CM_ "AUTOGENERATED FILE, DO NOT EDIT";

CM_ "Imported file _vw_meb_common.dbc starts here";
VERSION ""

NS_ :

BS_:

BU_: BAP_Tester BedienDisp_vo BedienSG_hi CGS DDA Gateway Gateway_PAG GurtMikrofon OTA_FC ZR_High ZR_LIMU ZR_MIB_TOP_ab_Gen3 ZR_Standard

BO_ 64 Airbag_01: 8 Gateway
 SG_ Airbag_01_CRC : 0|8@1+ (1,0) [0|255] "" AWC,BMC_MLBevo,BMS_NV,DCDC_800V_PAG,DCDC_HV,DCDC_HV_02,DCDC_IHEV,FCU_MLBevo_FCEV,Ladegeraet_2,Ladegeraet_Konzern,Sub_Gateway
 SG_ Airbag_01_BZ : 8|4@1+ (1,0) [0|15] "" AWC,BMC_MLBevo,BMS_NV,DCDC_800V_PAG,DCDC_HV,DCDC_HV_02,DCDC_IHEV,FCU_MLBevo_FCEV,Ladegeraet_2,Ladegeraet_Konzern,Sub_Gateway
 SG_ FROM_RGS_Anst : 12|4@1+ (1,0) [0|15] "" FCU_MLBevo_FCEV,Sub_Gateway
 SG_ FROM_Front_Crash : 16|1@1+ (1,0) [0|1] "" FCU_MLBevo_FCEV,Sub_Gateway
 SG_ FROM_Rear_Crash : 17|1@1+ (1,0) [0|1] "" FCU_MLBevo_FCEV,Sub_Gateway
 SG_ FROM_SF_Crash : 18|1@1+ (1,0) [0|1] "" FCU_MLBevo_FCEV,Sub_Gateway
 SG_ FROM_SB_Crash : 19|1@1+ (1,0) [0|1] "" FCU_MLBevo_FCEV,Sub_Gateway
 SG_ FROM_Rollover_Crash : 20|1@1+ (1,0) [0|1] "" FCU_MLBevo_FCEV,Sub_Gateway
 SG_ FROM_Crash_Int : 21|3@1+ (1,0) [0|7] "" FCU_MLBevo_FCEV,Sub_Gateway,TME
 SG_ FROM_Lamp : 24|1@1+ (1,0) [0|1] "" FCU_MLBevo_FCEV,Sub_Gateway
 SG_ FROM_Deactivated : 25|1@1+ (1,0) [0|1] "" FCU_MLBevo_FCEV,Sub_Gateway
 SG_ FROM_VB_Deactivated : 26|1@1+ (1,0) [0|1] "" FCU_MLBevo_FCEV,Sub_Gateway
 SG_ FROM_SystemError : 27|1@1+ (1,0) [0|1] "" FCU_MLBevo_FCEV,Sub_Gateway
 SG_ FROM_Diagnostics : 28|1@1+ (1,0) [0|1] "" FCU_MLBevo_FCEV,Sub_Gateway
 SG_ FROM_ActuatorTest : 29|1@1+ (1,0) [0|1] "" FCU_MLBevo_FCEV,Sub_Gateway,TME
 SG_ FROM_Erh_Open_VB : 30|2@1+ (1,0) [0|3] "" FCU_MLBevo_FCEV,Sub_Gateway
 SG_ FROM_BeltWarn_VF : 32|1@1+ (1,0) [0|1] "" FCU_MLBevo_FCEV,Sub_Gateway
 SG_ FROM_BeltWarn_VB : 33|1@1+ (1,0) [0|1] "" FCU_MLBevo_FCEV,Sub_Gateway
 SG_ FROM_Display_Pedestrian : 34|2@1+ (1,0) [0|3] "" FCU_MLBevo_FCEV,Sub_Gateway
 SG_ FROM_Texte_AKS : 36|2@1+ (1,0) [0|3] "" FCU_MLBevo_FCEV,Sub_Gateway
 SG_ FROM_MKB_Valid : 39|1@1+ (1,0) [0|1] "" FCU_MLBevo_FCEV,Sub_Gateway
 SG_ FROM_MKB_Request : 40|1@1+ (1,0) [0|1] "" FCU_MLBevo_FCEV,Sub_Gateway
 SG_ FROM_SupplyVoltage : 41|1@1+ (1,0) [0|1] "" FCU_MLBevo_FCEV,Sub_Gateway
 SG_ FROM_Deactivation_HV : 42|3@1+ (1,0) [0|7] "" AWC,BMC_MLBevo,BMS_NV,DCDC_800V_PAG,DCDC_HV,DCDC_HV_02,DCDC_IHEV,FCU_MLBevo_FCEV,Ladegeraet_2,Ladegeraet_Konzern,Sub_Gateway,TME
 SG_ FROM_EDR_Trigger : 45|2@1+ (1,0) [0|3] "" FCU_MLBevo_FCEV,Sub_Gateway
 SG_ FROM_Occupancy_VF : 47|2@1+ (1,0) [0|3] "" FCU_MLBevo_FCEV,Sub_Gateway
 SG_ SC_MasterTime_Offset : 53|2@1+ (5.08,0) [0|15.24] "Unit_Secon" FCU_MLBevo_FCEV,Sub_Gateway
 SG_ SC_LowSpeedCrashDetected : 55|2@1+ (1,0) [0|3] "" FCU_MLBevo_FCEV,Sub_Gateway
 SG_ SC_MasterTime : 57|7@1+ (0.04,0) [0|5.04] "Unit_Secon" FCU_MLBevo_FCEV,Sub_Gateway

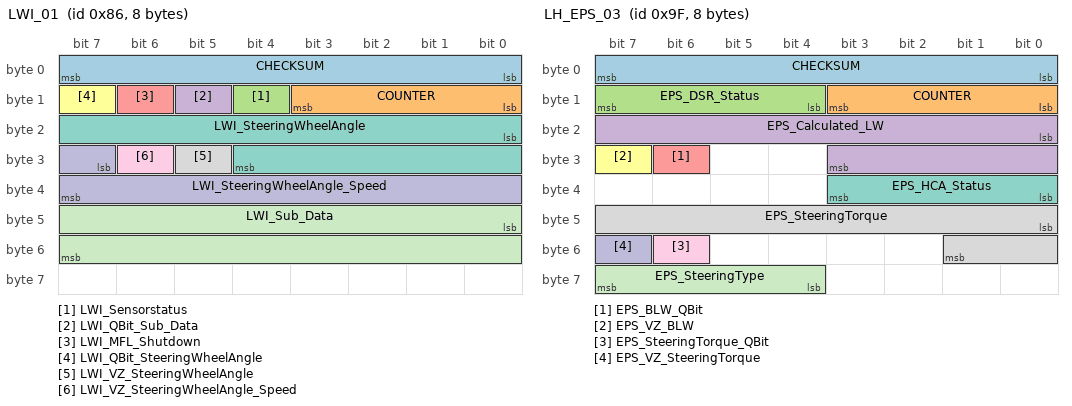
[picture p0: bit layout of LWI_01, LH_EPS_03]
BO_ 134 LWI_01: 8 Gateway
 SG_ CHECKSUM : 0|8@1+ (1,0) [0|255] "" Vector__XXX
 SG_ COUNTER : 8|4@1+ (1,0) [0|15] "" Vector__XXX
 SG_ LWI_Sensorstatus : 12|1@1+ (1,0) [0|1] "" ZR_High,ZR_LIMU,ZR_MIB_TOP_ab_Gen3,ZR_Standard
 SG_ LWI_QBit_Sub_Data : 13|1@1+ (1,0) [0|1] "" ZR_High
 SG_ LWI_MFL_Shutdown : 14|1@1+ (1,0) [0|1] "" ZR_High
 SG_ LWI_QBit_SteeringWheelAngle : 15|1@1+ (1,0) [0|1] "" ZR_High,ZR_LIMU,ZR_MIB_TOP_ab_Gen3,ZR_Standard
 SG_ LWI_SteeringWheelAngle : 16|13@1+ (0.0843,0) [0|800] "Unit_DegreOfArc" OTA_FC,ZR_High,ZR_LIMU,ZR_MIB_TOP_ab_Gen3,ZR_Standard
 SG_ LWI_VZ_SteeringWheelAngle : 29|1@1+ (1,0) [0|1] "" OTA_FC,ZR_High,ZR_LIMU,ZR_MIB_TOP_ab_Gen3,ZR_Standard
 SG_ LWI_VZ_SteeringWheelAngle_Speed : 30|1@1+ (1,0) [0|1] "" ZR_High
 SG_ LWI_SteeringWheelAngle_Speed : 31|9@1+ (5,0) [0|2500] "Unit_DegreOfArcPerSecon" OTA_FC,ZR_High
 SG_ LWI_Sub_Data : 40|16@1+ (1,0) [0|65535] "" Vector__XXX

BO_ 159 LH_EPS_03: 8 XXX
 SG_ CHECKSUM : 0|8@1+ (1,0) [0|255] "" XXX
 SG_ COUNTER : 8|4@1+ (1,0) [0|15] "" XXX
 SG_ EPS_DSR_Status : 12|4@1+ (1,0) [0|15] "" XXX
 SG_ EPS_Calculated_LW : 16|12@1+ (0.15,0) [0|613.95] "Unit_DegreOfArc" XXX
 SG_ EPS_BLW_QBit : 30|1@1+ (1,0) [0|1] "" XXX
 SG_ EPS_VZ_BLW : 31|1@1+ (1,0) [0|1] "" XXX
 SG_ EPS_HCA_Status : 32|4@1+ (1,0) [0|15] "" XXX
 SG_ EPS_SteeringTorque : 40|10@1+ (1,0) [0|8] "Unit_centiNewtoMeter" XXX
 SG_ EPS_SteeringTorque_QBit : 54|1@1+ (1,0) [0|1] "" XXX
 SG_ EPS_VZ_SteeringTorque : 55|1@1+ (1,0) [0|1] "" XXX
 SG_ EPS_SteeringType : 60|4@1+ (1,0) [0|15] "" XXX

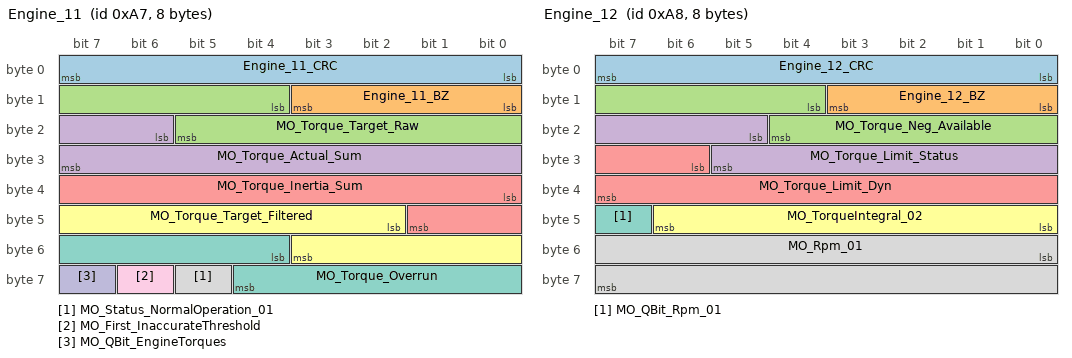
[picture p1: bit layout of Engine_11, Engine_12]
BO_ 167 Engine_11: 8 Motor_Diesel_MQB
 SG_ Engine_11_CRC : 0|8@1+ (1,0) [0|255] "" Gateway_MQB,Getriebe_DQ_Hybrid_MQB,Getriebe_DQ_MQB
 SG_ Engine_11_BZ : 8|4@1+ (1,0) [0|15] "" Gateway_MQB,Getriebe_DQ_Hybrid_MQB,Getriebe_DQ_MQB
 SG_ MO_Torque_Target_Raw : 12|10@1+ (1,-509) [-509|509] "Unit_NewtoMeter" Gateway_MQB,Getriebe_DQ_Hybrid_MQB,Getriebe_DQ_MQB
 SG_ MO_Torque_Actual_Sum : 22|10@1+ (1,-509) [-509|509] "Unit_NewtoMeter" Gateway_MQB,Getriebe_DQ_Hybrid_MQB,Getriebe_DQ_MQB,SAK_MQB
 SG_ MO_Torque_Inertia_Sum : 32|10@1+ (1,-509) [-509|509] "Unit_NewtoMeter" Gateway_MQB,Getriebe_DQ_Hybrid_MQB,Getriebe_DQ_MQB
 SG_ MO_Torque_Target_Filtered : 42|10@1+ (1,-509) [-509|509] "Unit_NewtoMeter" Gateway_MQB,Getriebe_DQ_Hybrid_MQB,Getriebe_DQ_MQB
 SG_ MO_Torque_Overrun : 52|9@1+ (1,-509) [-509|0] "Unit_NewtoMeter" Gateway_MQB,Getriebe_DQ_Hybrid_MQB,Getriebe_DQ_MQB
 SG_ MO_Status_NormalOperation_01 : 61|1@1+ (1,0) [0|1] "" Gateway_MQB,Getriebe_DQ_Hybrid_MQB,Getriebe_DQ_MQB
 SG_ MO_First_InaccurateThreshold : 62|1@1+ (1,0) [0|1] "" Gateway_MQB
 SG_ MO_QBit_EngineTorques : 63|1@1+ (1,0) [0|1] "" Gateway_MQB,Getriebe_DQ_Hybrid_MQB,Getriebe_DQ_MQB

BO_ 168 Engine_12: 8 Motor_Diesel_MQB
 SG_ Engine_12_CRC : 0|8@1+ (1,0) [0|255] "" Gateway_MQB,Getriebe_DQ_Hybrid_MQB,Getriebe_DQ_MQB,LEH_MQB
 SG_ Engine_12_BZ : 8|4@1+ (1,0) [0|15] "" BMS_MQB,Gateway_MQB,Getriebe_DQ_Hybrid_MQB,Getriebe_DQ_MQB,LEH_MQB
 SG_ MO_Torque_Neg_Available : 12|9@1+ (1,-509) [-509|0] "Unit_NewtoMeter" Gateway_MQB
 SG_ MO_Torque_Limit_Status : 21|9@1+ (1,0) [0|509] "Unit_NewtoMeter" Gateway_MQB,Getriebe_DQ_Hybrid_MQB,Getriebe_DQ_MQB
 SG_ MO_Torque_Limit_Dyn : 30|10@1+ (1,-509) [-509|509] "Unit_NewtoMeter" Gateway_MQB
 SG_ MO_TorqueIntegral_02 : 40|7@1+ (1,0) [0|100] "Unit_PerCent" Gateway_MQB,Getriebe_DQ_Hybrid_MQB,Getriebe_DQ_MQB
 SG_ MO_QBit_Rpm_01 : 47|1@1+ (1,0) [0|1] "" BMS_MQB,Gateway_MQB,Getriebe_DQ_Hybrid_MQB,Getriebe_DQ_MQB,LEH_MQB
 SG_ MO_Rpm_01 : 48|16@1+ (0.25,0) [0|16383] "Unit_MinutInver" BMS_MQB,Gateway_MQB,Getriebe_DQ_Hybrid_MQB,Getriebe_DQ_MQB,LEH_MQB,SAK_MQB

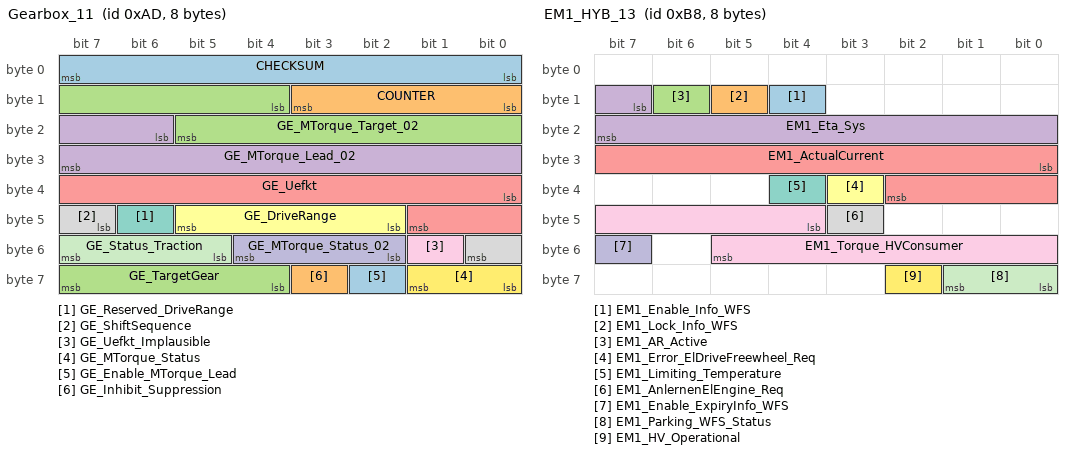
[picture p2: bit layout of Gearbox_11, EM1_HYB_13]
BO_ 173 Gearbox_11: 8 Gateway
 SG_ CHECKSUM : 0|8@1+ (1,0) [0|255] "" Vector__XXX
 SG_ COUNTER : 8|4@1+ (1,0) [0|15] "" Vector__XXX
 SG_ GE_MTorque_Target_02 : 12|10@1+ (1,-509) [-509|509] "" Vector__XXX
 SG_ GE_MTorque_Lead_02 : 22|10@1+ (1,-509) [-509|509] "" Vector__XXX
 SG_ GE_Uefkt : 32|10@1+ (0.1,0) [0|102.2] "" Vector__XXX
 SG_ GE_DriveRange : 42|4@1+ (1,0) [0|15] "" DDA,OTA_FC,ZR_High,ZR_LIMU,ZR_MIB_TOP_ab_Gen3
 SG_ GE_Reserved_DriveRange : 46|1@1+ (1,0) [0|1] "" Vector__XXX
 SG_ GE_ShiftSequence : 47|2@1+ (1,0) [0|3] "" Vector__XXX
 SG_ GE_Uefkt_Implausible : 49|1@1+ (1,0) [0|1] "" Vector__XXX
 SG_ GE_MTorque_Status_02 : 50|3@1+ (1,0) [0|7] "" Vector__XXX
 SG_ GE_Status_Traction : 53|3@1+ (1,0) [0|7] "" Vector__XXX
 SG_ GE_MTorque_Status : 56|2@1+ (1,0) [0|3] "" Vector__XXX
 SG_ GE_Enable_MTorque_Lead : 58|1@1+ (1,0) [0|1] "" Vector__XXX
 SG_ GE_Inhibit_Suppression : 59|1@1+ (1,0) [0|1] "" Vector__XXX
 SG_ GE_TargetGear : 60|4@1+ (1,0) [0|15] "" OTA_FC,ZR_High

BO_ 184 EM1_HYB_13: 8 Gateway
 SG_ EM1_Enable_Info_WFS : 12|1@1+ (1,0) [0|1] "" Sub_Gateway
 SG_ EM1_Lock_Info_WFS : 13|1@1+ (1,0) [0|1] "" Sub_Gateway
 SG_ EM1_AR_Active : 14|1@1+ (1,0) [0|1] "" Sub_Gateway
 SG_ EM1_Eta_Sys : 15|9@1+ (0.2,0) [0|101.8] "Unit_PerCent" Sub_Gateway
 SG_ EM1_ActualCurrent : 24|11@1+ (1,-1023) [-1023|1022] "Unit_Amper" Sub_Gateway
 SG_ EM1_Error_ElDriveFreewheel_Req : 35|1@1+ (1,0) [0|1] "" Sub_Gateway
 SG_ EM1_Limiting_Temperature : 36|1@1+ (1,0) [0|1] "" Sub_Gateway
 SG_ EM1_AnlernenElEngine_Req : 43|1@1+ (1,0) [0|1] "" Sub_Gateway
 SG_ EM1_Torque_HVConsumer : 44|10@1+ (1,-511) [-511|511] "Unit_NewtoMeter" Sub_Gateway
 SG_ EM1_Enable_ExpiryInfo_WFS : 55|1@1+ (1,0) [0|1] "" Sub_Gateway
 SG_ EM1_Parking_WFS_Status : 56|2@1+ (1,0) [0|3] "" Sub_Gateway
 SG_ EM1_HV_Operational : 58|1@1+ (1,0) [0|1] "" Sub_Gateway

BO_ 192 EM1_01: 32 XXX
 SG_ OverrunOperation : 79|1@0+ (1,0) [0|1] "" XXX

BO_ 219 AWV_03: 48 XXX
 SG_ CHECKSUM : 0|8@1+ (1,0) [0|255] "" XXX
 SG_ COUNTER : 8|4@1+ (1,0) [0|15] "" XXX
 SG_ AEB_Object_Status : 12|3@1+ (1,0) [0|7] "" XXX
 SG_ VRU_Detected : 15|1@1+ (1,0) [0|1] "" XXX
 SG_ AWV_Unavailable : 17|1@1+ (1,0) [0|1] "" XXX
 SG_ Unknown_18 : 18|6@1+ (1,0) [0|63] "" XXX
 SG_ AEB_Object_Status_B : 24|3@1+ (1,0) [0|7] "" XXX
 SG_ Unknown_27 : 27|5@1+ (1,0) [0|31] "" XXX
 SG_ SET_ME_254 : 32|8@1+ (1,0) [0|255] "" XXX
 SG_ AEB_TTC_Countdown : 40|8@1+ (1,0) [0|255] "" XXX
 SG_ Active : 64|1@1+ (1,0) [0|1] "" XXX
 SG_ AEB_Active : 65|1@1+ (1,0) [0|1] "" XXX
 SG_ AEB_Target_Decel : 66|10@1+ (0.01,-10.23) [-10.23|0] "Unit_MeterPerSeconSquar" XXX
 SG_ FCW_Active : 76|1@1+ (1,0) [0|1] "" XXX
 SG_ Unknown_80 : 80|8@1+ (1,0) [0|255] "" XXX
 SG_ AEB_Active_2 : 91|1@1+ (1,0) [0|1] "" XXX
 SG_ Unknown_93 : 93|7@1+ (1,0) [0|127] "" XXX
 SG_ Unknown_100 : 100|4@1+ (1,0) [0|15] "" XXX
 SG_ AWV_Init_Status : 128|2@1+ (1,0) [0|3] "" XXX
 SG_ Unknown_192 : 192|1@1+ (1,0) [0|1] "" XXX

BO_ 247 MEB_HVEM_02: 8 XXX
 SG_ CRC : 0|8@1+ (1,0) [0|255] "" XXX
 SG_ CNT : 8|4@1+ (1,0) [0|15] "" XXX

BO_ 253 ESP_21: 8 Gateway
 SG_ CHECKSUM : 0|8@1+ (1,0) [0|255] "" Vector__XXX
 SG_ COUNTER : 8|4@1+ (1,0) [0|15] "" Vector__XXX
 SG_ BR_InterventionTorque : 12|10@1+ (1,-509) [-509|509] "" Vector__XXX
 SG_ ESP_Diagnostics : 23|1@1+ (1,0) [0|1] "" ZR_High
 SG_ ESC_v_Signal_Qualifier_High_Low : 24|3@1+ (1,0) [0|7] "" Vector__XXX
 SG_ ESP_BeforeControl : 28|1@1+ (1,0) [0|1] "" Vector__XXX
 SG_ OBD_RoughRoad : 30|1@1+ (1,0) [0|1] "" ZR_High
 SG_ OBD_QBit_RoughRoad : 31|1@1+ (1,0) [0|1] "" ZR_High
 SG_ ESP_v_Signal : 32|16@1+ (0.01,0) [0|655.32] "Unit_KiloMeterPerHour" BedienSG_hi,DDA,OTA_FC,ZR_High,ZR_LIMU,ZR_MIB_TOP_ab_Gen3,ZR_Standard
 SG_ ASR_Keying_Passive : 48|1@1+ (1,0) [0|1] "" OTA_FC
 SG_ ESP_Keying_Passive : 49|1@1+ (1,0) [0|1] "" OTA_FC,ZR_High,ZR_LIMU,ZR_MIB_TOP_ab_Gen3
 SG_ ESP_SystemStatus : 50|1@1+ (1,0) [0|1] "" OTA_FC
 SG_ ASR_ShiftIntervention : 51|2@1+ (1,0) [0|3] "" Vector__XXX
 SG_ ESP_QBit_v_Signal : 55|1@1+ (1,0) [0|1] "" ZR_High,ZR_LIMU,ZR_MIB_TOP_ab_Gen3,ZR_Standard
 SG_ ABS_Braking : 56|1@1+ (1,0) [0|1] "" OTA_FC,ZR_High,ZR_LIMU,ZR_MIB_TOP_ab_Gen3
 SG_ ASR_Req : 57|1@1+ (1,0) [0|1] "" ZR_High
 SG_ MSR_Req : 58|1@1+ (1,0) [0|1] "" OTA_FC,ZR_High
 SG_ EBV_Intervention : 59|1@1+ (1,0) [0|1] "" Vector__XXX
 SG_ EDS_Intervention : 60|1@1+ (1,0) [0|1] "" Vector__XXX
 SG_ ESP_Intervention : 61|1@1+ (1,0) [0|1] "" OTA_FC,ZR_High
 SG_ ESP_ASP : 62|1@1+ (1,0) [0|1] "" ZR_High
 SG_ ESC_NeutralShift : 63|1@1+ (1,0) [0|1] "" Vector__XXX

BO_ 258 ESC_50: 48 XXX
 SG_ CHECKSUM : 0|8@1+ (1,0) [0|255] "" XXX
 SG_ COUNTER : 8|4@1+ (1,0) [0|15] "" XXX
 SG_ Lateral_Accel : 16|8@1+ (0.15,-18.9) [0|255] "Unit_MeterPerSquareSecond" XXX
 SG_ Longitudinal_Accel : 24|10@1+ (0.03125,-16) [0|255] "Unit_MeterPerSquareSecond" XXX
 SG_ Yaw_Rate : 40|14@1+ (0.01,0) [0|16383] "Unit_DegreePerSecond" XXX
 SG_ Yaw_Rate_Sign : 54|1@0+ (1,0) [0|1] "" XXX
 SG_ Brake_Power : 80|8@1+ (1,-100) [0|255] "" XXX
 SG_ Brake_01 : 90|1@0+ (1,0) [0|1] "" XXX
 SG_ Rain_Braking : 123|1@1+ (1,0) [0|7] "" XXX
 SG_ Brake_02 : 125|1@0+ (1,0) [0|1] "" XXX
 SG_ Standstill : 171|1@0+ (1,0) [0|1] "" XXX
 SG_ Motion_State : 171|2@0+ (1,0) [0|1] "" XXX
 SG_ Longitudinal_Speed : 181|10@1+ (0.25,0) [0|255] "Unit_KilometerPerHour" XXX
 SG_ Brake_Power_02 : 226|8@1+ (1,-100) [0|63] "" XXX
 SG_ EPB_Status : 317|3@1+ (1,0) [0|7] "" XXX

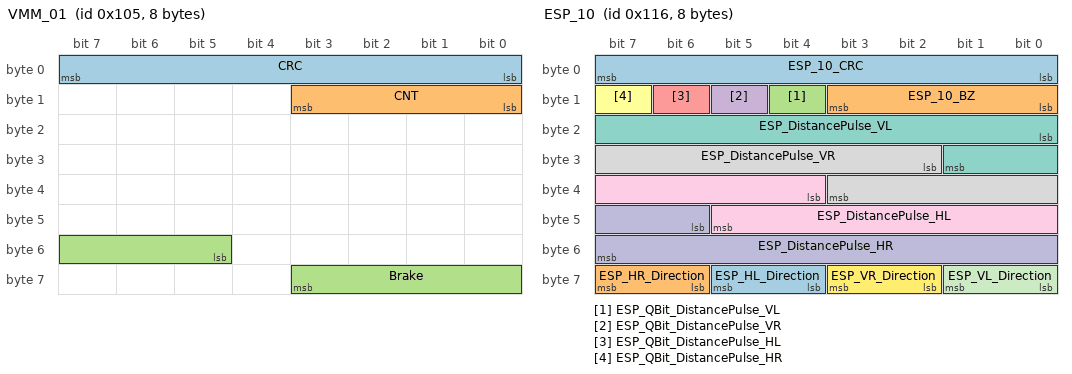
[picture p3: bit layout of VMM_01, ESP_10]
BO_ 261 VMM_01: 8 XXX
 SG_ CRC : 0|8@1+ (1,0) [0|255] "" XXX
 SG_ CNT : 8|4@1+ (1,0) [0|15] "" XXX
 SG_ Brake : 53|7@1+ (1,0) [0|3] "" XXX

BO_ 278 ESP_10: 8 Gateway_MQB
 SG_ ESP_10_CRC : 0|8@1+ (1,0) [0|255] "" Airbag_MQB,Motor_Diesel_MQB,Motor_Hybrid_MQB,Motor_Otto_MQB
 SG_ ESP_10_BZ : 8|4@1+ (1,0) [0|15] "" Airbag_MQB,Motor_Diesel_MQB,Motor_Hybrid_MQB,Motor_Otto_MQB
 SG_ ESP_QBit_DistancePulse_VL : 12|1@1+ (1,0) [0|1] "" Getriebe_DQ_Hybrid_MQB,Getriebe_DQ_MQB,Motor_Diesel_MQB,Motor_Hybrid_MQB,Motor_Otto_MQB
 SG_ ESP_QBit_DistancePulse_VR : 13|1@1+ (1,0) [0|1] "" Getriebe_DQ_Hybrid_MQB,Getriebe_DQ_MQB,Motor_Diesel_MQB,Motor_Hybrid_MQB,Motor_Otto_MQB
 SG_ ESP_QBit_DistancePulse_HL : 14|1@1+ (1,0) [0|1] "" Getriebe_DQ_Hybrid_MQB,Getriebe_DQ_MQB,Motor_Diesel_MQB,Motor_Hybrid_MQB,Motor_Otto_MQB
 SG_ ESP_QBit_DistancePulse_HR : 15|1@1+ (1,0) [0|1] "" Getriebe_DQ_Hybrid_MQB,Getriebe_DQ_MQB,Motor_Diesel_MQB,Motor_Hybrid_MQB,Motor_Otto_MQB
 SG_ ESP_DistancePulse_VL : 16|10@1+ (1,0) [0|1000] "" Getriebe_DQ_Hybrid_MQB,Getriebe_DQ_MQB,Motor_Diesel_MQB,Motor_Hybrid_MQB,Motor_Otto_MQB
 SG_ ESP_DistancePulse_VR : 26|10@1+ (1,0) [0|1000] "" Getriebe_DQ_Hybrid_MQB,Getriebe_DQ_MQB,Motor_Diesel_MQB,Motor_Hybrid_MQB,Motor_Otto_MQB
 SG_ ESP_DistancePulse_HL : 36|10@1+ (1,0) [0|1000] "" Getriebe_DQ_Hybrid_MQB,Getriebe_DQ_MQB,Motor_Diesel_MQB,Motor_Hybrid_MQB,Motor_Otto_MQB
 SG_ ESP_DistancePulse_HR : 46|10@1+ (1,0) [0|1000] "" Getriebe_DQ_Hybrid_MQB,Getriebe_DQ_MQB,Motor_Diesel_MQB,Motor_Hybrid_MQB,Motor_Otto_MQB
 SG_ ESP_VL_Direction : 56|2@1+ (1,0) [0|3] "" Airbag_MQB,Getriebe_DQ_Hybrid_MQB,Getriebe_DQ_MQB,Motor_Diesel_MQB,Motor_Hybrid_MQB,Motor_Otto_MQB
 SG_ ESP_VR_Direction : 58|2@1+ (1,0) [0|3] "" Airbag_MQB,Getriebe_DQ_Hybrid_MQB,Getriebe_DQ_MQB,Motor_Diesel_MQB,Motor_Hybrid_MQB,Motor_Otto_MQB
 SG_ ESP_HL_Direction : 60|2@1+ (1,0) [0|3] "" Airbag_MQB,Getriebe_DQ_Hybrid_MQB,Getriebe_DQ_MQB,Motor_Diesel_MQB,Motor_Hybrid_MQB,Motor_Otto_MQB
 SG_ ESP_HR_Direction : 62|2@1+ (1,0) [0|3] "" Airbag_MQB,Getriebe_DQ_Hybrid_MQB,Getriebe_DQ_MQB,Motor_Diesel_MQB,Motor_Hybrid_MQB,Motor_Otto_MQB

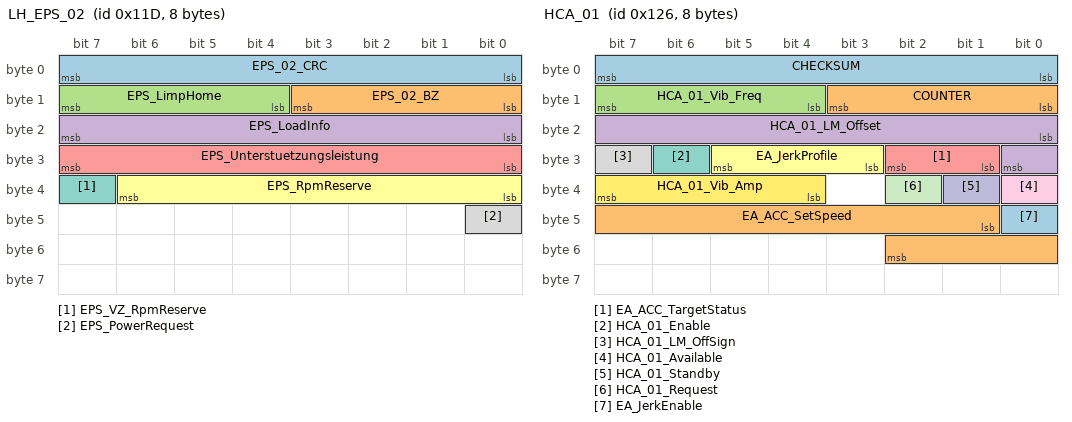
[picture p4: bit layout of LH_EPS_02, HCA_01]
BO_ 285 LH_EPS_02: 8 Gateway_D4C7
 SG_ EPS_02_CRC : 0|8@1+ (1,0) [0|255] "" SCU_D4
 SG_ EPS_02_BZ : 8|4@1+ (1,0) [0|15] "" SCU_D4
 SG_ EPS_LimpHome : 12|4@1+ (1,0) [0|15] "" Vector__XXX
 SG_ EPS_LoadInfo : 16|8@1+ (1,0) [0|253] "Unit_Amper" Vector__XXX
 SG_ EPS_Unterstuetzungsleistung : 24|8@1+ (0.5,0) [0|100] "Unit_PerCent" SCU_D4
 SG_ EPS_RpmReserve : 32|7@1+ (10,0) [0|1000] "Unit_DegreOfArcPerSecon" SCU_D4
 SG_ EPS_VZ_RpmReserve : 39|1@1+ (1,0) [0|1] "" SCU_D4
 SG_ EPS_PowerRequest : 40|1@1+ (1,0) [0|1] "" Vector__XXX

BO_ 294 HCA_01: 8 Frontsensorik
 SG_ CHECKSUM : 0|8@1+ (1,0) [0|255] "" Vector__XXX
 SG_ COUNTER : 8|4@1+ (1,0) [0|15] "" Vector__XXX
 SG_ HCA_01_Vib_Freq : 12|4@1+ (1,15) [18|30] "Unit_Hertz" Vector__XXX
 SG_ HCA_01_LM_Offset : 16|9@1+ (1,0) [0|511] "Unit_centiNewtoMeter" Vector__XXX
 SG_ EA_ACC_TargetStatus : 25|2@1+ (1,0) [0|3] "" Frontradar
 SG_ EA_JerkProfile : 27|3@1+ (1,0) [0|7] "" Vector__XXX
 SG_ HCA_01_Enable : 30|1@1+ (1,0) [0|1] "" Vector__XXX
 SG_ HCA_01_LM_OffSign : 31|1@1+ (1,0) [0|1] "" Vector__XXX
 SG_ HCA_01_Available : 32|1@1+ (1,0) [0|1] "" Vector__XXX
 SG_ HCA_01_Standby : 33|1@1+ (1,0) [0|1] "" Vector__XXX
 SG_ HCA_01_Request : 34|1@1+ (1,0) [0|1] "" Vector__XXX
 SG_ HCA_01_Vib_Amp : 36|4@1+ (0.2,0) [0|3] "Unit_NewtoMeter" Vector__XXX
 SG_ EA_JerkEnable : 40|1@1+ (1,0) [0|1] "" Vector__XXX
 SG_ EA_ACC_SetSpeed : 41|10@1+ (0.32,0) [0|327.04] "Unit_KiloMeterPerHour" Frontradar

BO_ 299 GRA_ACC_01: 8 Gateway
 SG_ CHECKSUM : 0|8@1+ (1,0) [0|255] "" Vector__XXX
 SG_ COUNTER : 8|4@1+ (1,0) [0|15] "" Vector__XXX
 SG_ GRA_MainSwitch : 12|1@1+ (1,0) [0|1] "" ZR_High
 SG_ GRA_Cancel : 13|1@1+ (1,0) [0|1] "" ZR_High
 SG_ GRA_Type_MainSwitch : 14|1@1+ (1,0) [0|1] "" ZR_High
 SG_ GRA_Limiter : 15|1@1+ (1,0) [0|1] "" ZR_High
 SG_ GRA_Tip_Set : 16|1@1+ (1,0) [0|1] "" ZR_High
 SG_ GRA_Tip_High : 17|1@1+ (1,0) [0|1] "" ZR_High
 SG_ GRA_Tip_Down : 18|1@1+ (1,0) [0|1] "" ZR_High
 SG_ GRA_Tip_Resume : 19|1@1+ (1,0) [0|1] "" ZR_High
 SG_ GRA_Adjustment_TimeGap : 20|2@1+ (1,0) [0|3] "" ZR_High
 SG_ GRA_Coding : 22|2@1+ (1,0) [0|3] "" ZR_High
 SG_ GRA_Error : 24|1@1+ (1,0) [0|1] "" ZR_High
 SG_ GRA_LIM_Key_Available : 25|1@1+ (1,0) [0|1] "" ZR_High
 SG_ GRA_Tip_Stage_2 : 26|1@1+ (1,0) [0|1] "" ZR_High
 SG_ GRA_ButtonTypeInfo : 27|3@1+ (1,0) [0|7] "" ZR_High
 SG_ GRA_TravelAssist : 30|1@1+ (1,0) [0|1] "" Vector__XXX
 SG_ GRA_ReserveByte4 : 31|1@1+ (1,0) [0|1] "" Vector__XXX
 SG_ GRA_ReserveByte5 : 32|8@1+ (1,0) [0|255] "" Vector__XXX
 SG_ GRA_ReserveByte6 : 40|8@1+ (1,0) [0|255] "" Vector__XXX
 SG_ GRA_ReserveByte7 : 48|8@1+ (1,0) [0|255] "" Vector__XXX
 SG_ GRA_ReserveByte8 : 56|8@1+ (1,0) [0|255] "" Vector__XXX

BO_ 312 IPA_01: 32 XXX

BO_ 313 VMM_02: 32 XXX
 SG_ CHECKSUM : 0|8@1+ (1,0) [0|255] "" XXX
 SG_ COUNTER : 8|4@1+ (1,0) [0|15] "" XXX
 SG_ FCW_Reaction_1 : 12|1@0+ (1,0) [0|1] "" XXX
 SG_ Brake_Pressed_1 : 16|1@0+ (1,0) [0|1] "" XXX
 SG_ Brake_Pressed_2 : 27|1@0+ (1,0) [0|1] "" XXX
 SG_ AEB_Active : 31|1@0+ (1,0) [0|1] "" XXX
 SG_ ESP_Hold : 35|1@0+ (1,0) [0|1] "" XXX
 SG_ Brake_Pressed_3 : 48|1@0+ (1,0) [0|1] "" XXX
 SG_ Long_Control_Inhibit : 52|2@1+ (1,0) [0|3] "" XXX
 SG_ FCW_Reaction_2 : 56|1@1+ (1,0) [0|1] "" XXX
 SG_ Brake_Pressure : 76|11@1+ (1,0) [0|100] "" XXX
 SG_ FCW_Reaction_3 : 88|5@1+ (1,0) [0|31] "" XXX

BO_ 317 QFK_01: 32 XXX
 SG_ CHECKSUM : 0|8@1+ (1,0) [0|255] "" XXX
 SG_ COUNTER : 8|4@1+ (1,0) [0|15] "" XXX
 SG_ HCA_No_Override : 14|1@0+ (1,0) [0|1] "" XXX
 SG_ LatCon_HCA_Accept : 17|2@1+ (1,0) [0|3] "" XXX
 SG_ LatCon_HCA_Status : 20|3@1+ (1,0) [0|15] "" XXX
 SG_ Steering_Angle_VZ : 36|1@0+ (1,0) [0|1] "" XXX
 SG_ Curvature : 40|15@1+ (6.7e-06,0) [0|65535] "" XXX
 SG_ Curvature_VZ : 55|1@0+ (1,0) [0|1] "" XXX
 SG_ Steering_Angle : 76|17@1+ (0.00906,0) [0|32767] "" XXX

BO_ 319 PreCrash_02: 8 Gateway
 SG_ PreCrash_02_CRC : 0|8@1+ (1,0) [0|255] "" Vector__XXX
 SG_ PreCrash_02_BZ : 8|4@1+ (1,0) [0|15] "" Vector__XXX
 SG_ PreCrash_Charisma_DrivePr : 12|4@1+ (1,0) [0|15] "" Vector__XXX
 SG_ PreCrash_Charisma_Status : 16|2@1+ (1,0) [0|3] "" Vector__XXX
 SG_ PreCrash_Sunroof_Close : 18|1@1+ (1,0) [0|1] "" Vector__XXX
 SG_ PreCrash_Window_Close : 19|1@1+ (1,0) [0|1] "" Vector__XXX
 SG_ PreCrash_Flash : 20|3@1+ (1,0) [0|7] "" Vector__XXX
 SG_ SC_PreSense_FCWP : 23|1@1+ (1,0) [0|1] "" NightVision
 SG_ PreCrash_Doors_Lock : 24|1@1+ (1,0) [0|1] "" Vector__XXX
 SG_ PreCrash_Request_AFR : 26|3@1+ (1,0) [0|7] "" Vector__XXX
 SG_ SC_PreCrash_LED : 29|2@1+ (1,0) [0|3] "" Vector__XXX
 SG_ PreCrash_FS_Pneumatic_Actuate : 31|1@1+ (1,0) [0|1] "" Vector__XXX
 SG_ PreCrash_BFS_Pneumatic_Actuate : 32|1@1+ (1,0) [0|1] "" Vector__XXX
 SG_ PreCrash_Fo_Pneumatic_Actuate : 33|1@1+ (1,0) [0|1] "" Vector__XXX
 SG_ PreCrash_FS_Backrest_Procedure : 34|3@1+ (1,0) [0|7] "" Vector__XXX
 SG_ PreCrash_BFS_Backrest_Procedure : 37|3@1+ (1,0) [0|7] "" Vector__XXX
 SG_ PreCrash_Fo_Backrest_Procedure : 40|3@1+ (1,0) [0|7] "" Vector__XXX
 SG_ PreCrash_FS_KSV_Procedure : 43|4@1+ (1,0) [0|15] "" Vector__XXX
 SG_ PreCrash_BFS_KSV_Procedure : 47|4@1+ (1,0) [0|15] "" Vector__XXX
 SG_ PreCrash_Fo_KSV_Procedure : 51|4@1+ (1,0) [0|15] "" Vector__XXX
 SG_ SC_PreCrash_Warning : 56|4@1+ (1,0) [0|15] "" NightVision
 SG_ SC_PreCrash_Texte : 60|4@1+ (1,0) [0|15] "" Vector__XXX

BO_ 332 Engine_54: 32 XXX
 SG_ CHECKSUM : 0|8@1+ (1,0) [0|255] "" XXX
 SG_ COUNTER : 8|4@1+ (1,0) [0|15] "" XXX
 SG_ Engine_On : 77|1@1+ (1,0) [0|1] "" XXX
 SG_ Accelerator_Pressure : 175|8@0+ (0.4,-14.8) [0|100] "Unit_Percent" XXX

BO_ 333 ACC_18: 32 XXX
 SG_ CHECKSUM : 0|8@1+ (1,0) [0|255] "" XXX
 SG_ COUNTER : 8|4@1+ (1,0) [0|15] "" XXX
 SG_ ACC_Limited_PullAwayDyn : 12|1@1+ (1,0) [0|1] "" XXX
 SG_ ACC_Retrofit_Stop_Req : 13|1@1+ (1,0) [0|1] "" XXX
 SG_ ACC_DynIncrease : 14|1@1+ (1,0) [0|1] "" XXX
 SG_ ACC_FreewheelStrategy_TSK : 15|1@1+ (1,0) [0|1] "" XXX
 SG_ ACC_Allowed_ControlDeviation_Bottom : 16|6@1+ (0.024,0) [0|1.512] "Unit_MeterPerSeconSquar" XXX
 SG_ ACC_StartStop_Info : 22|2@1+ (1,0) [0|3] "" XXX
 SG_ ACC_TargetAcceleration_02 : 24|11@1+ (0.005,-7.22) [-7.22|3.005] "Unit_MeterPerSeconSquar" XXX
 SG_ ACC_Allowed_ControlDeviation_Top : 35|5@1+ (0.0625,0) [0|1.9375] "Unit_MeterPerSeconSquar" XXX
 SG_ ACC_Neg_TargetAccel_Degree_02 : 40|8@1+ (0.05,0) [0|12.75] "Unit_MeterPerCubicSecon" XXX
 SG_ ACC_pos_TargetAccel_Degree_02 : 48|8@1+ (0.05,0) [0|12.75] "Unit_MeterPerCubicSecon" XXX
 SG_ ACC_PullAway : 56|1@1+ (1,0) [0|1] "" XXX
 SG_ ACC_Stop : 57|1@1+ (1,0) [0|1] "" XXX
 SG_ ACC_Type : 58|2@1+ (1,0) [0|3] "" XXX
 SG_ ACC_Status_ACC : 60|3@1+ (1,0) [0|7] "" XXX
 SG_ ACC_Minimum_Braking : 63|1@1+ (1,0) [0|1] "" XXX
 SG_ ACC_StoppingDistance : 64|11@1+ (0.01,0) [0|2046] "" XXX
 SG_ ACC_Request_HMS : 77|3@1+ (1,0) [0|7] "" XXX
 SG_ SET_ME_0XFE : 80|8@1+ (1,0) [0|255] "" XXX
 SG_ ACC_Active_Controls : 90|1@0+ (1,0) [0|1] "" XXX
 SG_ SET_ME_0X1 : 92|1@0+ (1,0) [0|1] "" XXX
 SG_ SET_ME_0x2FE : 98|10@1+ (1,0) [0|63] "" XXX
 SG_ SET_ME_0X9 : 232|4@1+ (1,0) [0|15] "" XXX
 SG_ Speed : 236|12@1+ (0.1,0) [0|15] "" XXX
 SG_ Accel_Boost : 248|6@1+ (1,0) [0|3] "" XXX
 SG_ Reversing : 254|1@0+ (1,0) [0|1] "" XXX

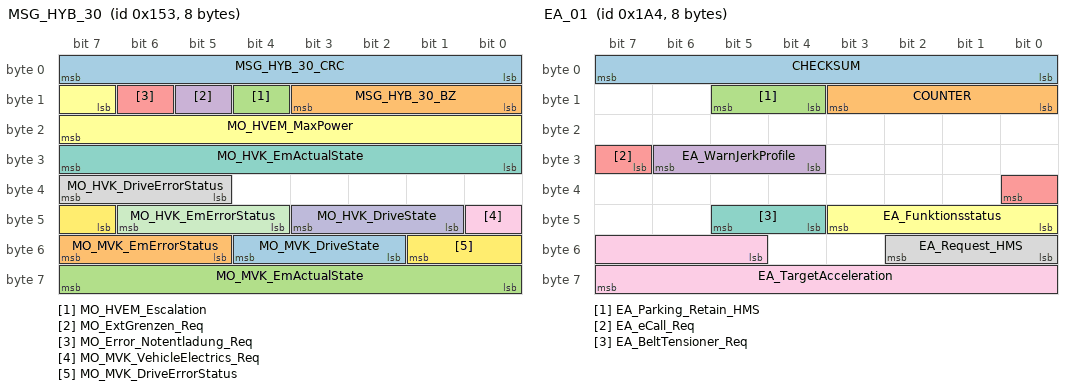
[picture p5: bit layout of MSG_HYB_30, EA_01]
BO_ 339 MSG_HYB_30: 8 Gateway
 SG_ MSG_HYB_30_CRC : 0|8@1+ (1,0) [0|255] "" Ladegeraet_Konzern
 SG_ MSG_HYB_30_BZ : 8|4@1+ (1,0) [0|15] "" Ladegeraet_Konzern
 SG_ MO_HVEM_Escalation : 12|1@1+ (1,0) [0|1] "" Vector__XXX
 SG_ MO_ExtGrenzen_Req : 13|1@1+ (1,0) [0|1] "" BMC_MLBevo
 SG_ MO_Error_Notentladung_Req : 14|1@1+ (1,0) [0|1] "" Vector__XXX
 SG_ MO_HVEM_MaxPower : 15|9@1+ (50,0) [0|25450] "Unit_Watt" Vector__XXX
 SG_ MO_HVK_EmActualState : 24|8@1+ (1,0) [0|255] "" Vector__XXX
 SG_ MO_HVK_DriveErrorStatus : 37|3@1+ (1,0) [0|7] "" Vector__XXX
 SG_ MO_MVK_VehicleElectrics_Req : 40|1@1+ (1,0) [0|1] "" Vector__XXX
 SG_ MO_HVK_DriveState : 41|3@1+ (1,0) [0|7] "" TME
 SG_ MO_HVK_EmErrorStatus : 44|3@1+ (1,0) [0|7] "" Vector__XXX
 SG_ MO_MVK_DriveErrorStatus : 47|3@1+ (1,0) [0|7] "" Vector__XXX
 SG_ MO_MVK_DriveState : 50|3@1+ (1,0) [0|7] "" Vector__XXX
 SG_ MO_MVK_EmErrorStatus : 53|3@1+ (1,0) [0|7] "" Vector__XXX
 SG_ MO_MVK_EmActualState : 56|8@1+ (1,0) [0|255] "" Vector__XXX

BO_ 387 MEB_Camera_01: 64 XXX
 SG_ Lane_Center_Offset : 256|12@1+ (0.001,-2.5) [0|255] "Unit_Meter" XXX

BO_ 420 EA_01: 8 Gateway
 SG_ CHECKSUM : 0|8@1+ (1,0) [0|255] "" Vector__XXX
 SG_ COUNTER : 8|4@1+ (1,0) [0|15] "" Vector__XXX
 SG_ EA_Parking_Retain_HMS : 12|2@1+ (1,0) [0|3] "" Vector__XXX
 SG_ EA_WarnJerkProfile : 28|3@1+ (1,0) [0|7] "" Vector__XXX
 SG_ EA_eCall_Req : 31|2@1+ (1,0) [0|3] "" ZR_High
 SG_ EA_Funktionsstatus : 40|4@1+ (1,0) [0|15] "" ZR_High
 SG_ EA_BeltTensioner_Req : 44|2@1+ (1,0) [0|3] "" Vector__XXX
 SG_ EA_Request_HMS : 48|3@1+ (1,0) [0|7] "" Vector__XXX
 SG_ EA_TargetAcceleration : 53|11@1+ (0.005,-7.22) [-7.22|3.005] "Unit_MeterPerSeconSquar" Vector__XXX

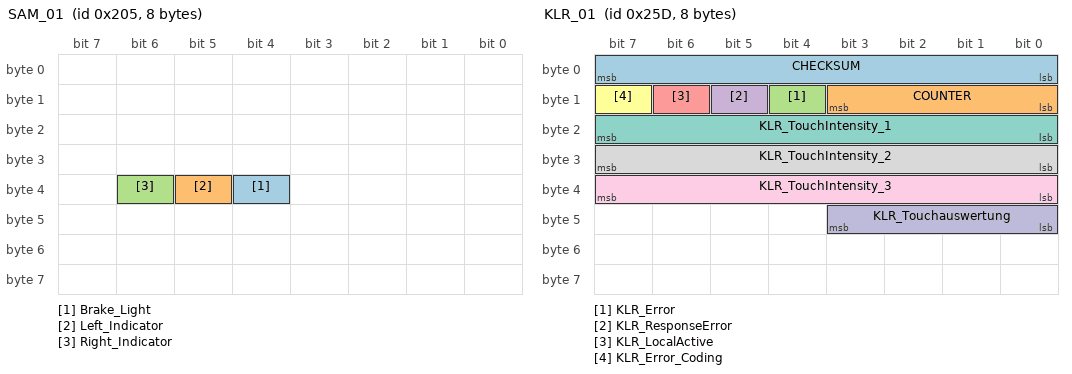
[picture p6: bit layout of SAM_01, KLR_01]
BO_ 517 SAM_01: 8 XXX
 SG_ Brake_Light : 36|1@0+ (1,0) [0|1] "" XXX
 SG_ Left_Indicator : 37|1@0+ (1,0) [0|1] "" XXX
 SG_ Right_Indicator : 38|1@0+ (1,0) [0|1] "" XXX

BO_ 518 Parking_01: 24 XXX
 SG_ CHK : 0|8@1+ (1,0) [0|255] "" XXX
 SG_ CNT : 8|4@1+ (1,0) [0|15] "" XXX
 SG_ AEB_Active : 16|1@0+ (1,0) [0|1] "" XXX

BO_ 522 EML_06: 64 XXX
 SG_ CHECKSUM : 0|8@1+ (1,0) [0|255] "" XXX
 SG_ COUNTER : 8|4@1+ (1,0) [0|15] "" XXX
 SG_ Yaw_Rate_VZ : 33|1@1+ (1,0) [0|1] "" XXX
 SG_ Yaw_Rate : 200|16@1+ (0.007,-229.34) [0|255] "" XXX

BO_ 564 MEB_Camera_02: 64 XXX

BO_ 588 MEB_Side_Assist_01: 16 XXX
 SG_ Blind_Spot_Passenger : 12|7@1+ (1,0) [0|15] "" XXX
 SG_ Blind_Spot_Driver : 19|7@1+ (1,0) [0|15] "" XXX
 SG_ Blind_Spot_Info_Passenger : 26|1@0+ (1,0) [0|1] "" XXX
 SG_ Blind_Spot_Warn_Passenger : 27|1@0+ (1,0) [0|1] "" XXX
 SG_ Blind_Spot_Info_Driver : 29|1@0+ (1,0) [0|1] "" XXX
 SG_ Blind_Spot_Warn_Driver : 30|1@0+ (1,0) [0|1] "" XXX
 SG_ Lower_Speed_01 : 32|1@0+ (1,0) [0|1] "" XXX
 SG_ Higher_Speed_01 : 33|1@0+ (1,0) [0|1] "" XXX
 SG_ Higher_Speed_02 : 83|1@0+ (1,0) [0|1] "" XXX
 SG_ Lower_Speed_02 : 84|1@0+ (1,0) [0|1] "" XXX
 SG_ Standstill : 86|1@0+ (1,0) [0|1] "" XXX

BO_ 589 MEB_Side_Assist_02: 64 XXX
 SG_ Unknown_01 : 100|3@0+ (1,0) [0|7] "" XXX
 SG_ Unknown_02 : 108|3@0+ (1,0) [0|7] "" XXX

BO_ 591 MEB_Distance_01: 64 XXX
 SG_ Unknown_01 : 12|1@0+ (1,0) [0|1] "" XXX
 SG_ Distance_Status : 13|2@1+ (1,0) [0|3] "" XXX
 SG_ Same_Lane_01_ObjectID : 16|6@1+ (1,0) [0|63] "Unit_ObjectID" XXX
 SG_ Left_Lane_01_ObjectID : 22|6@1+ (1,0) [0|63] "Unit_ObjectID" XXX
 SG_ Right_Lane_01_ObjectID : 28|6@1+ (1,0) [0|63] "Unit_ObjectID" XXX
 SG_ Same_Lane_02_ObjectID : 34|6@1+ (1,0) [0|63] "Unit_ObjectID" XXX
 SG_ Left_Lane_02_ObjectID : 40|6@1+ (1,0) [0|63] "Unit_ObjectID" XXX
 SG_ Right_Lane_02_ObjectID : 46|6@1+ (1,0) [0|63] "Unit_ObjectID" XXX
 SG_ Unknown_02 : 52|2@1+ (1,0) [0|3] "" XXX
 SG_ Unknown_03 : 54|10@1+ (1,0) [0|3] "" XXX
 SG_ Same_Lane_01_Long_Distance : 64|12@1+ (0.0625,-3.75) [0|300] "Unit_Meter" XXX
 SG_ Same_Lane_01_Lat_Distance : 76|10@1+ (0.065,-33.28) [-50|50] "Unit_Meter" XXX
 SG_ Same_Lane_01_Rel_Velo : 86|10@1+ (0.25,-128) [-150|150] "Unit_MeterPerSecond" XXX
 SG_ Left_Lane_01_Long_Distance : 96|12@1+ (0.0625,-3.75) [0|300] "Unit_Meter" XXX
 SG_ Left_Lane_01_Lat_Distance : 108|10@1+ (0.065,-33.28) [-50|50] "Unit_Meter" XXX
 SG_ Left_Lane_01_Rel_Velo : 118|10@1+ (0.25,-128) [-150|150] "Unit_MeterPerSecond" XXX
 SG_ Right_Lane_01_Long_Distance : 128|12@1+ (0.0625,-3.75) [0|300] "Unit_Meter" XXX
 SG_ Right_Lane_01_Lat_Distance : 140|10@1+ (0.065,-33.28) [-50|50] "Unit_Meter" XXX
 SG_ Right_Lane_01_Rel_Velo : 150|10@1+ (0.25,-128) [-150|150] "Unit_MeterPerSecond" XXX
 SG_ Same_Lane_02_Long_Distance : 160|12@1+ (0.0625,-3.75) [0|300] "Unit_Meter" XXX
 SG_ Same_Lane_02_Lat_Distance : 172|10@1+ (0.065,-33.28) [-50|50] "Unit_Meter" XXX
 SG_ Same_Lane_02_Rel_Velo : 182|10@1+ (0.25,-128) [-150|150] "Unit_MeterPerSecond" XXX
 SG_ Left_Lane_02_Long_Distance : 192|12@1+ (0.0625,-3.75) [0|300] "Unit_Meter" XXX
 SG_ Left_Lane_02_Lat_Distance : 204|10@1+ (0.065,-33.28) [-50|50] "Unit_Meter" XXX
 SG_ Left_Lane_02_Rel_Velo : 214|10@1+ (0.25,-128) [-150|150] "Unit_MeterPerSecond" XXX
 SG_ Right_Lane_02_Long_Distance : 224|12@1+ (0.0625,-3.75) [0|300] "Unit_Meter" XXX
 SG_ Right_Lane_02_Lat_Distance : 236|10@1+ (0.065,-33.28) [-50|50] "Unit_Meter" XXX
 SG_ Right_Lane_02_Rel_Velo : 246|10@1+ (0.25,-128) [-150|150] "Unit_MeterPerSecond" XXX
 SG_ Unknown_04 : 256|8@1+ (1,-128) [0|31] "" XXX
 SG_ Unknown_05 : 264|6@1+ (1,-15) [0|31] "" XXX
 SG_ Unknown_06 : 270|6@1+ (1,0) [0|127] "" XXX
 SG_ Unknown_07 : 277|6@1+ (1,0) [0|7] "" XXX
 SG_ Unknown_08 : 284|6@1+ (1,0) [0|1] "" XXX

BO_ 605 KLR_01: 8 Gateway
 SG_ CHECKSUM : 0|8@1+ (1,0) [0|255] "" Vector__XXX
 SG_ COUNTER : 8|4@1+ (1,0) [0|15] "" Vector__XXX
 SG_ KLR_Error : 12|1@1+ (1,0) [0|1] "" Vector__XXX
 SG_ KLR_ResponseError : 13|1@1+ (1,0) [0|1] "" Vector__XXX
 SG_ KLR_LocalActive : 14|1@1+ (1,0) [0|1] "" Vector__XXX
 SG_ KLR_Error_Coding : 15|1@1+ (1,0) [0|1] "" Vector__XXX
 SG_ KLR_TouchIntensity_1 : 16|8@1+ (1,0) [0|250] "Unit_None" Vector__XXX
 SG_ KLR_TouchIntensity_2 : 24|8@1+ (1,0) [0|250] "Unit_None" Vector__XXX
 SG_ KLR_TouchIntensity_3 : 32|8@1+ (1,0) [0|250] "Unit_None" Vector__XXX
 SG_ KLR_Touchauswertung : 40|4@1+ (1,0) [0|15] "" ZR_High

BO_ 695 RCTA_01: 8 XXX
 SG_ RCTA_01_CRC : 0|8@1+ (1,0) [0|255] "" XXX
 SG_ RCTA_01_BZ : 8|4@1+ (1,0) [0|15] "" XXX

BO_ 706 Engine_41: 8 Gateway
 SG_ MO_Display_StSt_Text : 12|4@1+ (1,0) [0|15] "" Vector__XXX
 SG_ MO_Display_StSt_Symbol : 16|3@1+ (1,0) [0|7] "" Vector__XXX
 SG_ MO_ADDR_Status : 19|2@1+ (1,0) [0|3] "" ZR_High
 SG_ MO_AGA_Sound_Texte : 21|2@1+ (1,0) [0|3] "" Vector__XXX
 SG_ MO_Display_FMOff_Text : 23|1@1+ (1,0) [0|1] "" Vector__XXX
 SG_ MO_Error_MSpG : 24|1@1+ (1,0) [0|1] "" Vector__XXX
 SG_ PEA_Texte : 25|3@1+ (1,0) [0|7] "" Vector__XXX
 SG_ TSK_Overruled_vMax_DriverInfo : 28|2@1+ (1,0) [0|3] "" Vector__XXX
 SG_ MO_Avus_EngineProtection : 30|2@1+ (1,0) [0|3] "" Vector__XXX
 SG_ MO_RecuperationStage : 32|3@1+ (1,0) [0|7] "" OTA_FC
 SG_ TSK_Unit_vMax_DriverInfo : 35|1@1+ (1,0) [0|1] "" Vector__XXX
 SG_ TSK_Status_vMax_DriverInfo : 36|2@1+ (1,0) [0|3] "" Vector__XXX
 SG_ MO_Red_DrivePower : 38|3@1+ (1,0) [0|7] "" Vector__XXX
 SG_ MO_Disp_RadiatorFan : 47|3@1+ (1,0) [0|7] "" Vector__XXX
 SG_ MO_In_Idle : 50|1@1+ (1,0) [0|1] "" Vector__XXX
 SG_ WIV_Enable_OilPressure_Engine : 51|1@1+ (1,0) [0|1] "" Vector__XXX
 SG_ MO_OilMeasurement_Duration : 52|4@1+ (15,15) [15|225] "Unit_Secon" Vector__XXX
 SG_ TSK_vMax_DriverInfo : 56|8@1+ (1,15) [16|270] "" Vector__XXX

BO_ 771 HCA_03: 24 XXX
 SG_ RequestStatus : 12|4@1+ (1,0) [0|15] "" XXX
 SG_ Power : 16|8@1+ (0.4,0) [0.0|100.0] "Unit_Percent" XXX
 SG_ Curvature : 24|15@1+ (6.7e-06,0) [0|0.219] "Unit_rad/m" XXX
 SG_ Curvature_VZ : 39|1@1+ (1,0) [0|1] "" XXX
 SG_ Unknown_01 : 53|1@0+ (1,0) [0|1] "" XXX
 SG_ Vibration : 56|1@0+ (1,0) [0|1] "" XXX
 SG_ HighSendRate : 66|1@1+ (1,0) [0|1] "" XXX

BO_ 792 MEB_Camera_03: 8 XXX

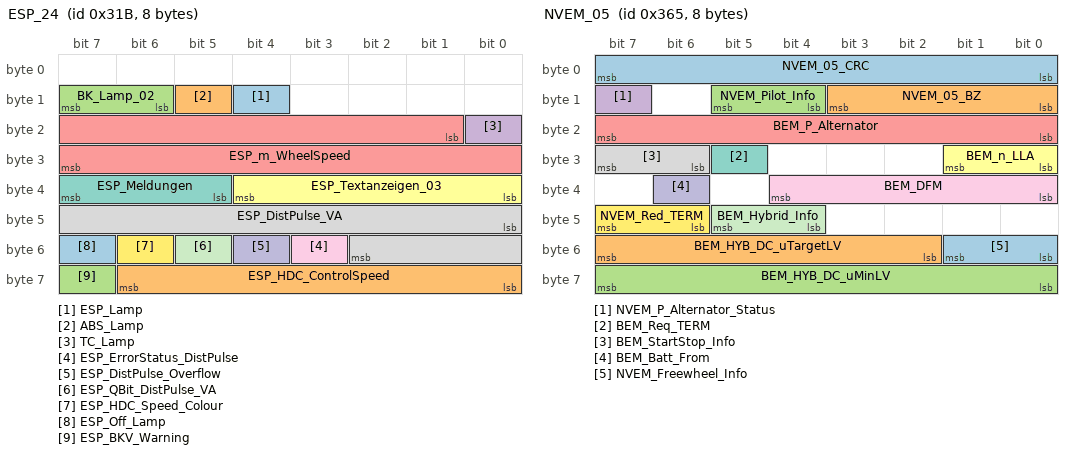
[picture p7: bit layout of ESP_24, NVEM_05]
BO_ 795 ESP_24: 8 Gateway
 SG_ ESP_Lamp : 12|1@1+ (1,0) [0|1] "" Sub_Gateway
 SG_ ABS_Lamp : 13|1@1+ (1,0) [0|1] "" Sub_Gateway
 SG_ BK_Lamp_02 : 14|2@1+ (1,0) [0|3] "" Sub_Gateway
 SG_ TC_Lamp : 16|1@1+ (1,0) [0|1] "" Sub_Gateway
 SG_ ESP_m_WheelSpeed : 17|15@1+ (0.002,0) [0|65.278] "Unit_Hertz" Sub_Gateway
 SG_ ESP_Textanzeigen_03 : 32|5@1+ (1,0) [0|31] "" Sub_Gateway
 SG_ ESP_Meldungen : 37|3@1+ (1,0) [0|7] "" Sub_Gateway
 SG_ ESP_DistPulse_VA : 40|11@1+ (1,0) [0|2047] "" Sub_Gateway
 SG_ ESP_ErrorStatus_DistPulse : 51|1@1+ (1,0) [0|1] "" Sub_Gateway
 SG_ ESP_DistPulse_Overflow : 52|1@1+ (1,0) [0|1] "" Sub_Gateway
 SG_ ESP_QBit_DistPulse_VA : 53|1@1+ (1,0) [0|1] "" Sub_Gateway
 SG_ ESP_HDC_Speed_Colour : 54|1@1+ (1,0) [0|1] "" Sub_Gateway
 SG_ ESP_Off_Lamp : 55|1@1+ (1,0) [0|1] "" Sub_Gateway
 SG_ ESP_HDC_ControlSpeed : 56|7@1+ (0.32,0) [0.32|39.68] "Unit_KiloMeterPerHour" Sub_Gateway
 SG_ ESP_BKV_Warning : 63|1@1+ (1,0) [0|1] "" Sub_Gateway

BO_ 817 MFL_01: 8 Gateway
 SG_ MFL_Counter : 0|4@1+ (1,0) [0|15] "" Vector__XXX
 SG_ MFL_Toggle : 4|1@1+ (1,0) [0|1] "" Vector__XXX
 SG_ MFL_LocalActive : 5|1@1+ (1,0) [0|1] "" Vector__XXX
 SG_ MFL_M_Key : 6|1@1+ (1,0) [0|1] "" ZR_High
 SG_ MFL_Paddle_Fitment : 7|1@1+ (1,0) [0|1] "" ZR_High
 SG_ MFL_KeyCode_1 : 8|8@1+ (1,0) [0|255] "" Vector__XXX
 SG_ MFL_KeyCode_2 : 16|8@1+ (1,0) [0|255] "" Vector__XXX
 SG_ MFL_Eventcode_1 : 24|4@1+ (1,0) [0|15] "" Vector__XXX
 SG_ MFL_Eventcode_2 : 28|4@1+ (1,0) [0|15] "" Vector__XXX
 SG_ MFL_Brand : 32|4@1+ (1,0) [0|15] "" Vector__XXX
 SG_ MFL_Variant : 36|4@1+ (1,0) [0|15] "" Vector__XXX
 SG_ MFL_Dummy_0_Signal_1 : 40|8@1+ (1,0) [0|255] "" Vector__XXX
 SG_ MFL_Tip_Down : 48|1@1+ (1,0) [0|1] "" ZR_High
 SG_ MFL_Tip_Up : 49|1@1+ (1,0) [0|1] "" ZR_High
 SG_ MFL_SatModule_Left_Err : 50|1@1+ (1,0) [0|1] "" ZR_High
 SG_ MFL_SatModule_Right_Err : 51|1@1+ (1,0) [0|1] "" ZR_High
 SG_ MFL_Dummy_0_Signal_2 : 52|1@1+ (1,0) [0|1] "" Vector__XXX
 SG_ MFL_Dummy_0_Signal_3 : 53|1@1+ (1,0) [0|1] "" Vector__XXX
 SG_ MFL_LR_HZG_Status : 54|1@1+ (1,0) [0|1] "" ZR_High
 SG_ MFL_LR_HZG_Err : 55|1@1+ (1,0) [0|1] "" ZR_High
 SG_ MFL_Horn : 56|1@1+ (1,0) [0|1] "" OTA_FC,ZR_High
 SG_ MFL_Horn_Err : 57|1@1+ (1,0) [0|1] "" ZR_High
 SG_ MFL_Tip_Left_Err : 58|1@1+ (1,0) [0|1] "" ZR_High
 SG_ MFL_Tip_Right_Err : 59|1@1+ (1,0) [0|1] "" ZR_High
 SG_ MFL_Key_Left_Err : 60|1@1+ (1,0) [0|1] "" ZR_High
 SG_ MFL_Key_Right_Err : 61|1@1+ (1,0) [0|1] "" ZR_High
 SG_ MFL_ECU_Err : 62|1@1+ (1,0) [0|1] "" ZR_High
 SG_ MFL_Response_Err : 63|1@1+ (1,0) [0|1] "" Vector__XXX

BO_ 850 Parking_SM_03: 8 Gateway
 SG_ Parking_SM_03_MUX M : 0|3@1+ (1,0) [0|7] "" DDA
 SG_ Parking_SM_03_Traj_Trans_ID_00 m0 : 3|4@1+ (1,0) [0|15] "" DDA
 SG_ Parking_Traj_P1_Pos_X m0 : 7|13@1+ (0.5,-2047.5) [-2047.5|2048] "Unit_Centimeter" DDA
 SG_ Parking_Traj_P1_Pos_Y m0 : 20|13@1+ (0.5,-2047.5) [-2047.5|2048] "Unit_Centimeter" DDA
 SG_ Parking_Traj_P1_Tangent m0 : 33|10@1+ (0.3515625,0) [0|359.6484375] "Unit_DegreOfArc" DDA
 SG_ Parking_Traj_P2_Pos_X m0 : 43|13@1+ (0.5,-2047.5) [-2047.5|2048] "Unit_Centimeter" DDA
 SG_ Parking_SM_03_Traj_Trans_ID_01 m1 : 3|4@1+ (1,0) [0|15] "" DDA
 SG_ Parking_Traj_P2_Pos_Y m1 : 7|13@1+ (0.5,-2047.5) [-2047.5|2048] "Unit_Centimeter" DDA
 SG_ Parking_Traj_P2_Tangent m1 : 20|10@1+ (0.3515625,0) [0|359.6484375] "Unit_DegreOfArc" DDA
 SG_ Parking_Traj_P3_Pos_X m1 : 30|13@1+ (0.5,-2047.5) [-2047.5|2048] "Unit_Centimeter" DDA
 SG_ Parking_Traj_P3_Pos_Y m1 : 43|13@1+ (0.5,-2047.5) [-2047.5|2048] "Unit_Centimeter" DDA
 SG_ Parking_SM_03_Traj_Trans_ID_02 m2 : 3|4@1+ (1,0) [0|15] "" DDA
 SG_ Parking_Traj_P3_Tangent m2 : 7|10@1+ (0.3515625,0) [0|359.6484375] "Unit_DegreOfArc" DDA
 SG_ Parking_Traj_P4_Pos_X m2 : 17|13@1+ (0.5,-2047.5) [-2047.5|2048] "Unit_Centimeter" DDA
 SG_ Parking_Traj_P4_Pos_Y m2 : 30|13@1+ (0.5,-2047.5) [-2047.5|2048] "Unit_Centimeter" DDA
 SG_ Parking_Traj_P4_Tangent m2 : 43|10@1+ (0.3515625,0) [0|359.6484375] "Unit_DegreOfArc" DDA
 SG_ Parking_SM_03_Traj_Trans_ID_03 m3 : 3|4@1+ (1,0) [0|15] "" DDA
 SG_ Parking_Traj_P5_Pos_X m3 : 7|13@1+ (0.5,-2047.5) [-2047.5|2048] "Unit_Centimeter" DDA
 SG_ Parking_Traj_P5_Pos_Y m3 : 20|13@1+ (0.5,-2047.5) [-2047.5|2048] "Unit_Centimeter" DDA
 SG_ Parking_Traj_P5_Tangent m3 : 33|10@1+ (0.3515625,0) [0|359.6484375] "Unit_DegreOfArc" DDA
 SG_ Parking_Traj_P6_Pos_X m3 : 43|13@1+ (0.5,-2047.5) [-2047.5|2048] "Unit_Centimeter" DDA
 SG_ Parking_SM_03_Traj_Trans_ID_04 m4 : 3|4@1+ (1,0) [0|15] "" DDA
 SG_ Parking_Traj_P6_Pos_Y m4 : 7|13@1+ (0.5,-2047.5) [-2047.5|2048] "Unit_Centimeter" DDA
 SG_ Parking_Traj_P6_Tangent m4 : 20|10@1+ (0.3515625,0) [0|359.6484375] "Unit_DegreOfArc" DDA
 SG_ Parking_Traj_P7_Pos_X m4 : 30|13@1+ (0.5,-2047.5) [-2047.5|2048] "Unit_Centimeter" DDA
 SG_ Parking_Traj_P7_Pos_Y m4 : 43|13@1+ (0.5,-2047.5) [-2047.5|2048] "Unit_Centimeter" DDA
 SG_ Parking_SM_03_Traj_Trans_ID_05 m5 : 3|4@1+ (1,0) [0|15] "" DDA
 SG_ Parking_Traj_P7_Tangent m5 : 7|10@1+ (0.3515625,0) [0|359.6484375] "Unit_DegreOfArc" DDA
 SG_ Parking_Traj_P8_Pos_X m5 : 17|13@1+ (0.5,-2047.5) [-2047.5|2048] "Unit_Centimeter" DDA
 SG_ Parking_Traj_P8_Pos_Y m5 : 30|13@1+ (0.5,-2047.5) [-2047.5|2048] "Unit_Centimeter" DDA
 SG_ Parking_Traj_P8_Tangent m5 : 43|10@1+ (0.3515625,0) [0|359.6484375] "Unit_DegreOfArc" DDA
 SG_ Parking_SM_03_Traj_Trans_ID_06 m6 : 3|4@1+ (1,0) [0|15] "" DDA
 SG_ Parking_Traj_P9_Pos_X m6 : 7|13@1+ (0.5,-2047.5) [-2047.5|2048] "Unit_Centimeter" DDA
 SG_ Parking_Traj_P9_Pos_Y m6 : 20|13@1+ (0.5,-2047.5) [-2047.5|2048] "Unit_Centimeter" DDA
 SG_ Parking_Traj_P9_Tangent m6 : 33|10@1+ (0.3515625,0) [0|359.6484375] "Unit_DegreOfArc" DDA

BO_ 869 NVEM_05: 8 Gateway
 SG_ NVEM_05_CRC : 0|8@1+ (1,0) [0|255] "" Vector__XXX
 SG_ NVEM_05_BZ : 8|4@1+ (1,0) [0|15] "" Vector__XXX
 SG_ NVEM_Pilot_Info : 12|2@1+ (1,0) [0|3] "" Vector__XXX
 SG_ NVEM_P_Alternator_Status : 15|1@1+ (1,0) [0|1] "" Vector__XXX
 SG_ BEM_P_Alternator : 16|8@1+ (50,0) [0|12700] "Unit_Watt" Vector__XXX
 SG_ BEM_n_LLA : 24|2@1+ (1,0) [0|3] "" Vector__XXX
 SG_ BEM_Req_TERM : 29|1@1+ (1,0) [0|1] "" Vector__XXX
 SG_ BEM_StartStop_Info : 30|2@1+ (1,0) [0|3] "" Vector__XXX
 SG_ BEM_DFM : 32|5@1+ (3.225,0.025) [0.025|100] "" Vector__XXX
 SG_ BEM_Batt_From : 38|1@1+ (1,0) [0|1] "" DCDC_800V_PAG,DCDC_IHEV
 SG_ BEM_Hybrid_Info : 44|2@1+ (1,0) [0|3] "" Vector__XXX
 SG_ NVEM_Red_TERM : 46|2@1+ (1,0) [0|3] "" TME
 SG_ NVEM_Freewheel_Info : 48|2@1+ (1,0) [0|3] "" Vector__XXX
 SG_ BEM_HYB_DC_uTargetLV : 50|6@1+ (0.1,10.6) [10.6|16] "Unit_Volt" DCDC_800V_PAG,DCDC_HV,LE_MLBevo
 SG_ BEM_HYB_DC_uMinLV : 56|8@1+ (0.1,0) [0|25.3] "Unit_Volt" Vector__XXX

BO_ 870 FlashModes_02: 8 Gateway
 SG_ BM_ZV_Open : 12|1@1+ (1,0) [0|1] "" ZR_High
 SG_ BM_ZV_Closed : 13|1@1+ (1,0) [0|1] "" ZR_High
 SG_ BM_DWA_On : 14|1@1+ (1,0) [0|1] "" ZR_High
 SG_ BM_DWA_Alarm : 15|1@1+ (1,0) [0|1] "" ZR_High
 SG_ BM_Crash : 16|1@1+ (1,0) [0|1] "" ZR_High
 SG_ BM_Panic : 17|1@1+ (1,0) [0|1] "" ZR_High
 SG_ BM_Not_Braking : 18|1@1+ (1,0) [0|1] "" ZR_High
 SG_ BM_GDO : 19|1@1+ (1,0) [0|1] "" Vector__XXX
 SG_ BM_HazardFlash : 20|1@1+ (1,0) [0|1] "" ZR_High
 SG_ BM_Taxi_Notalarm : 21|1@1+ (1,0) [0|1] "" ZR_High
 SG_ BM_Telematics : 22|1@1+ (1,0) [0|1] "" ZR_High
 SG_ BM_Left : 23|1@1+ (1,0) [0|1] "" ZR_High
 SG_ BM_Right : 24|1@1+ (1,0) [0|1] "" ZR_High
 SG_ Flash_Left_Veh_Clock : 25|1@1+ (1,0) [0|1] "" ZR_High
 SG_ Flash_Right_Veh_Clock : 26|1@1+ (1,0) [0|1] "" ZR_High
 SG_ Flash_Left_Cluster_Clock : 27|1@1+ (1,0) [0|1] "" ZR_High,ZR_LIMU,ZR_MIB_TOP_ab_Gen3,ZR_Standard
 SG_ Flash_Right_Cluster_Clock : 28|1@1+ (1,0) [0|1] "" ZR_High,ZR_LIMU,ZR_MIB_TOP_ab_Gen3,ZR_Standard
 SG_ BM_NBA_n_Coded_n_Active : 29|1@1+ (1,0) [0|1] "" Vector__XXX
 SG_ BM_NBA_Status : 30|2@1+ (1,0) [0|3] "" Vector__XXX
 SG_ BM_WBT_Lighting : 32|1@1+ (1,0) [0|1] "" ZR_High
 SG_ BM_HD_Opening_angelernt : 33|1@1+ (1,0) [0|1] "" Vector__XXX
 SG_ BM_Motorway : 34|1@1+ (1,0) [0|1] "" ZR_High,ZR_LIMU,ZR_MIB_TOP_ab_Gen3
 SG_ BM_RollerMode_Flash : 35|1@1+ (1,0) [0|1] "" Vector__XXX
 SG_ BM_Recas : 36|1@1+ (1,0) [0|1] "" ZR_High
 SG_ BM_Wischblinken : 37|1@1+ (1,0) [0|1] "" ZR_High
 SG_ BM_Telematics_Abbruchgrund : 38|6@1+ (1,0) [0|63] "" Vector__XXX
 SG_ BM_PiloPa : 44|1@1+ (1,0) [0|1] "" ZR_High
 SG_ DWA_Alarmquelle : 59|5@1+ (1,0) [0|31] "" ZR_High

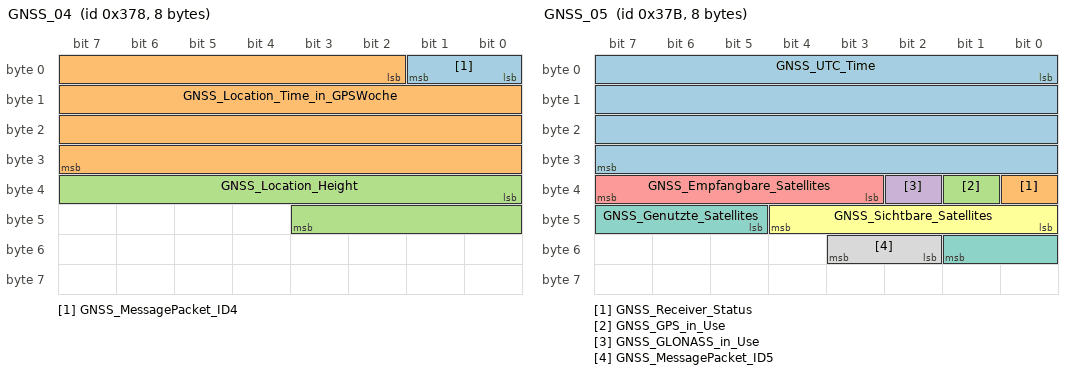
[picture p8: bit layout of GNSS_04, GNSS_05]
BO_ 888 GNSS_04: 8 Gateway
 SG_ GNSS_MessagePacket_ID4 : 0|2@1+ (1,0) [0|3] "Unit_Bit" ZR_High,ZR_LIMU,ZR_MIB_TOP_ab_Gen3,ZR_Standard
 SG_ GNSS_Location_Time_in_GPSWoche : 2|30@1+ (1,0) [0|604800001] "Unit_MilliSecon" ZR_High,ZR_LIMU,ZR_MIB_TOP_ab_Gen3,ZR_Standard
 SG_ GNSS_Location_Height : 32|12@1+ (2,-500) [-500|7686] "Unit_Meter" ZR_High,ZR_LIMU,ZR_MIB_TOP_ab_Gen3,ZR_Standard

BO_ 891 GNSS_05: 8 Gateway
 SG_ GNSS_UTC_Time : 0|32@1+ (1,0) [1|4294967295] "Unit_Secon" OTA_FC,ZR_High,ZR_LIMU,ZR_MIB_TOP_ab_Gen3,ZR_Standard
 SG_ GNSS_Receiver_Status : 32|1@1+ (1,0) [0|1] "" OTA_FC,ZR_High,ZR_LIMU,ZR_MIB_TOP_ab_Gen3,ZR_Standard
 SG_ GNSS_GPS_in_Use : 33|1@1+ (1,0) [0|1] "" ZR_High,ZR_LIMU,ZR_MIB_TOP_ab_Gen3,ZR_Standard
 SG_ GNSS_GLONASS_in_Use : 34|1@1+ (1,0) [0|1] "" ZR_High,ZR_LIMU,ZR_MIB_TOP_ab_Gen3,ZR_Standard
 SG_ GNSS_Empfangbare_Satellites : 35|5@1+ (1,0) [1|30] "Unit_None" ZR_High,ZR_LIMU,ZR_MIB_TOP_ab_Gen3,ZR_Standard
 SG_ GNSS_Sichtbare_Satellites : 40|5@1+ (1,0) [1|30] "Unit_None" ZR_High,ZR_LIMU,ZR_MIB_TOP_ab_Gen3,ZR_Standard
 SG_ GNSS_Genutzte_Satellites : 45|5@1+ (1,0) [1|30] "Unit_None" ZR_High,ZR_LIMU,ZR_MIB_TOP_ab_Gen3,ZR_Standard
 SG_ GNSS_MessagePacket_ID5 : 50|2@1+ (1,0) [0|3] "Unit_Bit" ZR_High,ZR_LIMU,ZR_MIB_TOP_ab_Gen3,ZR_Standard

BO_ 896 APS_Master: 8 XXX
 SG_ Active : 54|1@0+ (1,0) [0|1] "" XXX
 SG_ Distance : 55|9@1+ (1,0) [0|255] "" XXX

BO_ 916 WBA_03: 8 Gateway
 SG_ WBA_03_CRC : 0|8@1+ (1,0) [0|255] "" Sub_Gateway
 SG_ WBA_03_BZ : 8|4@1+ (1,0) [0|15] "" Sub_Gateway
 SG_ WBA_DriveRange_02 : 12|4@1+ (1,0) [0|15] "" Sub_Gateway
 SG_ WBA_TargetDriveRange : 16|4@1+ (1,0) [0|15] "" Sub_Gateway
 SG_ WBA_GE_Warning_02 : 20|4@1+ (1,0) [0|15] "" Sub_Gateway
 SG_ WBA_Input_Gear_02 : 24|4@1+ (1,0) [0|15] "" Sub_Gateway
 SG_ WBA_GE_Texte : 28|3@1+ (1,0) [0|7] "" Sub_Gateway
 SG_ WBA_Coasting_Active : 31|1@1+ (1,0) [0|1] "" Sub_Gateway
 SG_ WBA_ShiftPattern : 32|5@1+ (1,0) [0|31] "" Sub_Gateway
 SG_ WBA_GE_AdditionalWarnings : 37|3@1+ (1,0) [0|7] "" Sub_Gateway
 SG_ GE_TargetGear : 40|4@1+ (1,0) [0|15] "" Sub_Gateway
 SG_ GE_TipShiftRecommend_Available : 44|1@1+ (1,0) [0|1] "" Sub_Gateway
 SG_ WBA_GE_Texte_02 : 45|3@1+ (1,0) [0|7] "" Sub_Gateway
 SG_ WBA_GE_Texte_03 : 48|4@1+ (1,0) [0|15] "" Sub_Gateway
 SG_ WBA_Flash : 54|1@1+ (1,0) [0|1] "" Sub_Gateway
 SG_ GE_Restart_Disp_Std : 55|1@1+ (1,0) [0|1] "" Sub_Gateway
 SG_ GE_StopInhibit_Disp_01 : 56|1@1+ (1,0) [0|1] "" Sub_Gateway
 SG_ GE_StopInhibit_Disp_02 : 57|1@1+ (1,0) [0|1] "" Sub_Gateway
 SG_ GE_StopInhibit_Disp_03 : 58|1@1+ (1,0) [0|1] "" Sub_Gateway
 SG_ GE_StopInhibit_Disp_04 : 59|1@1+ (1,0) [0|1] "" Sub_Gateway
 SG_ GE_StopInhibit_Disp_05 : 60|1@1+ (1,0) [0|1] "" Sub_Gateway
 SG_ GE_StopInhibit_Disp_06 : 61|1@1+ (1,0) [0|1] "" Sub_Gateway
 SG_ GE_StopInhibit_Disp_07 : 62|1@1+ (1,0) [0|1] "" Sub_Gateway
 SG_ GE_StopInhibit_Disp_Std : 63|1@1+ (1,0) [0|1] "" Sub_Gateway

BO_ 919 LDW_02: 8 XXX
 SG_ LDW_Chime : 12|2@1+ (1,0) [0|3] "" XXX
 SG_ LDW_SW_Warning_Left : 14|1@1+ (1,0) [0|1] "" XXX
 SG_ LDW_SW_Warning_Right : 15|1@1+ (1,0) [0|1] "" XXX
 SG_ LDW_Texte : 16|4@1+ (1,0) [0|15] "" XXX
 SG_ LDW_Side_DLCTLC : 20|1@1+ (1,0) [0|1] "" XXX
 SG_ LDW_LearnMode : 21|3@1+ (1,0) [0|7] "" XXX
 SG_ LDW_Anlaufsp_VLR : 24|4@1+ (1,0) [0|15] "" XXX
 SG_ LDW_Vib_Amp_VLR : 28|4@1+ (1,0) [0|15] "" XXX
 SG_ LDW_StartUpTime_VLR : 32|4@1+ (1,0) [0|15] "" XXX
 SG_ LDW_LearnMode_Right : 36|2@1+ (1,0) [0|3] "" XXX
 SG_ LDW_LearnMode_Left : 38|2@1+ (1,0) [0|3] "" XXX
 SG_ LDW_DLC : 40|8@1+ (0.01,-1.25) [-1.25|1.25] "Unit_Meter" XXX
 SG_ LDW_TLC : 48|5@1+ (0.1,0) [0|3] "Unit_Secon" XXX
 SG_ LDW_Warning_Left : 56|1@1+ (1,0) [0|1] "" XXX
 SG_ LDW_Warning_Right : 57|1@1+ (1,0) [0|1] "" XXX
 SG_ LDW_CodingInfo_For_VLR : 58|2@1+ (1,0) [0|3] "" XXX
 SG_ LDW_WindscreenHeating_Active : 60|1@1+ (1,0) [0|1] "" XXX
 SG_ LDW_Status_LED_Yellow : 61|1@1+ (1,0) [0|1] "" XXX
 SG_ LDW_Status_LED_Green : 62|1@1+ (1,0) [0|1] "" XXX
 SG_ LDW_KD_Error : 63|1@1+ (1,0) [0|1] "" XXX

BO_ 949 Climate_11: 8 Gateway
 SG_ TERM_Rpm_Trailer : 0|1@1+ (1,0) [0|1] "" TME
 SG_ TERM_PreWarn_Compressor_On : 1|1@1+ (1,0) [0|1] "" TME
 SG_ TERM_AC_Switch : 2|1@1+ (1,0) [0|1] "" TME
 SG_ TERM_Compressor_Torque_Old : 3|1@1+ (1,0) [0|1] "" TME
 SG_ TERM_PreWarn_AuxHeater_On : 6|1@1+ (1,0) [0|1] "" Vector__XXX
 SG_ TERM_State : 7|1@1+ (1,0) [0|1] "" TME
 SG_ TERM_CompressorClutch_linear : 8|8@1+ (20,0) [0|4000] "Unit_MilliAmper" Vector__XXX
 SG_ TERM_Charisma_DrivePr : 16|4@1+ (1,0) [0|15] "" TME
 SG_ TERM_Charisma_Status : 20|2@1+ (1,0) [0|3] "" TME
 SG_ TERM_Retrofit_Stop_Req : 22|1@1+ (1,0) [0|1] "" Vector__XXX
 SG_ TERM_T_Charge : 23|1@1+ (1,0) [0|1] "" Vector__XXX
 SG_ TERM_Load_Compressor : 24|8@1+ (0.25,0) [0|63.5] "Unit_NewtoMeter" TME
 SG_ TERM_Voltage_Req : 32|2@1+ (1,0) [0|3] "" Vector__XXX
 SG_ TERM_ThermalManagement : 34|2@1+ (1,0) [0|3] "" TME
 SG_ TERM_StartStop_Info : 36|2@1+ (1,0) [0|3] "" TME
 SG_ TERM_Freewheel_Info : 38|2@1+ (1,0) [0|3] "" Vector__XXX
 SG_ TERM_Req_TERM : 40|8@1+ (0.4,0) [0|101.6] "Unit_PerCent" TME
 SG_ TERM_el_AuxHeater_Stage : 48|3@1+ (1,0) [0|7] "" TME
 SG_ TERM_Ausstattung_Climate : 51|3@1+ (1,0) [0|7] "" Vector__XXX
 SG_ TERM_Variant_AuxHeater : 54|2@1+ (1,0) [0|3] "" Vector__XXX

BO_ 958 Engine_14: 8 Gateway
 SG_ CHECKSUM : 0|8@1+ (1,0) [0|255] "" XXX
 SG_ COUNTER : 8|4@1+ (1,0) [0|15] "" XXX
 SG_ MO_StartStop_Status : 12|2@1+ (1,0) [0|3] "" Sub_Gateway,TME
 SG_ MO_StartStop_Restart : 14|1@1+ (1,0) [0|1] "" BMS_NV,Sub_Gateway,TME
 SG_ MO_StartStop_EngineStop : 15|1@1+ (1,0) [0|1] "" BMS_NV,Sub_Gateway,TME
 SG_ MO_Enable_Recup : 16|2@1+ (1,0) [0|3] "" Sub_Gateway
 SG_ MO_Term_75 : 18|1@1+ (1,0) [0|1] "" Sub_Gateway,TME
 SG_ MO_Term_50 : 19|1@1+ (1,0) [0|1] "" DCDC_IHEV,Ladegeraet_Konzern,Sub_Gateway
 SG_ MO_GearPosition : 20|4@1+ (1,0) [0|15] "" AWC,Sub_Gateway,TME
 SG_ MO_StartStop_DriverDemand : 24|2@1+ (1,0) [0|3] "" Sub_Gateway,TME
 SG_ MO_HYB_ReadyToDrive : 26|1@1+ (1,0) [0|1] "" AWC,BMS_NV,Ladegeraet_Konzern,Sub_Gateway,TME
 SG_ MO_Ext_E_Journey_Active : 27|1@1+ (1,0) [0|1] "" Sub_Gateway,TME
 SG_ MO_Driver_Brakes : 28|1@1+ (1,0) [0|1] "" Sub_Gateway
 SG_ MO_QBit_Driver_Brakes : 29|1@1+ (1,0) [0|1] "" Sub_Gateway
 SG_ MO_BLS : 30|1@1+ (1,0) [0|1] "" Sub_Gateway
 SG_ MO_Consistency_BrakePedal : 31|1@1+ (1,0) [0|1] "" Sub_Gateway
 SG_ MO_CommError_ESP : 32|1@1+ (1,0) [0|1] "" Sub_Gateway
 SG_ MO_Climate_Interv : 33|2@1+ (1,0) [0|3] "" Sub_Gateway,TME
 SG_ MO_Aussp_Crank : 35|1@1+ (1,0) [0|1] "" Sub_Gateway
 SG_ MO_Enable_Crank : 36|1@1+ (1,0) [0|1] "" Sub_Gateway
 SG_ MO_Clutch_Switch : 37|1@1+ (1,0) [0|1] "" Sub_Gateway
 SG_ MO_Interlock : 38|1@1+ (1,0) [0|1] "" Sub_Gateway
 SG_ MO_Engine_Running : 39|1@1+ (1,0) [0|1] "" Sub_Gateway,TME
 SG_ MO_Kickdown : 40|1@1+ (1,0) [0|1] "" Sub_Gateway,TME
 SG_ MO_QBit_TERM_75 : 41|1@1+ (1,0) [0|1] "" Sub_Gateway
 SG_ MO_ETermCommLeiRed : 42|2@1+ (1,0) [0|3] "" Sub_Gateway
 SG_ MO_Handshake_STH : 44|1@1+ (1,0) [0|1] "" Sub_Gateway
 SG_ MO_BKV_VacuumWarning : 45|1@1+ (1,0) [0|1] "" Sub_Gateway
 SG_ MO_Enable_Coasting : 46|1@1+ (1,0) [0|1] "" Sub_Gateway
 SG_ MO_PTC_Status : 47|3@1+ (1,0) [0|7] "" Sub_Gateway
 SG_ MO_QBit_GearPosition : 50|1@1+ (1,0) [0|1] "" Sub_Gateway
 SG_ MO_SignalSource_GearPosition : 51|1@1+ (1,0) [0|1] "" Sub_Gateway
 SG_ MO_Remotestart_Operation : 52|1@1+ (1,0) [0|1] "" Sub_Gateway
 SG_ MO_Remotestart_Possible : 53|1@1+ (1,0) [0|1] "" Sub_Gateway
 SG_ MO_FMOff_Active : 55|1@1+ (1,0) [0|1] "" BMS_NV,Sub_Gateway
 SG_ MO_FMOff_Startvariante : 56|2@1+ (1,0) [0|3] "" Sub_Gateway
 SG_ MO_BMS_NV_Req_stuetzen : 58|1@1+ (1,0) [0|1] "" Sub_Gateway
 SG_ MO_CylinderDeactivation : 59|2@1+ (1,0) [0|3] "" Sub_Gateway
 SG_ MO_HYB_VM_Active : 61|1@1+ (1,0) [0|1] "" Sub_Gateway
 SG_ MO_StartVorauss_Met : 62|2@1+ (1,0) [0|3] "" AWC,Ladegeraet_Konzern,Sub_Gateway

BO_ 960 Terminals_Status_01: 4 Gateway
 SG_ Terminals_Status_01_CRC : 0|8@1+ (1,0) [0|255] "" ZR_High,ZR_LIMU,ZR_MIB_TOP_ab_Gen3,ZR_Standard
 SG_ Terminals_Status_01_BZ : 8|4@1+ (1,0) [0|15] "" ZR_High,ZR_LIMU,ZR_MIB_TOP_ab_Gen3,ZR_Standard
 SG_ RSt_DriverNotices : 12|4@1+ (1,0) [0|15] "" ZR_High,ZR_LIMU,ZR_MIB_TOP_ab_Gen3,ZR_Standard
 SG_ ZAS_Term_S : 16|1@1+ (1,0) [0|1] "" BedienDisp_vo,BedienSG_hi,GurtMikrofon,OTA_FC,ZR_High,ZR_LIMU,ZR_MIB_TOP_ab_Gen3,ZR_Standard
 SG_ ZAS_Term_15 : 17|1@1+ (1,0) [0|1] "" BedienDisp_vo,BedienSG_hi,DDA,GurtMikrofon,OTA_FC,ZR_High,ZR_LIMU,ZR_MIB_TOP_ab_Gen3,ZR_Standard
 SG_ ZAS_Term_X : 18|1@1+ (1,0) [0|1] "" ZR_High,ZR_LIMU,ZR_MIB_TOP_ab_Gen3,ZR_Standard
 SG_ ZAS_Term_50_StartRequest : 19|1@1+ (1,0) [0|1] "" BedienDisp_vo,BedienSG_hi,OTA_FC,ZR_High,ZR_LIMU,ZR_MIB_TOP_ab_Gen3,ZR_Standard
 SG_ BCM_Remotestart_Operation : 20|1@1+ (1,0) [0|1] "" BedienSG_hi,ZR_High,ZR_LIMU,ZR_MIB_TOP_ab_Gen3,ZR_Standard
 SG_ ZAS_Term_Infotainment : 21|1@1+ (1,0) [0|1] "" BedienDisp_vo,BedienSG_hi,ZR_High,ZR_LIMU,ZR_MIB_TOP_ab_Gen3,ZR_Standard
 SG_ BCM_Remotestart_TERM15_Req : 22|1@1+ (1,0) [0|1] "" ZR_High,ZR_LIMU,ZR_MIB_TOP_ab_Gen3,ZR_Standard
 SG_ BCM_Remotestart_MO_Start : 23|1@1+ (1,0) [0|1] "" ZR_High,ZR_LIMU,ZR_MIB_TOP_ab_Gen3,ZR_Standard
 SG_ KST_Warn_P1_ZST_def : 24|1@1+ (1,0) [0|1] "" ZR_High,ZR_LIMU,ZR_MIB_TOP_ab_Gen3,ZR_Standard
 SG_ KST_Warn_P2_ZST_def : 25|1@1+ (1,0) [0|1] "" ZR_High,ZR_LIMU,ZR_MIB_TOP_ab_Gen3,ZR_Standard
 SG_ KST_DriverNotice_1 : 26|1@1+ (1,0) [0|1] "" ZR_High,ZR_LIMU,ZR_MIB_TOP_ab_Gen3,ZR_Standard
 SG_ KST_DriverNotice_2 : 27|1@1+ (1,0) [0|1] "" ZR_High,ZR_LIMU,ZR_MIB_TOP_ab_Gen3,ZR_Standard
 SG_ BCM_OffParking_Operation : 28|1@1+ (1,0) [0|1] "" ZR_High,ZR_LIMU,ZR_MIB_TOP_ab_Gen3,ZR_Standard
 SG_ KST_DriverNotice_4 : 29|1@1+ (1,0) [0|1] "" ZR_High,ZR_LIMU,ZR_MIB_TOP_ab_Gen3,ZR_Standard
 SG_ KST_DriverNotice_5 : 30|1@1+ (1,0) [0|1] "" ZR_High,ZR_LIMU,ZR_MIB_TOP_ab_Gen3,ZR_Standard
 SG_ KST_DriverNotice_6 : 31|1@1+ (1,0) [0|1] "" ZR_High,ZR_LIMU,ZR_MIB_TOP_ab_Gen3,ZR_Standard

BO_ 967 Engine_26: 8 Gateway
 SG_ MO_RadiatorFan_MUX M : 0|1@1+ (1,0) [0|1] "" TME
 SG_ MO_RadiatorFan_1 m0 : 1|7@1+ (1,0) [0|100] "Unit_PerCent" TME
 SG_ MO_RadiatorFan_2 m1 : 1|7@1+ (1,0) [0|100] "Unit_PerCent" TME
 SG_ MO_EFLEX_Lamp : 8|2@1+ (1,0) [0|3] "" Vector__XXX
 SG_ MO_KJS_Not_Ready : 10|1@1+ (1,0) [0|1] "" Vector__XXX
 SG_ MO_ITM_Warning_Pump : 11|1@1+ (1,0) [0|1] "" Vector__XXX
 SG_ WIV_Display_Active : 12|1@1+ (1,0) [0|1] "" Vector__XXX
 SG_ WIV_Oelmin_Warn : 13|1@1+ (1,0) [0|1] "" Vector__XXX
 SG_ WIV_SensorError : 14|1@1+ (1,0) [0|1] "" Vector__XXX
 SG_ WIV_Tilt : 15|1@1+ (1,0) [0|1] "" Vector__XXX
 SG_ WIV_OilLevel : 16|4@1+ (12.5,0) [0|100] "Unit_PerCent" Vector__XXX
 SG_ MO_State_HWP : 20|2@1+ (1,0) [0|3] "" TME
 SG_ OLEV_SystemMalfunction : 22|1@1+ (1,0) [0|1] "" Vector__XXX
 SG_ MO_OilWarning_max : 23|1@1+ (1,0) [0|1] "" Vector__XXX
 SG_ WIV_OilSystem_Active : 24|1@1+ (1,0) [0|1] "" Vector__XXX
 SG_ WIV_Not_AtOperatingTemp : 25|1@1+ (1,0) [0|1] "" Vector__XXX
 SG_ WIV_Overfill_Warn : 26|1@1+ (1,0) [0|1] "" Vector__XXX
 SG_ WIV_Running_Engine : 27|1@1+ (1,0) [0|1] "" Vector__XXX
 SG_ MO_E_Warnings : 28|4@1+ (1,0) [0|15] "" Vector__XXX
 SG_ MO_Text_EngineStart : 32|4@1+ (1,0) [0|15] "" Vector__XXX
 SG_ MO_E_Texte : 36|4@1+ (1,0) [0|15] "" Vector__XXX
 SG_ WIV_OilDyn_avl : 40|1@1+ (1,0) [0|1] "" Vector__XXX
 SG_ MO_Text_ParticleFilter_Reg : 41|1@1+ (1,0) [0|1] "" Vector__XXX
 SG_ OLEV_OilLevel_Not_Present : 42|1@1+ (1,0) [0|1] "" Vector__XXX
 SG_ WIV_OilQuantity : 43|5@1+ (125,0) [0|3875] "Unit_MilliLiter" Vector__XXX
 SG_ MO_SystemLamp : 48|1@1+ (1,0) [0|1] "" Vector__XXX
 SG_ MO_OBD2_Lamp : 49|1@1+ (1,0) [0|1] "" Vector__XXX
 SG_ MO_HotWarningLamp : 50|1@1+ (1,0) [0|1] "" TME
 SG_ MO_Particle_Lamp : 51|1@1+ (1,0) [0|1] "" Vector__XXX
 SG_ MO_RedDrivePower_Lamp : 52|1@1+ (1,0) [0|1] "" Vector__XXX
 SG_ WIV_OilLevel_Not_Present : 53|1@1+ (1,0) [0|1] "" Vector__XXX
 SG_ WIV_RefillDisplay_On : 54|1@1+ (1,0) [0|1] "" Vector__XXX
 SG_ WIV_Overfill_Deactivated : 55|1@1+ (1,0) [0|1] "" Vector__XXX
 SG_ WIV_Underfill_Warn : 56|1@1+ (1,0) [0|1] "" Vector__XXX
 SG_ MO_FuelCap_Lamp : 57|1@1+ (1,0) [0|1] "" Vector__XXX
 SG_ MO_Text_FuelCapWarn : 58|1@1+ (1,0) [0|1] "" Vector__XXX
 SG_ MO_Preheat_Lamp : 59|1@1+ (1,0) [0|1] "" Vector__XXX
 SG_ WIV_OilPressure_Warn_Engine : 60|1@1+ (1,0) [0|1] "" Vector__XXX
 SG_ MO_E_Mode : 61|3@1+ (1,0) [0|7] "" Vector__XXX

BO_ 974 DoorECU_HFS_01: 8 Gateway
 SG_ HFS_Door_Opened : 0|1@1+ (1,0) [0|1] "" Vector__XXX
 SG_ HFS_Locked : 1|1@1+ (1,0) [0|1] "" Vector__XXX
 SG_ HFS_Safed : 2|1@1+ (1,0) [0|1] "" Vector__XXX
 SG_ HFS_RearBlindButton_Pressed : 3|1@1+ (1,0) [0|1] "" Vector__XXX
 SG_ HFS_DoorLock_Defective : 4|1@1+ (1,0) [0|1] "" Vector__XXX
 SG_ HFS_Unlock_PushButton : 5|1@1+ (1,0) [0|1] "" Vector__XXX
 SG_ HFS_Lock_PushButton : 6|1@1+ (1,0) [0|1] "" Vector__XXX
 SG_ HFS_ParkPawl : 7|1@1+ (1,0) [0|1] "" Vector__XXX
 SG_ HFS_TAG_Pressed : 8|1@1+ (1,0) [0|1] "" Vector__XXX
 SG_ HFS_TIG_Pressed : 9|1@1+ (1,0) [0|1] "" Vector__XXX
 SG_ HFS_FH_S_HBFS_AutoHigh : 10|1@1+ (1,0) [0|1] "" Vector__XXX
 SG_ HFS_FH_S_HBFS_AutoLow : 11|1@1+ (1,0) [0|1] "" Vector__XXX
 SG_ HFS_FH_S_HBFS_ManHigh : 12|1@1+ (1,0) [0|1] "" Vector__XXX
 SG_ HFS_FH_S_HBFS_ManLow : 13|1@1+ (1,0) [0|1] "" Vector__XXX
 SG_ HFS_Door_Status : 14|2@1+ (1,0) [0|3] "" Vector__XXX
 SG_ HFS_SAD_Switch : 16|4@1+ (1,0) [0|15] "" Vector__XXX
 SG_ HFS_FH_S_ManHigh : 20|1@1+ (1,0) [0|1] "" Vector__XXX
 SG_ HFS_FH_S_AutoHigh : 21|1@1+ (1,0) [0|1] "" Vector__XXX
 SG_ HFS_FH_S_ManLow : 22|1@1+ (1,0) [0|1] "" Vector__XXX
 SG_ HFS_FH_S_AutoLow : 23|1@1+ (1,0) [0|1] "" Vector__XXX
 SG_ HFS_FH_Opening : 24|8@1+ (0.5,0) [0|100] "Unit_PerCent" Vector__XXX
 SG_ HFS_FH_Bew_High : 32|1@1+ (1,0) [0|1] "" Vector__XXX
 SG_ HFS_FH_Bew_Low : 33|1@1+ (1,0) [0|1] "" Vector__XXX
 SG_ HFS_FH_Fang : 34|1@1+ (1,0) [0|1] "" Vector__XXX
 SG_ HFS_FH_Block : 35|1@1+ (1,0) [0|1] "" Vector__XXX
 SG_ HFS_FH_Thermo : 36|1@1+ (1,0) [0|1] "" Vector__XXX
 SG_ HFS_UEKB_Activated : 37|1@1+ (1,0) [0|1] "" Vector__XXX
 SG_ HFS_DoorOpen_Warning : 38|1@1+ (1,0) [0|1] "" Vector__XXX
 SG_ HFS_FH_Normalised : 39|1@1+ (1,0) [0|1] "" Vector__XXX
 SG_ ASW_Warning_Active_HFS : 40|1@1+ (1,0) [0|1] "" Vector__XXX
 SG_ HFS_SoftClose_Active : 41|1@1+ (1,0) [0|1] "" Vector__XXX
 SG_ HFS_SideBlind_High : 42|1@1+ (1,0) [0|1] "" TME
 SG_ HFS_SideBlind_Low : 43|1@1+ (1,0) [0|1] "" TME
 SG_ HFS_Status_ChildSeat : 44|1@1+ (1,0) [0|1] "" Vector__XXX
 SG_ SSR_HFS_Pos_Bottom : 45|1@1+ (1,0) [0|1] "" Vector__XXX
 SG_ HFS_Top_Block_Ext : 46|1@1+ (1,0) [0|1] "" Vector__XXX
 SG_ HFS_Bottom_Block_Ext : 47|1@1+ (1,0) [0|1] "" Vector__XXX
 SG_ MTHFS_M_Key : 48|1@1+ (1,0) [0|1] "" Vector__XXX
 SG_ MTHFS_Pos1 : 49|1@1+ (1,0) [0|1] "" Vector__XXX
 SG_ MTHFS_Pos2 : 50|1@1+ (1,0) [0|1] "" Vector__XXX
 SG_ MTHFS_Pos3 : 51|1@1+ (1,0) [0|1] "" Vector__XXX
 SG_ HFS_MBlind_Switch : 52|3@1+ (1,0) [0|7] "" Vector__XXX
 SG_ HFS_Lock_PushButton_inv : 55|1@1+ (1,0) [0|1] "" Vector__XXX
 SG_ HFS_Status_eTAG : 56|2@1+ (1,0) [0|3] "" Vector__XXX
 SG_ HFS_Door_Status_QBit : 58|1@1+ (1,0) [0|1] "" Vector__XXX
 SG_ HFS_TCR_Mode_Active : 59|1@1+ (1,0) [0|1] "" Vector__XXX

BO_ 975 DoorECU_HBFS_01: 8 Gateway
 SG_ HBFS_Door_Opened : 0|1@1+ (1,0) [0|1] "" Vector__XXX
 SG_ HBFS_Locked : 1|1@1+ (1,0) [0|1] "" Vector__XXX
 SG_ HBFS_Safed : 2|1@1+ (1,0) [0|1] "" Vector__XXX
 SG_ HBFS_RearBlindButton_Pressed : 3|1@1+ (1,0) [0|1] "" Vector__XXX
 SG_ HBFS_DoorLock_Defective : 4|1@1+ (1,0) [0|1] "" Vector__XXX
 SG_ HBFS_Unlock_PushButton : 5|1@1+ (1,0) [0|1] "" Vector__XXX
 SG_ HBFS_Lock_PushButton : 6|1@1+ (1,0) [0|1] "" Vector__XXX
 SG_ HBFS_ParkPawl : 7|1@1+ (1,0) [0|1] "" Vector__XXX
 SG_ HBFS_TAG_Pressed : 8|1@1+ (1,0) [0|1] "" Vector__XXX
 SG_ HBFS_TIG_Pressed : 9|1@1+ (1,0) [0|1] "" Vector__XXX
 SG_ HBFS_FH_S_HFS_AutoHigh : 10|1@1+ (1,0) [0|1] "" Vector__XXX
 SG_ HBFS_FH_S_HFS_AutoLow : 11|1@1+ (1,0) [0|1] "" Vector__XXX
 SG_ HBFS_FH_S_HFS_ManHigh : 12|1@1+ (1,0) [0|1] "" Vector__XXX
 SG_ HBFS_FH_S_HFS_ManLow : 13|1@1+ (1,0) [0|1] "" Vector__XXX
 SG_ HBFS_Door_Status : 14|2@1+ (1,0) [0|3] "" Vector__XXX
 SG_ HBFS_SAD_Switch : 16|4@1+ (1,0) [0|15] "" Vector__XXX
 SG_ HBFS_FH_S_ManHigh : 20|1@1+ (1,0) [0|1] "" Vector__XXX
 SG_ HBFS_FH_S_AutoHigh : 21|1@1+ (1,0) [0|1] "" Vector__XXX
 SG_ HBFS_FH_S_ManLow : 22|1@1+ (1,0) [0|1] "" Vector__XXX
 SG_ HBFS_FH_S_AutoLow : 23|1@1+ (1,0) [0|1] "" Vector__XXX
 SG_ HBFS_FH_Opening : 24|8@1+ (0.5,0) [0|100] "Unit_PerCent" Vector__XXX
 SG_ HBFS_FH_Bew_High : 32|1@1+ (1,0) [0|1] "" Vector__XXX
 SG_ HBFS_FH_Bew_Low : 33|1@1+ (1,0) [0|1] "" Vector__XXX
 SG_ HBFS_FH_Fang : 34|1@1+ (1,0) [0|1] "" Vector__XXX
 SG_ HBFS_FH_Block : 35|1@1+ (1,0) [0|1] "" Vector__XXX
 SG_ HBFS_FH_Thermo : 36|1@1+ (1,0) [0|1] "" Vector__XXX
 SG_ HBFS_UEKB_Activated : 37|1@1+ (1,0) [0|1] "" Vector__XXX
 SG_ HBFS_DoorOpen_Warning : 38|1@1+ (1,0) [0|1] "" Vector__XXX
 SG_ HBFS_FH_Normalised : 39|1@1+ (1,0) [0|1] "" Vector__XXX
 SG_ ASW_Warning_Active_HBFS : 40|1@1+ (1,0) [0|1] "" Vector__XXX
 SG_ HBFS_SoftClose_Active : 41|1@1+ (1,0) [0|1] "" Vector__XXX
 SG_ HBFS_SideBlind_High : 42|1@1+ (1,0) [0|1] "" TME
 SG_ HBFS_SideBlind_Low : 43|1@1+ (1,0) [0|1] "" TME
 SG_ HBFS_Status_ChildSeat : 44|1@1+ (1,0) [0|1] "" Vector__XXX
 SG_ SSR_HBFS_Pos_Bottom : 45|1@1+ (1,0) [0|1] "" Vector__XXX
 SG_ HBFS_Top_Block_Ext : 46|1@1+ (1,0) [0|1] "" Vector__XXX
 SG_ HBFS_Bottom_Block_Ext : 47|1@1+ (1,0) [0|1] "" Vector__XXX
 SG_ MTHBFS_M_Key : 48|1@1+ (1,0) [0|1] "" Vector__XXX
 SG_ MTHBFS_Pos1 : 49|1@1+ (1,0) [0|1] "" Vector__XXX
 SG_ MTHBFS_Pos2 : 50|1@1+ (1,0) [0|1] "" Vector__XXX
 SG_ MTHBFS_Pos3 : 51|1@1+ (1,0) [0|1] "" Vector__XXX
 SG_ HBFS_MBlind_Switch : 52|3@1+ (1,0) [0|7] "" Vector__XXX
 SG_ HBFS_Lock_PushButton_inv : 55|1@1+ (1,0) [0|1] "" Vector__XXX
 SG_ HBFS_Status_ChildSeat_inv : 56|1@1+ (1,0) [0|1] "" Vector__XXX
 SG_ HBFS_Status_eTAG : 57|2@1+ (1,0) [0|3] "" Vector__XXX
 SG_ HBFS_Door_Status_QBit : 59|1@1+ (1,0) [0|1] "" Vector__XXX
 SG_ HBFS_TIG_Pressed_Close : 60|1@1+ (1,0) [0|1] "" Vector__XXX

BO_ 976 DoorECU_FT_01: 8 Gateway
 SG_ FT_Door_Opened : 0|1@1+ (1,0) [0|1] "" Ladegeraet_Konzern,TME
 SG_ FT_Locked : 1|1@1+ (1,0) [0|1] "" Vector__XXX
 SG_ FT_Safed : 2|1@1+ (1,0) [0|1] "" Vector__XXX
 SG_ FT_KeySwitch_Open : 3|1@1+ (1,0) [0|1] "" FCU_MLBevo_FCEV
 SG_ FT_KeySwitch_Closed : 4|1@1+ (1,0) [0|1] "" FCU_MLBevo_FCEV
 SG_ FT_Unlock_PushButton : 5|1@1+ (1,0) [0|1] "" Vector__XXX
 SG_ FT_Lock_PushButton : 6|1@1+ (1,0) [0|1] "" Vector__XXX
 SG_ FT_ParkPawl : 7|1@1+ (1,0) [0|1] "" Vector__XXX
 SG_ FT_TAG_Pressed : 8|1@1+ (1,0) [0|1] "" Vector__XXX
 SG_ FT_TIG_Pressed : 9|1@1+ (1,0) [0|1] "" Vector__XXX
 SG_ FT_IRUE_Key : 10|1@1+ (1,0) [0|1] "" Vector__XXX
 SG_ FT_HD_Key : 11|1@1+ (1,0) [0|1] "" Vector__XXX
 SG_ FT_TD_Key_Error : 12|1@1+ (1,0) [0|1] "" Ladegeraet_Konzern
 SG_ FT_TD_Key : 13|1@1+ (1,0) [0|1] "" FCU_MLBevo_FCEV,Ladegeraet_Konzern
 SG_ SSR_Temp_Enable : 14|1@1+ (1,0) [0|1] "" Vector__XXX
 SG_ FT_Sp_Heating_Req : 15|1@1+ (100,0) [0|100] "Unit_PerCent" Vector__XXX
 SG_ FT_HD_Key_2 : 16|1@1+ (1,0) [0|1] "" Vector__XXX
 SG_ FT_DoorECU_Rear_Fitted : 18|1@1+ (1,0) [0|1] "" Vector__XXX
 SG_ FT_Sp_Blk_def : 19|1@1+ (1,0) [0|1] "" Vector__XXX
 SG_ FT_FH_S_ManHigh : 20|1@1+ (1,0) [0|1] "" Vector__XXX
 SG_ FT_FH_S_AutoHigh : 21|1@1+ (1,0) [0|1] "" Vector__XXX
 SG_ FT_FH_S_ManLow : 22|1@1+ (1,0) [0|1] "" Vector__XXX
 SG_ FT_FH_S_AutoLow : 23|1@1+ (1,0) [0|1] "" Vector__XXX
 SG_ FT_FH_Opening : 24|8@1+ (0.5,0) [0|100] "Unit_PerCent" TME
 SG_ FT_FH_Bew_High : 32|1@1+ (1,0) [0|1] "" Vector__XXX
 SG_ FT_FH_Bew_Low : 33|1@1+ (1,0) [0|1] "" Vector__XXX
 SG_ FT_FH_Fang : 34|1@1+ (1,0) [0|1] "" Vector__XXX
 SG_ FT_FH_Block : 35|1@1+ (1,0) [0|1] "" Vector__XXX
 SG_ FT_FH_Thermo : 36|1@1+ (1,0) [0|1] "" Vector__XXX
 SG_ FT_UEKB_Activated : 37|1@1+ (1,0) [0|1] "" Vector__XXX
 SG_ ASW_HMI_Defective : 38|1@1+ (1,0) [0|1] "" Vector__XXX
 SG_ FT_FH_Normalised : 39|1@1+ (1,0) [0|1] "" Vector__XXX
 SG_ FT_CloseButton : 40|1@1+ (1,0) [0|1] "" Vector__XXX
 SG_ FT_SoftClose_Active : 41|1@1+ (1,0) [0|1] "" Vector__XXX
 SG_ FT_SP_Disengaged : 42|1@1+ (1,0) [0|1] "" Vector__XXX
 SG_ FT_SP_lr_Active : 43|1@1+ (1,0) [0|1] "" Vector__XXX
 SG_ FT_SP_ht_Active : 44|1@1+ (1,0) [0|1] "" Vector__XXX
 SG_ ASW_wakeup : 45|1@1+ (1,0) [0|1] "" Vector__XXX
 SG_ FT_Top_Block_Ext : 46|1@1+ (1,0) [0|1] "" Vector__XXX
 SG_ FT_Bottom_Block_Ext : 47|1@1+ (1,0) [0|1] "" Vector__XXX
 SG_ FT_ChildSeat_Left_Active : 48|1@1+ (1,0) [0|1] "" Vector__XXX
 SG_ FT_ChildSeat_Right_Active : 49|1@1+ (1,0) [0|1] "" Vector__XXX
 SG_ FT_ChildSeat_PushButton_Left : 50|1@1+ (1,0) [0|1] "" Vector__XXX
 SG_ FT_ChildSeat_PushButton_Right : 51|1@1+ (1,0) [0|1] "" Vector__XXX
 SG_ FT_BFS_Fond_Enable : 52|1@1+ (1,0) [0|1] "" Vector__XXX
 SG_ FT_ChildSeat_Error : 53|1@1+ (1,0) [0|1] "" Vector__XXX
 SG_ FT_Daemmglas : 54|1@1+ (1,0) [0|1] "" Vector__XXX
 SG_ FT_SP_Heating_Status : 55|1@1+ (1,0) [0|1] "" Vector__XXX
 SG_ ASW_Warning_Active_FS : 56|1@1+ (1,0) [0|1] "" Vector__XXX
 SG_ FT_FH_Pos_Top : 57|1@1+ (1,0) [0|1] "" Vector__XXX
 SG_ FT_DoorLock_Defective : 58|1@1+ (1,0) [0|1] "" Vector__XXX
 SG_ FT_SWA_PushButton : 59|1@1+ (1,0) [0|1] "" Vector__XXX
 SG_ SWA_HMI_Diagnostics : 60|2@1+ (1,0) [0|3] "" Vector__XXX
 SG_ FS_Status_eTAG : 62|2@1+ (1,0) [0|3] "" Vector__XXX

BO_ 980 SMLS_01: 8 Gateway
 SG_ SMLS_01_CRC : 0|8@1+ (1,0) [0|255] "" Vector__XXX
 SG_ SMLS_01_BZ : 8|4@1+ (1,0) [0|15] "" Vector__XXX
 SG_ BH_Indicator_Left : 12|1@1+ (1,0) [0|1] "" ZR_High,ZR_Standard
 SG_ BH_Indicator_Right : 13|1@1+ (1,0) [0|1] "" ZR_High,ZR_Standard
 SG_ BH_HeadlightFlash : 14|1@1+ (1,0) [0|1] "" ZR_High
 SG_ BH_HighBeam : 15|1@1+ (1,0) [0|1] "" ZR_High
 SG_ WH_TipWipe : 16|1@1+ (1,0) [0|1] "" ZR_High
 SG_ WH_Intervall : 17|1@1+ (1,0) [0|1] "" ZR_High
 SG_ WH_WiperStage1 : 18|1@1+ (1,0) [0|1] "" ZR_High
 SG_ WH_WiperStage2 : 19|1@1+ (1,0) [0|1] "" ZR_High
 SG_ WH_FrontWash : 20|1@1+ (1,0) [0|1] "" ZR_High
 SG_ WH_Heckintervall : 21|1@1+ (1,0) [0|1] "" ZR_High
 SG_ WH_RearWash : 22|1@1+ (1,0) [0|1] "" ZR_High
 SG_ WH_Intervallstufen : 23|4@1+ (1,0) [0|15] "" ZR_High
 SG_ FAS_PushButton : 27|1@1+ (1,0) [0|1] "" ZR_High,ZR_Standard
 SG_ FAS_PushButton_Error : 28|1@1+ (1,0) [0|1] "" ZR_High
 SG_ SMLS_Horn : 29|1@1+ (1,0) [0|1] "" Vector__XXX
 SG_ LRH_On_Off : 30|2@1+ (1,0) [0|3] "" ZR_High
 SG_ LRH_Active : 40|1@1+ (1,0) [0|1] "" ZR_High
 SG_ SMLS_P_Locked_Plausible : 43|1@1+ (1,0) [0|1] "" Vector__XXX
 SG_ WH_SRA : 44|1@1+ (1,0) [0|1] "" OTA_FC,ZR_High
 SG_ WH_Wiper_Error : 45|1@1+ (1,0) [0|1] "" ZR_High
 SG_ BH_Indicator_Error : 46|1@1+ (1,0) [0|1] "" ZR_High
 SG_ SMLS_PTT : 47|1@1+ (1,0) [0|1] "" ZR_High,ZR_LIMU,ZR_MIB_TOP_ab_Gen3,ZR_Standard
 SG_ WH_TipWipe_Long : 48|1@1+ (1,0) [0|1] "" ZR_High

BO_ 981 Light_Req_01: 8 Gateway
 SG_ Light_Req_01_CRC : 0|8@1+ (1,0) [0|255] "" Vector__XXX
 SG_ Light_Req_01_BZ : 8|4@1+ (1,0) [0|15] "" Vector__XXX
 SG_ BCM1_CorneringLight_Left_Req : 12|1@1+ (1,0) [0|1] "" ZR_High
 SG_ BCM1_CorneringLight_Right_Req : 13|1@1+ (1,0) [0|1] "" ZR_High
 SG_ BCM1_SideLight_Req : 14|1@1+ (1,0) [0|1] "" ZR_High
 SG_ BCM1_LowBeam_Req : 15|1@1+ (1,0) [0|1] "" OTA_FC,ZR_High
 SG_ BCM1_HighBeam_Req : 16|1@1+ (1,0) [0|1] "" ZR_High
 SG_ BCM1_FogLight_Req : 17|1@1+ (1,0) [0|1] "" ZR_High
 SG_ BCM1_ParkingLight_Left_Req : 18|1@1+ (1,0) [0|1] "" ZR_High
 SG_ BCM1_ParkingLight_Right_Req : 19|1@1+ (1,0) [0|1] "" ZR_High
 SG_ BCM1_RearFog_Ahg_Req : 20|1@1+ (1,0) [0|1] "" ZR_High
 SG_ BCM1_RearFog_Veh_Req : 21|1@1+ (1,0) [0|1] "" ZR_High
 SG_ BCM1_TailLight_Req : 22|1@1+ (1,0) [0|1] "" ZR_High
 SG_ BCM_ReversingLight_Req : 23|1@1+ (1,0) [0|1] "" ZR_High,ZR_MIB_TOP_ab_Gen3,ZR_Standard
 SG_ BCM1_SignatureLight_Req : 24|1@1+ (1,0) [0|1] "" Vector__XXX
 SG_ BCM1_Umfeldleuchten_Req : 25|1@1+ (1,0) [0|1] "" ZR_High
 SG_ BCM1_DaytimeRunningLight_Req : 26|1@1+ (1,0) [0|1] "" ZR_High
 SG_ BCM1_RainLight_Req : 27|1@1+ (1,0) [0|1] "" ZR_High
 SG_ BCM1_MotorwayLight_Req : 28|1@1+ (1,0) [0|1] "" ZR_High
 SG_ BCM1_Tourist_Light_Req : 29|1@1+ (1,0) [0|1] "" ZR_High
 SG_ BCM1_CH_Active : 30|1@1+ (1,0) [0|1] "" ZR_High
 SG_ BCM1_LH_Active : 31|1@1+ (1,0) [0|1] "" ZR_High
 SG_ BCM1_Sliding_Leuchtw_Req : 32|1@1+ (1,0) [0|1] "" ZR_High
 SG_ BCM1_GLW_HighBeam_Req : 33|1@1+ (1,0) [0|1] "" ZR_High
 SG_ BCM1_Adaptive_LightDistribution_Req : 34|1@1+ (1,0) [0|1] "" ZR_High
 SG_ BCM1_FoD_Blocking_WiBli : 35|2@1+ (1,0) [0|3] "" Vector__XXX
 SG_ BCM1_FOD_Blocking_Animations_HL : 37|2@1+ (1,0) [0|3] "" Vector__XXX
 SG_ BCM1_Animationssperrung : 39|1@1+ (1,0) [0|1] "" Vector__XXX
 SG_ BCM1_CH_LH_Active : 40|1@1+ (1,0) [0|1] "" ZR_High
 SG_ BCM1_AllWeatherLight_Req : 41|1@1+ (1,0) [0|1] "" ZR_High
 SG_ BCM1_TailLight_Signature : 60|4@1+ (1,0) [0|15] "" Vector__XXX

BO_ 982 Light_Rear_01: 8 Gateway
 SG_ BCM2_BrakeLight_By_ECD : 5|1@1+ (1,0) [0|1] "" OTA_FC,ZR_High
 SG_ LH_OutsideLight_def : 7|1@1+ (1,0) [0|1] "" ZR_High
 SG_ LH_SideLight_H_Active : 8|1@1+ (1,0) [0|1] "" OTA_FC,ZR_High
 SG_ LH_ParkingLight_HL_Active : 9|1@1+ (1,0) [0|1] "" OTA_FC,ZR_High
 SG_ LH_ParkingLight_HR_Active : 10|1@1+ (1,0) [0|1] "" OTA_FC,ZR_High
 SG_ LH_BrakeLight_H_Active : 11|1@1+ (1,0) [0|1] "" OTA_FC,ZR_High
 SG_ LH_RearFog_Active : 12|1@1+ (1,0) [0|1] "" OTA_FC,ZR_High
 SG_ LH_ReversingLight_Active : 13|1@1+ (1,0) [0|1] "" OTA_FC,ZR_High
 SG_ LH_Indicator_HL_Act : 14|1@1+ (1,0) [0|1] "" OTA_FC,ZR_High
 SG_ LH_Indicator_HR_Act : 15|1@1+ (1,0) [0|1] "" OTA_FC,ZR_High
 SG_ LH_Indicator_Left_def : 16|1@1+ (1,0) [0|1] "" ZR_High
 SG_ LH_BrakeLight_Left_def : 17|1@1+ (1,0) [0|1] "" ZR_High
 SG_ LH_TailLight_Left_def : 18|1@1+ (1,0) [0|1] "" ZR_High
 SG_ LH_Reverse_Left_def : 19|1@1+ (1,0) [0|1] "" ZR_High
 SG_ LH_Fog_Left_def : 20|1@1+ (1,0) [0|1] "" ZR_High
 SG_ LH_End_Brake_Fog_Left_def : 21|1@1+ (1,0) [0|1] "" ZR_High
 SG_ LH_End_Brake_Fog_Right_def : 22|1@1+ (1,0) [0|1] "" ZR_High
 SG_ LH_Zusatzschlussl_def : 23|1@1+ (1,0) [0|1] "" Vector__XXX
 SG_ LH_End_Brake_Left_def : 24|1@1+ (1,0) [0|1] "" ZR_High
 SG_ LH_End_Fog_Left_def : 25|1@1+ (1,0) [0|1] "" ZR_High
 SG_ LH_SL_BRL_BLK_Left_def : 26|1@1+ (1,0) [0|1] "" ZR_High
 SG_ LH_Brake_Blk_Left_def : 27|1@1+ (1,0) [0|1] "" Vector__XXX
 SG_ LH_Diag_Status_Right_def : 28|1@1+ (1,0) [0|1] "" ZR_High
 SG_ LH_Diag_Status_Left_def : 29|1@1+ (1,0) [0|1] "" ZR_High
 SG_ LH_Diag_LED_Left_def : 30|1@1+ (1,0) [0|1] "" ZR_High
 SG_ LH_Diag_LED_Right_def : 31|1@1+ (1,0) [0|1] "" ZR_High
 SG_ LH_Indicator_Right_def : 32|1@1+ (1,0) [0|1] "" ZR_High
 SG_ LH_BrakeLight_Right_def : 33|1@1+ (1,0) [0|1] "" ZR_High
 SG_ LH_TailLight_Right_def : 34|1@1+ (1,0) [0|1] "" ZR_High
 SG_ LH_Reverse_Right_def : 35|1@1+ (1,0) [0|1] "" ZR_High
 SG_ LH_Fog_Right_def : 36|1@1+ (1,0) [0|1] "" ZR_High
 SG_ LH_End_Brake_mi_def : 37|1@1+ (1,0) [0|1] "" Vector__XXX
 SG_ LH_End_Brake_Right_def : 40|1@1+ (1,0) [0|1] "" ZR_High
 SG_ LH_End_Fog_Right_def : 41|1@1+ (1,0) [0|1] "" ZR_High
 SG_ LH_SL_BRL_BLK_Right_def : 42|1@1+ (1,0) [0|1] "" ZR_High
 SG_ LH_Brake_Blk_Right_def : 43|1@1+ (1,0) [0|1] "" ZR_High
 SG_ LH_Kennzl_def : 48|1@1+ (1,0) [0|1] "" ZR_High
 SG_ LH_3_BrakeLight_def : 49|1@1+ (1,0) [0|1] "" ZR_High
 SG_ LH_Fog_mi_def : 50|1@1+ (1,0) [0|1] "" ZR_High
 SG_ LH_Reverse_mi_def : 51|1@1+ (1,0) [0|1] "" ZR_High
 SG_ LH_TailLight_mi_def : 52|1@1+ (1,0) [0|1] "" Vector__XXX
 SG_ LH_BrakeLight_mi_def : 53|1@1+ (1,0) [0|1] "" Vector__XXX
 SG_ LH_BrakeLight_Left_Total_def : 54|1@1+ (1,0) [0|1] "" ZR_High
 SG_ LH_BrakeLight_Right_Total_def : 55|1@1+ (1,0) [0|1] "" ZR_High

CM_ BO_ 184 "Motorsteuergerät";
CM_ BO_ 192 "Motorsteuergerät";
CM_ BO_ 219 "AEB_Object_Status and AEB_Object_Status_B values 4 and 5/6 coincide with AEB potentially activating";
CM_ SG_ 219 AEB_Target_Decel "Scale is estimated. Lowest request seen was -6.99";
CM_ SG_ 219 AEB_TTC_Countdown "Can count down to zero before AEB activates, but may not always precede an AEB or mean it will happen";
CM_ SG_ 219 VRU_Detected "Commonly high when a pedestrian is seen. Also goes high with AWV_Unavailable";
CM_ SG_ 219 AWV_Unavailable "High when the AWV function cannot operate, seen with the radar obstructed and with the powertrain ECU off the bus. MEB_AWV_01.AWV_Status carries the same state";
CM_ SG_ 219 AWV_Init_Status "Power-up state only, reads 2 once running. Does not report whether AEB can operate, use AWV_Unavailable for that";
CM_ SG_ 219 Unknown_192 "Constant per platform (0 on all gen1 ID.4/Born, 1 on all gen2 ID.4)";
CM_ SG_ 219 Unknown_27 "Low bit tracks AWV_Unavailable, but is also set in 20-33% of normal driving";
CM_ SG_ 219 Unknown_80 "Low bit is normally 1 and clears with AWV_Unavailable, but also clears in ~1% of normal driving";
CM_ SG_ 313 Long_Control_Inhibit "Goes high after user brakes hard, causes temporary TSK_Status fault";
CM_ SG_ 333 SET_ME_0x2FE "Only set by stock ACC on 2024+; reads 0 on pre-2024 and is not packed by mebcan";
CM_ BO_ 317 "Lenkungssteuergerät";
CM_ BO_ 517 "Steuergerät für Motorstart";
CM_ BO_ 522 "Steuergerät für Fahrzeugbewegung";
VAL_ 64 FROM_RGS_Anst 4 "Active_Level_1" 5 "Active_Level_2" 6 "Active_Level_3" 7 "Active_Level_4" 8 "Deactivated";
VAL_ 64 FROM_Front_Crash 0 "No_Front_Crash" 1 "Front_Crash";
VAL_ 64 FROM_Rear_Crash 0 "No_Rear_Crash" 1 "Rear_Crash";
VAL_ 64 FROM_SF_Crash 0 "No_Side_Crash_Driver" 1 "Side_Crash_Driver";
VAL_ 64 FROM_SB_Crash 0 "No_Side_Crash_Passenger" 1 "Side_Crash_Passenger";
VAL_ 64 FROM_Rollover_Crash 0 "No_Rollover" 1 "Rollover";
VAL_ 64 FROM_Crash_Int 0 "No_Crash" 1 "Crash_Intensity_1" 2 "Crash_Intensity_2_(Only_ActuatorTest_MLB_B8)" 3 "Crash_Intensity_2_(Only_D4_C7_Colorado_NF_PAG__Crash_In_MLB_B8)" 4 "Crash_Intensity_3_(Old_VW/AUDI__ActuatorTest_MLB_B8)" 5 "Crash_Intensity_3_(Old_PAG)" 7 "Crash_Intensity_3";
VAL_ 64 FROM_Lamp 0 "Off" 1 "On";
VAL_ 64 FROM_Deactivated 0 "Active" 1 "Deactivated";
VAL_ 64 FROM_VB_Deactivated 0 "PassengerAirbag_Active" 1 "PassengerAirbag_Deactivated";
VAL_ 64 FROM_SystemError 0 "No_Error" 1 "Airbag_SystemError";
VAL_ 64 FROM_Diagnostics 0 "Not_in_Diagnostics" 1 "in_Diagnostics";
VAL_ 64 FROM_ActuatorTest 0 "Not_In_ActuatorTest" 1 "Airbag_In_ActuatorTest";
VAL_ 64 FROM_Erh_Open_VB 0 "No_Display" 1 "PassengerAirbag_Deactivated" 2 "PassengerAirbag_Activated" 3 "Not_Defined";
VAL_ 64 FROM_BeltWarn_VF 0 "No_Warning" 1 "BeltWarning_Trigger";
VAL_ 64 FROM_BeltWarn_VB 0 "No_Warning" 1 "BeltWarning_Trigger";
VAL_ 64 FROM_Display_Pedestrian 0 "No_FSG_Aktion_Triggered" 1 "Bonnet_Open" 2 "SystemError";
VAL_ 64 FROM_Texte_AKS 0 "No_AKS_Ausloesung" 1 "AKS_Triggered" 2 "AKS_SystemError";
VAL_ 64 FROM_MKB_Valid 0 "MultiCollisionBraking_Not_Unlocked" 1 "MultiCollisionBraking_Unlocked";
VAL_ 64 FROM_MKB_Request 0 "MultiCollisionBraking_Not_Requested" 1 "MultiCollisionBraking_Requested";
VAL_ 64 FROM_SupplyVoltage 0 "Plausible" 1 "Implausible";
VAL_ 64 FROM_Deactivation_HV 0 "No_Deactivation" 1 "Deactivation_1" 2 "Deactivation_2" 3 "Deactivation_3" 4 "Deactivation_4" 5 "Deactivation_5" 6 "Deactivation_6" 7 "Error";
VAL_ 64 FROM_EDR_Trigger 0 "No_Event" 1 "Start_Event" 2 "NonDeployment_Event" 3 "Deployment_Event";
VAL_ 64 FROM_Occupancy_VF 0 "Not_Available" 1 "Error" 2 "Not_Occupied" 3 "Occupied";
VAL_ 64 SC_LowSpeedCrashDetected 0 "No_Crash_Detected" 1 "Crash_FrontRange_Detected" 2 "Crash_RearRange_Detected" 3 "Crash_Front_And_RearRange_Detected";
VAL_ 64 SC_MasterTime 127 "Init";
VAL_ 134 LWI_Sensorstatus 0 "iO" 1 "Not Calibrated";
VAL_ 134 LWI_QBit_Sub_Data 0 "LWS-Subinfo real (SteeringWheelAngleInformation ADS-Suitable)" 1 "LWS-Subinfo simuliert (SteeringWheelAngleInformation Not ADS-Suitable )";
VAL_ 134 LWI_MFL_Shutdown 0 "Inactive" 1 "Active";
VAL_ 134 LWI_QBit_SteeringWheelAngle 0 "Valid Value" 1 "Outside The Spezifikation";
VAL_ 134 LWI_SteeringWheelAngle 8190 "Init" 8191 "Error";
VAL_ 134 LWI_VZ_SteeringWheelAngle 0 "Positive_Left_From_The_ZeroPosition" 1 "Negative";
VAL_ 134 LWI_VZ_SteeringWheelAngle_Speed 0 "Positive_Left_From_The_ZeroPosition" 1 "Negative";
VAL_ 134 LWI_SteeringWheelAngle_Speed 510 "Init" 511 "Error";
VAL_ 159 EPS_HCA_Status 0 "disabled" 1 "initializing" 2 "fault" 3 "ready" 4 "rejected" 5 "active" 8 "preempted";
VAL_ 167 MO_Torque_Target_Raw 1022 "Init";
VAL_ 167 MO_Torque_Actual_Sum 1022 "Init";
VAL_ 167 MO_Torque_Inertia_Sum 1022 "Init";
VAL_ 167 MO_Torque_Target_Filtered 1022 "Init";
VAL_ 167 MO_Torque_Overrun 510 "Init";
VAL_ 167 MO_Status_NormalOperation_01 0 "No_NormalOperation" 1 "NormalOperation_Reached";
VAL_ 167 MO_First_InaccurateThreshold 0 "Accurate" 1 "Torques ungenauer >8%";
VAL_ 167 MO_QBit_EngineTorques 0 "Valid_Value" 1 "Substitute_Init_Or_ErrorValue";
VAL_ 168 MO_Torque_Neg_Available 510 "Init" 511 "Error";
VAL_ 168 MO_Torque_Limit_Status 510 "Init";
VAL_ 168 MO_Torque_Limit_Dyn 1022 "Init";
VAL_ 168 MO_QBit_Rpm_01 0 "Valid_Value" 1 "Substitute_Init_Or_ErrorValue";
VAL_ 173 GE_MTorque_Target_02 1022 "No_Request_Init" 1023 "Error";
VAL_ 173 GE_MTorque_Lead_02 1022 "Init" 1023 "Error";
VAL_ 173 GE_Uefkt 1023 "Error";
VAL_ 173 GE_DriveRange 0 "BetweenPosition" 1 "Init" 5 "P" 6 "R" 7 "N" 8 "D" 9 "D" 10 "E" 13 "T" 14 "T" 15 "Error";
VAL_ 173 GE_ShiftSequence 0 "No_Shift" 1 "Momentenueberschneidung" 2 "Befuellphase" 3 "Drehzahlueberfuehrung";
VAL_ 173 GE_Uefkt_Implausible 0 "Uefkt_Plausible" 1 "Uefkt_Implausible";
VAL_ 173 GE_MTorque_Status_02 0 "No_Intervention" 1 "abs_Reducing_Intervention_Open_Total_Drive_Only_Faster_Path" 2 "abs_erhoehender_Intervention_Open_Total_Drive" 3 "relativer_Intervention_Open_Total_Drive" 4 "relativer_Intervention_Open_E_Maschine" 5 "abs_red_Interv_Open_Total_Drive_Only_AirPath" 6 "abs_red_Interv_Open_Total_Drive_Air-_And_schnellen_Path" 7 "abs_Intervention_Open_TotalDrive_erhoehend_And_reduzierend";
VAL_ 173 GE_Status_Traction 0 "Open_No_Traction" 1 "Open_With_Traction" 2 "schlupfend_geregelt" 3 "abgesichert_Open_No_Kraftschl" 4 "Closed_With_Mikroschlupf" 5 "Closed_With_Ueberanpressung" 6 "Other_Error" 7 "Faulty_Closed";
VAL_ 173 GE_MTorque_Status 0 "No Request" 1 "Reducing GearboxIntervention" 2 "erhhender GearboxIntervention" 3 "Įderung With Sprung";
VAL_ 173 GE_Enable_MTorque_Lead 0 "Not_Enabled" 1 "Enabled";
VAL_ 173 GE_Inhibit_Suppression 0 "No_Inhibit" 1 "Inhibit";
VAL_ 173 GE_TargetGear 0 "Gear P/N (Disengaged)" 1 "Gear 1" 2 "Gear 2" 3 "Gear 3" 4 "Gear 4" 5 "Gear 5" 6 "Gear 6" 7 "Gear 7" 8 "Gear R" 11 "Gear 8" 12 "Gear 9" 13 "Gear10" 14 "ActualGear Not Defined" 15 "Error";
VAL_ 184 EM1_Enable_Info_WFS 0 "Invalid" 1 "Valid";
VAL_ 184 EM1_Lock_Info_WFS 0 "Not_Locked" 1 "Locked";
VAL_ 184 EM1_AR_Active 0 "Init" 1 "Ruckeldaempfer_Active";
VAL_ 184 EM1_Eta_Sys 510 "Init" 511 "Error";
VAL_ 184 EM1_ActualCurrent 2046 "Init" 2047 "Error";
VAL_ 184 EM1_Error_ElDriveFreewheel_Req 0 "Init" 1 "Error_EM_In_Freewheel";
VAL_ 184 EM1_Limiting_Temperature 0 "Init" 1 "Limiting_Temperature";
VAL_ 184 EM1_AnlernenElEngine_Req 0 "No_Diagnostics_Request" 1 "Diagnostics_Request";
VAL_ 184 EM1_Torque_HVConsumer 1023 "Init";
VAL_ 184 EM1_Enable_ExpiryInfo_WFS 0 "Off" 1 "On";
VAL_ 184 EM1_Parking_WFS_Status 0 "Limitation_Inactive" 1 "Limitation_Active" 2 "Abort";
VAL_ 184 EM1_HV_Operational 0 "Init" 1 "Ready_HV";
VAL_ 253 BR_InterventionTorque 1022 "Init" 1023 "Error";
VAL_ 253 ESP_Diagnostics 0 "ESP_Not_in_Diagnostics" 1 "ESP_in_Diagnostics";
VAL_ 253 ESC_v_Signal_Qualifier_High_Low 0 "QualityThreshold_Smaller_1kmh" 1 "QualityThreshold_Smaller_3kmh" 2 "QualityThreshold_Smaller_5kmh" 3 "QualityThreshold_Smaller_10kmh" 4 "QualityThreshold_Smaller_20kmh" 5 "QualityThreshold_GreaterEqual_20kmh" 6 "Init" 7 "Error";
VAL_ 253 ESP_BeforeControl 0 "No_BeforeControl_Active" 1 "BeforeControl_Active";
VAL_ 253 OBD_RoughRoad 0 "No_RoughRoad_Detected" 1 "RoughRoad_Detected";
VAL_ 253 OBD_QBit_RoughRoad 0 "Valid_Value" 1 "Substitute_Init_Or_ErrorValue";
VAL_ 253 ESP_v_Signal 65533 "Undervoltage" 65534 "Init" 65535 "Error";
VAL_ 253 ASR_Keying_Passive 0 "ASR_Activated" 1 "ASR_Passive_Keyed_Or_Thresholds_Changed";
VAL_ 253 ESP_Keying_Passive 0 "ESP_Activated" 1 "ESP_Passive_Keyed_Or_Thresholds_Changed";
VAL_ 253 ESP_SystemStatus 0 "iO" 1 "Error";
VAL_ 253 ASR_ShiftIntervention 0 "No_Request" 1 "ASR_ShiftMap" 2 "Rueckschaltung" 3 "ShiftInhibit";
VAL_ 253 ESP_QBit_v_Signal 0 "Valid_Value" 1 "Substitute_Init_Or_ErrorValue";
VAL_ 253 ABS_Braking 0 "No_ABS_Control" 1 "ABS_Control_Active";
VAL_ 253 ASR_Req 0 "No_Request" 1 "ASR_Request";
VAL_ 253 MSR_Req 0 "No Request" 1 "MSR-Request";
VAL_ 253 EBV_Intervention 0 "No_EBV_Intervention" 1 "EBV_Intervention";
VAL_ 253 EDS_Intervention 0 "No_EDS_Intervention" 1 "EDS_Intervention";
VAL_ 253 ESP_Intervention 0 "No_ESP_Intervention" 1 "ESP_Intervention_Active";
VAL_ 253 ESP_ASP 0 "Inactive" 1 "Active";
VAL_ 253 ESC_NeutralShift 0 "No_Request" 1 "NeutralShift_Requested";
VAL_ 278 ESP_QBit_DistancePulse_VL 0 "Valid_Value" 1 "Substitute_Init_Or_ErrorValue";
VAL_ 278 ESP_QBit_DistancePulse_VR 0 "Valid_Value" 1 "Substitute_Init_Or_ErrorValue";
VAL_ 278 ESP_QBit_DistancePulse_HL 0 "Valid_Value" 1 "Substitute_Init_Or_ErrorValue";
VAL_ 278 ESP_QBit_DistancePulse_HR 0 "Valid_Value" 1 "Substitute_Init_Or_ErrorValue";
VAL_ 278 ESP_DistancePulse_VL 1021 "Init" 1022 "Undervoltage" 1023 "Error";
VAL_ 278 ESP_DistancePulse_VR 1021 "Init" 1022 "Undervoltage" 1023 "Error";
VAL_ 278 ESP_DistancePulse_HL 1021 "Init" 1022 "Undervoltage" 1023 "Error";
VAL_ 278 ESP_DistancePulse_HR 1021 "Init" 1022 "Undervoltage" 1023 "Error";
VAL_ 278 ESP_VL_Direction 0 "Forward" 1 "Reverse" 2 "Init" 3 "Invalid_Or_Not_Fitted";
VAL_ 278 ESP_VR_Direction 0 "Forward" 1 "Reverse" 2 "Init" 3 "Invalid_Or_Not_Fitted";
VAL_ 278 ESP_HL_Direction 0 "Forward" 1 "Reverse" 2 "Init" 3 "Invalid_Or_Not_Fitted";
VAL_ 278 ESP_HR_Direction 0 "Forward" 1 "Reverse" 2 "Init" 3 "Invalid_Or_Not_Fitted";
VAL_ 299 GRA_MainSwitch 0 "MainSwitch_Off__PushButton_Not_Pressed" 1 "MainSwitch_On__PushButton_Pressed";
VAL_ 299 GRA_Cancel 0 "Not_Pressed" 1 "Pressed";
VAL_ 299 GRA_Type_MainSwitch 0 "gerasteter_StalkSwitch" 1 "getasteter_StalkSwitch";
VAL_ 299 GRA_Limiter 0 "Not_Pressed" 1 "Pressed";
VAL_ 299 GRA_Tip_Set 0 "Not_Pressed" 1 "Pressed";
VAL_ 299 GRA_Tip_High 0 "Not_Pressed" 1 "Pressed";
VAL_ 299 GRA_Tip_Down 0 "Not_Pressed" 1 "Pressed";
VAL_ 299 GRA_Tip_Resume 0 "Not_Pressed" 1 "Pressed";
VAL_ 299 GRA_Adjustment_TimeGap 0 "Key_Not_Pressed" 1 "Dist_minus_1" 2 "Dist_plus_1" 3 "Dist_Toggle";
VAL_ 299 GRA_Coding 0 "No_Lever" 1 "GRA_Lever" 2 "ACC_Lever" 3 "Limiter_Only";
VAL_ 299 GRA_Error 0 "No_Error" 1 "Error";
VAL_ 299 GRA_LIM_Key_Available 0 "Limiter_Key_Not_Present" 1 "Limiter_Key_Present";
VAL_ 299 GRA_Tip_Stage_2 0 "Tip_Stage_1__No_Actuation" 1 "Tip_Stage_2";
VAL_ 299 GRA_TravelAssist 0 "Not_Pressed" 1 "Pressed";
VAL_ 313 Long_Control_Inhibit 1 "not_inhibited" 2 "inhibited";
VAL_ 317 LatCon_HCA_Status 0 "disabled" 1 "initializing" 2 "ready" 3 "fault" 4 "active" 5 "preempted" 6 "fault" 7 "rejected";
VAL_ 319 PreCrash_Charisma_DrivePr 0 "No_Function" 1 "Programm_1" 2 "Programm_2" 3 "Programm_3" 4 "Programm_4" 5 "Programm_5" 6 "Programm_6" 7 "Programm_7" 8 "Programm_8" 9 "Programm_9" 10 "Programm_10" 11 "Programm_11" 12 "Programm_12" 13 "Programm_13" 14 "Programm_14" 15 "Programm_15";
VAL_ 319 PreCrash_Charisma_Status 0 "Init" 1 "Available" 2 "Not_Available" 3 "Asynchronous_By_DriverDemand";
VAL_ 319 PreCrash_Sunroof_Close 0 "No_Closing" 1 "Closing_Requested";
VAL_ 319 PreCrash_Window_Close 0 "No_Closing" 1 "Closing_Requested";
VAL_ 319 PreCrash_Flash 0 "No_FlashRequest" 1 "HazardFlash" 2 "RECAS_Flash" 3 "Notbremsblinken";
VAL_ 319 SC_PreSense_FCWP 0 "Warning_gilt_For_Objekte" 1 "Warning_gitl_For_Pedestrian";
VAL_ 319 PreCrash_Doors_Lock 0 "No_Request" 1 "Doors_Lock";
VAL_ 319 PreCrash_Request_AFR 0 "No_Request" 1 "Left_Side" 2 "Right_Side" 3 "FrontAxle" 4 "Hinterachse" 5 "PreWarning" 7 "Init";
VAL_ 319 SC_PreCrash_LED 0 "No_Display" 1 "Stage_1_glimmen" 2 "Stage_2_leuchten" 3 "Stage_3_Flash";
VAL_ 319 PreCrash_FS_Pneumatic_Actuate 0 "No_Request" 1 "Pneumatic_Actuate";
VAL_ 319 PreCrash_BFS_Pneumatic_Actuate 0 "No_Request" 1 "Pneumatic_Actuate";
VAL_ 319 PreCrash_Fo_Pneumatic_Actuate 0 "No_Request" 1 "Pneumatic_Actuate";
VAL_ 319 PreCrash_FS_Backrest_Procedure 0 "No_Request" 1 "Backrest_in_pos_x-Direction_Procedure(Before)" 2 "Backrest_in_Neg_x-Direction_Procedure(Back)" 3 "BackrestHead_in_pos_x-Direction_Procedure(Before)" 4 "BackrestHead_in_Neg_x-Direction_Procedure(Back)" 6 "Lehnenverstellung_Actuate" 7 "Lehnenkopfverstellung_Actuate";
VAL_ 319 PreCrash_BFS_Backrest_Procedure 0 "No_Request" 1 "Backrest_in_pos_x-Direction_Procedure(Before)" 2 "Backrest_in_Neg_x-Direction_Procedure(Back)" 3 "BackrestHead_in_pos_x-Direction_Procedure(Before)" 4 "BackrestHead_in_Neg_x-Direction_Procedure(Back)" 6 "Lehnenverstellung_Actuate" 7 "Lehnenkopfverstellung_Actuate";
VAL_ 319 PreCrash_Fo_Backrest_Procedure 0 "No_Request" 1 "Backrest_in_pos_x-Direction_Procedure(Before)" 2 "Backrest_in_Neg_x-Direction_Procedure(Back)" 3 "BackrestHead_in_pos_x-Direction_Procedure(Before)" 4 "BackrestHead_in_Neg_x-Direction_Procedure(Back)";
VAL_ 319 PreCrash_FS_KSV_Procedure 0 "No_Request" 1 "in_pos_x-Direction_Procedure" 2 "in_Neg_x-Direction_Procedure" 3 "in_pos_z-Direction_Procedure" 4 "in_Neg_z-Direction_Procedure" 5 "in_pos_x-Direction_And_Neg_z-Direction_Procedure" 6 "in_pos_x_Direction_And_pos_z-Direction_Procedure" 7 "in_Neg_x-Direction_And_Neg_z-Direction_Procedure" 8 "in_Neg_x-Direction_And_pos_z-Direction_Procedure" 9 "Kopfstuetze_Actuate";
VAL_ 319 PreCrash_BFS_KSV_Procedure 0 "No_Request" 1 "in_pos_x-Direction_Procedure" 2 "in_Neg_x-Direction_Procedure" 3 "in_pos_z-Direction_Procedure" 4 "in_Neg_z-Direction_Procedure" 5 "in_pos_x-Direction_And_Neg_z-Direction_Procedure" 6 "in_pos_x_Direction_And_pos_z-Direction_Procedure" 7 "in_Neg_x-Direction_And_Neg_z-Direction_Procedure" 8 "in_Neg_x-Direction_And_pos_z-Direction_Procedure" 9 "Kopfstuetze_Actuate";
VAL_ 319 PreCrash_Fo_KSV_Procedure 0 "No_Request" 1 "in_pos_x-Direction_Procedure" 2 "in_Neg_x-Direction_Procedure" 3 "in_pos_z-Direction_Procedure" 4 "in_Neg_z-Direction_Procedure" 5 "in_pos_x-Direction_And_Neg_z-Direction_Procedure" 6 "in_pos_x_Direction_And_pos_z-Direction_Procedure" 7 "in_Neg_x-Direction_And_Neg_z-Direction_Procedure" 8 "in_Neg_x-Direction_And_pos_z-Direction_Procedure";
VAL_ 319 SC_PreCrash_Warning 0 "No_Display" 1 "Latent_PreWarning" 2 "PreWarning" 3 "AcuteWarning" 4 "Intervention" 5 "DriverTakeoverRequest" 6 "TurnWarning" 7 "BaseIntervention" 8 "RearIntervention";
VAL_ 319 SC_PreCrash_Texte 0 "No_Display" 1 "SystemMalfunction" 2 "No_SensorView" 3 "DemoMode" 4 "System_Off" 5 "TrailerOperation" 6 "ESC_Off" 7 "ToTime_Restricted" 8 "ToTime_Restricted_ESP_Off" 9 "Initialisation";
VAL_ 333 ACC_Limited_PullAwayDyn 0 "No_Limitation" 1 "Limitation_PullAwayDynamics_Requested";
VAL_ 333 ACC_Retrofit_Stop_Req 0 "Not_Requested" 1 "Requested";
VAL_ 333 ACC_StartStop_Info 0 "EngineRunning_LongTerm_Not_Necessary_StopEnable" 1 "EngineStartUp_Not_Mandatory_Necessary_StopInhibit_No_StartRequest" 2 "EngineStartUp_Mandatory_Necessary_StartRequest" 3 "SystemError";
VAL_ 333 ACC_TargetAcceleration_02 2046 "NeutralValue" 2047 "Error";
VAL_ 333 ACC_PullAway 0 "No_Request_PullAway" 1 "Request_PullAway";
VAL_ 333 ACC_Stop 0 "No_Stop_Requested" 1 "Stop_Requested";
VAL_ 333 ACC_Type 0 "Base_ACC" 1 "ACC_With_FollowToStop" 2 "ACC_With_StopAndGo" 3 "ACC_Not_Coded";
VAL_ 333 ACC_Status_ACC 0 "ACC_OFF_MainSwitch_Off" 1 "ACC_INIT" 2 "ACC_STANDBY" 3 "ACC_Active_Controls" 4 "ACC_OVERRIDE" 5 "ACC_ShutdownReaction" 6 "Reversible_Error_In_ACC_System" 7 "Irreversible_Error_In_ACC_System";
VAL_ 333 ACC_Minimum_Braking 0 "Request_Minimum_Braking_Not_Active" 1 "Request_Minimum_Braking_Active";
VAL_ 333 ACC_StoppingDistance 2046 "NeutralValue" 2047 "Error";
VAL_ 333 ACC_Request_HMS 0 "No_Request" 1 "Hold" 2 "Parking" 3 "Hold_Standby" 4 "PullAway" 5 "Release_Over_Ramp";
VAL_ 333 Accel_Boost 3 "Driving" 0 "Stop" 2 "Driving" 1 "Driving";
VAL_ 339 MO_HVEM_Escalation 0 "No_Escalation_HVEM" 1 "Escalation_HVEM";
VAL_ 339 MO_ExtGrenzen_Req 0 "normal" 1 "Extended";
VAL_ 339 MO_Error_Notentladung_Req 0 "Init";
VAL_ 339 MO_HVEM_MaxPower 510 "Init";
VAL_ 339 MO_HVK_EmActualState 0 "HvOff" 1 "HvStbyReq" 2 "HvStbyOk" 3 "HvBattOnReq" 4 "HvBattOnOk" 10 "HvOnIdle" 18 "HvOnDrvReq" 19 "HvOnDrvOk" 20 "HvOnDrvRdy" 28 "HvStepUpReq" 29 "HvStepUpOk" 30 "HvStepUp" 38 "HvStepDownReq" 39 "HvStepDownOk" 40 "HvStepDown" 46 "HvAcChPreReq" 47 "HvAcChPreOk" 48 "HvAcChReq" 49 "HvAcChOk" 50 "HvAcCh" 56 "HvDcChPreReq" 57 "HvDcChPreOk" 58 "HvDcChReq" 59 "HvDcChOk" 60 "HvDcCh" 67 "HvChOffReq" 68 "HvChOffOk" 69 "HvOnIdleReq" 70 "HvOnIdleOk" 96 "HvCpntOffReq" 97 "HvCpntOffOk" 98 "HvBattOffReq" 99 "HvBattOffOk" 109 "HvDcDcFailOffReq" 110 "HvDcDcFail" 119 "HvElmOffReq" 120 "HvElmOff" 126 "HvFailCpntOffReq" 127 "HvFailCpntOffOk" 128 "HvFailBattOffReq" 129 "HvFailBattOffOk" 130 "HvFailBattOff" 138 "HvFailUCtlReq" 139 "HvFailUCtlOk" 140 "HvFailUCtl" 150 "HvEmgcyOff" 255 "Init";
VAL_ 339 MO_HVK_DriveErrorStatus 0 "Component_IO" 6 "No_ComponentFunction" 7 "Init";
VAL_ 339 MO_MVK_VehicleElectrics_Req 0 "No_Request" 1 "VehicleElectricsActivity_gefordert";
VAL_ 339 MO_HVK_DriveState 0 "Drive_OFF" 1 "Drive_Startphase" 2 "E_Drive" 3 "Hybrid_Drive" 7 "Init";
VAL_ 339 MO_HVK_EmErrorStatus 0 "Component_IO" 1 "Restricted_CompressorFunc_Teilbetrieb" 3 "Restricted_CompressorFunc_Interlock" 6 "No_ComponentFunction" 7 "Init";
VAL_ 339 MO_MVK_DriveErrorStatus 0 "Component_IO" 6 "No_ComponentFunction" 7 "Init";
VAL_ 339 MO_MVK_DriveState 0 "Drive_OFF" 1 "Drive_Startphase" 2 "FreewheelEngineOff" 7 "Init";
VAL_ 339 MO_MVK_EmErrorStatus 0 "Component_IO" 1 "Restricted_CompressorFunc_Teilbetrieb" 6 "No_ComponentFunction" 7 "Init";
VAL_ 339 MO_MVK_EmActualState 0 "MvOff" 1 "MvStbyReq" 2 "MvStbyOk" 3 "MvBattOnReq" 4 "MvBattOnOk" 10 "MvOnIdle" 18 "MvOnDrvReq" 19 "MvOnDrvOk" 20 "MvOnDrv" 28 "MvStepUpReq" 29 "MvStepUpOk" 30 "MvStepUp" 38 "MvStepDownReq" 39 "MvStepDownOk" 40 "MvStepDown" 96 "MvCpntOffReq" 97 "MvCpntOffOk" 98 "MvBattOffReq" 99 "MvBattOffOk" 109 "MvDcDcFailOffReq" 110 "MvDcDcFail" 119 "MvElmFailOffReq" 120 "MvElmFail" 126 "MvFailCpntOffReq" 127 "MvFailCpntOffOk" 128 "MvFailBattOffReq" 129 "MvFailBattOffOk" 130 "MvFailBattOff" 138 "MvFailUCtlReq" 139 "MvFailUCtlOk" 140 "MvFailUCtl" 150 "MvEmgcyOff" 255 "Init";
VAL_ 420 EA_Parking_Retain_HMS 0 "Parking_Not_Retain" 1 "Parking_Retain" 2 "Init" 3 "Error";
VAL_ 420 EA_WarnJerkProfile 0 "No_JerkRequest" 1 "Profile_1" 2 "Profile_2" 3 "Profile_3" 4 "Profile_4" 5 "Profile_5" 6 "Profile_6" 7 "Profile_7";
VAL_ 420 EA_eCall_Req 0 "No_Request" 1 "Trigger_eCall";
VAL_ 420 EA_Funktionsstatus 0 "EA_INIT" 1 "EA_OFF" 2 "EA_STANDBY" 3 "EA_PHASE0_Active" 4 "EA_PHASE1_Active" 5 "EA_PHASE2_Active" 6 "EA_PHASE3_Active" 7 "EA_Reversible_Error" 8 "EA_Irreversible_Error";
VAL_ 420 EA_BeltTensioner_Req 0 "No_Request" 1 "Haptics_1" 2 "Haptics_2" 3 "Haptics_3";
VAL_ 420 EA_Request_HMS 0 "No_Request" 1 "Hold" 2 "Parking" 3 "Hold_Standby" 4 "PullAway" 5 "Release_Over_Ramp" 6 "Parking_With_P";
VAL_ 420 EA_TargetAcceleration 2046 "NeutralValue" 2047 "Error";
VAL_ 591 Distance_Status 0 "Valid" 3 "Invalid";
VAL_ 706 MO_Display_StSt_Text 0 "No_Display" 1 "SystemError" 2 "Engine_Manual_Start" 3 "Feedback_By_DriveRange_Engage" 4 "IgnitionShutoffWarning_Timerstart" 5 "To_EngineStart_Brake_Press" 6 "StSt_Activation_Not_Possible_Open_Grund_Fahrprogramm";
VAL_ 706 MO_Display_StSt_Symbol 0 "No_Display" 1 "StSt_Active" 2 "EngineRunning_Needed" 3 "Driver_Temporary_abwesend" 4 "Driver_vielleicht_anwesend";
VAL_ 706 MO_ADDR_Status 0 "Not_Active" 1 "ADDR_Requested" 2 "ADDR_Active" 3 "ADDR_Error";
VAL_ 706 MO_AGA_Sound_Texte 0 "No_Display" 1 "Sound_off" 2 "Sound_on";
VAL_ 706 MO_Display_FMOff_Text 0 "No_Display" 1 "FMOff_SystemError";
VAL_ 706 MO_Error_MSpG 0 "i.O." 1 "Gebl䳥 Defective Or Motorraumtemp. Closed High";
VAL_ 706 PEA_Texte 0 "No_Display" 1 "PEA_DriverTakeover_Needed" 2 "PEA_Recup_Not_Available";
VAL_ 706 TSK_Overruled_vMax_DriverInfo 0 "Not_ueberstimmbar" 1 "ueberstimmbar" 2 "Overruled";
VAL_ 706 MO_Avus_EngineProtection 0 "No Warning" 1 "RpmWarning Stage 1" 2 "RpmWarning Stage 2" 3 "RpmWarning Stage 3";
VAL_ 706 MO_RecuperationStage 0 "No_Display" 1 "RecuperationStage_1" 2 "RecuperationStage_2" 3 "RecuperationStage_3" 4 "RecuperationStage_4" 5 "RecuperationStage_5" 6 "RecuperationStage_auto" 7 "Init";
VAL_ 706 TSK_Unit_vMax_DriverInfo 0 "km_h" 1 "mph";
VAL_ 706 TSK_Status_vMax_DriverInfo 0 "No_Display" 1 "Display_In_VehicleStatus" 2 "PopUp_Without_Chime__Eintrag_FhzStatus" 3 "PopUp_With_Chime__Eintrag_FhzStatus";
VAL_ 706 MO_Red_DrivePower 0 "No_Display" 1 "Small_Red" 2 "Average_Red_temp" 3 "Average_Red" 4 "grosse_Red_temp" 5 "grosse_Red";
VAL_ 706 MO_Disp_RadiatorFan 0 "No_RadiatorFanRunOn" 1 "Text_FanRunOn_Active" 2 "Text_FanRunOn_DPF_Active" 3 "Placeholder_Further_Signals" 4 "Placeholder_Further_Signals" 5 "Placeholder_Further_Signals" 6 "Placeholder_Further_Signals" 7 "Placeholder_Further_Signals";
VAL_ 706 MO_In_Idle 0 "Not_In_Idle" 1 "In_Idle";
VAL_ 706 WIV_Enable_OilPressure_Engine 0 "OilPressureEvaluation_In_Cluster" 1 "OilPressureEvaluation_In_MSG";
VAL_ 706 MO_OilMeasurement_Duration 15 "No_Measurement_Active";
VAL_ 706 TSK_vMax_DriverInfo 0 "Init___No_Value";
VAL_ 795 ESP_Lamp 0 "Off" 1 "On";
VAL_ 795 ABS_Lamp 0 "Off" 1 "On";
VAL_ 795 BK_Lamp_02 0 "Off" 1 "On_Static" 3 "Warning";
VAL_ 795 TC_Lamp 0 "Off" 1 "On";
VAL_ 795 ESP_m_WheelSpeed 32765 "Undervoltage" 32766 "Init" 32767 "Error";
VAL_ 795 ESP_Textanzeigen_03 0 "No_Text" 1 "ESP_Malfunction" 2 "ABS_Malfunction" 3 "ESP_ABS_Malfunction" 4 "Workshop_Brake" 5 "ASR_Malfunction" 6 "ESP_switched_off" 7 "ASR_off" 8 "ESP_ASR_on" 10 "No_BrakeForceAmplification" 11 "ASR_Activated" 12 "ABS_ASR_Malfunction" 15 "ESP_offroad" 17 "ESP_sport" 18 "ESP_ForcedActivation" 19 "ESP_PushButton_Info" 20 "TC_Active" 21 "Reserved_For_Verlwarn" 22 "TC_switched_off" 23 "Verlwarn_Act_Rollsicher_inakt" 24 "ESP_SuperSport" 25 "ESP_Offroad_Not_Available";
VAL_ 795 ESP_Meldungen 0 "No_Display" 1 "AutoHold_Notice_1" 2 "Malfunction_AutoHold" 3 "Malfunction_HillHold" 4 "TakeOver" 5 "AutoHold_Off" 6 "AutoHold_Notice_2";
VAL_ 795 ESP_ErrorStatus_DistPulse 0 "DistancePulses_iO" 1 "Error";
VAL_ 795 ESP_DistPulse_Overflow 0 "Reset_And_No_Overflow" 1 "AtLeast_1x_Overflow";
VAL_ 795 ESP_QBit_DistPulse_VA 0 "Valid_Value" 1 "Substitute_Init_Or_ErrorValue";
VAL_ 795 ESP_HDC_Speed_Colour 0 "Standard_Colour" 1 "abweichende_Colour";
VAL_ 795 ESP_Off_Lamp 0 "Lamp_Off" 1 "Lamp_On";
VAL_ 795 ESP_HDC_ControlSpeed 0 "Not_Fitted" 125 "HDC_Standby" 126 "Init" 127 "Error";
VAL_ 795 ESP_BKV_Warning 0 "No_Display" 1 "No_BrakeForceAmplification";
VAL_ 817 MFL_LocalActive 0 "Was_Not_Local_Active" 1 "Was_Local_Active";
VAL_ 817 MFL_M_Key 0 "Not_Pressed" 1 "Pressed";
VAL_ 817 MFL_Paddle_Fitment 0 "Fitted" 1 "Not_Fitted";
VAL_ 817 MFL_KeyCode_1 0 "Key_Released__No_Key" 1 "Context_Menu" 2 "Menu_Up__Next_Screen" 3 "Menu_Down__Previous_Screen" 4 "Up" 5 "Down" 6 "Up__Down_ThumbWheel" 7 "OK__ThumbWheel_Button" 8 "Cancel__Escape" 9 "Main_Menu" 10 "Side_Menu_left" 11 "Side_Menu_right" 12 "FAS_Menu" 13 "Left__Right_ThumbWheel" 14 "FAS_Menu_ThumbWheel" 16 "Volume_Up" 17 "Volume_Down" 18 "Volume_Up__Down_ThumbWheel" 19 "Volume_ThumbWheel_Button" 20 "Audio_Source" 21 "Arrow_A_Up__Right" 22 "Arrow_A_Down__Left" 23 "Arrow_B_Up__Right" 24 "Arrow_B_Down__Left" 25 "PTT__PushToTalk" 26 "PTT_Cancel" 27 "Route_Info" 28 "Hook" 29 "Hang_Up" 30 "Off_Hook" 31 "Light_On__Off" 32 "Mute" 33 "Joker1" 34 "Joker2" 35 "View" 36 "Arrow_A_Up__Down_ThumbWheel" 37 "SteeringWheelHeating" 38 "Recuperation" 39 "Tube_Toggle" 40 "DRS_Drag_Reduction_System" 41 "Stopwatch_Start_Stop" 42 "Stopwatch_Nextlap" 100 "MAP" 101 "MAP_Boost" 102 "Turn_signal_left" 103 "Turn_signal_right" 104 "Turn_signal_off" 105 "Flashlight" 106 "Highbeam" 107 "Washer_button" 108 "Wiper_button_left" 109 "Wiper_button_right" 110 "Wiper_button_cancel" 111 "Exhaust_Sound" 112 "Drive_Select_button" 113 "Sport_button" 114 "ESP_Drift_Selection_ThumbWheel" 115 "PTT_special_vehicle" 116 "TravelAssist" 117 "Launch_Control" 118 "Drift_Mode_Button_Increase" 119 "Drift_Mode_Button_Decrease" 120 "Drift_Mode_Button_Select" 121 "Drive_Mode_Button_Increase" 122 "Drive_Mode_Button_Decrease" 123 "Drive_Mode_Button_Select" 124 "E_Boost_Button_Increase" 125 "E_Boost_Button_Decrease" 126 "E_Boost_Button_Select" 127 "PerformanceHybridButton_Increase" 128 "PerformanceHybridButton_Decrease" 129 "EV_Mode_Button" 130 "HUD_Button" 131 "PASM_Wheel" 132 "PASM_Button" 133 "PTV_Wheel" 134 "PTV_Button" 135 "TC_ESC_Wheel" 136 "TC_ESC_Button" 240 "Startup_Reset" 241 "Initialization";
VAL_ 817 MFL_KeyCode_2 0 "Key_Released__No_Key" 1 "Context_Menu" 2 "Menu_Up__Next_Screen" 3 "Menu_Down__Previous_Screen" 4 "Up" 5 "Down" 6 "Up__Down_ThumbWheel" 7 "OK__ThumbWheel_Button" 8 "Cancel__Escape" 9 "Main_Menu" 10 "Side_Menu_left" 11 "Side_Menu_right" 12 "FAS_Menu" 13 "Left__Right_ThumbWheel" 14 "FAS_Menu_ThumbWheel" 16 "Volume_Up" 17 "Volume_Down" 18 "Volume_Up__Down_ThumbWheel" 19 "Volume_ThumbWheel_Button" 20 "Audio_Source" 21 "Arrow_A_Up__Right" 22 "Arrow_A_Down__Left" 23 "Arrow_B_Up__Right" 24 "Arrow_B_Down__Left" 25 "PTT__PushToTalk" 26 "PTT_Cancel" 27 "Route_Info" 28 "Hook" 29 "Hang_Up" 30 "Off_Hook" 31 "Light_On__Off" 32 "Mute" 33 "Joker1" 34 "Joker2" 35 "View" 36 "Arrow_A_Up_Right_Down_Left_ThumbWheel" 37 "SteeringWheelHeating" 38 "Recuperation" 39 "Tube_Toggle" 40 "DRS_Drag_Reduction_System" 41 "Stopwatch_Start_Stop" 42 "Stopwatch_Nextlap" 100 "MAP" 101 "MAP_Boost" 102 "Turn_signal_left" 103 "Turn_signal_right" 104 "Turn_signal_off" 105 "Flashlight" 106 "Highbeam" 107 "Washer_button" 108 "Wiper_button_left" 109 "Wiper_button_right" 110 "Wiper_button_cancel" 111 "Exhaust_Sound" 112 "Drive_Select_button" 113 "Sport_button" 114 "ESP_Drift_Selection_ThumbWheel" 115 "PTT_special_vehicle" 116 "TravelAssist" 117 "Launch_Control" 118 "Drift_Mode_Button_Increase" 119 "Drift_Mode_Button_Decrease" 120 "Drift_Mode_Button_Select" 121 "Drive_Mode_Button_Increase" 122 "Drive_Mode_Button_Decrease" 123 "Drive_Mode_Button_Select" 124 "E_Boost_Button_Increase" 125 "E_Boost_Button_Decrease" 126 "E_Boost_Button_Select" 127 "PerformanceHybridButton_Increase" 128 "PerformanceHybridButton_Decrease" 129 "EV_Mode_Button" 130 "HUD_Button" 131 "PASM_Wheel" 132 "PASM_Button" 133 "PTV_Wheel" 134 "PTV_Button" 135 "TC_ESC_Wheel" 136 "TC_ESC_Button" 240 "Startup_Reset" 241 "Initialization";
VAL_ 817 MFL_Eventcode_1 0 "W_no_event____T_no_event" 1 "W_1_Tick_up__T_pressed_normal" 2 "W_2_Ticks_up__T_touched" 3 "W_3_Ticks_up__T_double_click_nor" 4 "W_4_Ticks_up__T_long_press_nor_1" 5 "W_5_Ticks_up__T_long_press_nor_2" 6 "W_6_Ticks_up__T_long_press_nor_3" 7 "W_7_Ticks_up" 9 "W_7_Ticks_dn__T_pressed_strong" 10 "W_6_Ticks_dn" 11 "W_5_Ticks_dn__T_double_click_str" 12 "W_4_Ticks_dn__T_long_press_str_1" 13 "W_3_Ticks_dn__T_long_press_str_2" 14 "W_2_Ticks_dn__T_long_press_str_3" 15 "W_1_Tick_dn";
VAL_ 817 MFL_Eventcode_2 0 "W_no_event____T_no_event" 1 "W_1_Tick_up__T_pressed_normal" 2 "W_2_Ticks_up__T_touched" 3 "W_3_Ticks_up__T_double_click_nor" 4 "W_4_Ticks_up__T_long_press_nor_1" 5 "W_5_Ticks_up__T_long_press_nor_2" 6 "W_6_Ticks_up__T_long_press_nor_3" 7 "W_7_Ticks_up" 9 "W_7_Ticks_dn__T_pressed_strong" 10 "W_6_Ticks_dn" 11 "W_5_Ticks_dn__T_double_click_str" 12 "W_4_Ticks_dn__T_long_press_str_1" 13 "W_3_Ticks_dn__T_long_press_str_2" 14 "W_2_Ticks_dn__T_long_press_str_3" 15 "W_1_Tick_dn";
VAL_ 817 MFL_Brand 0 "VW" 1 "Audi" 2 "Seat" 3 "Skoda" 4 "VW_Nutzf" 5 "Bugatti" 6 "Lamborghini" 7 "Bentley" 8 "Rolls Royce" 9 "Quattro" 10 "No_Manufacturer_1" 11 "No_Manufacturer_2" 12 "No_Manufacturer_3" 13 "No_Manufacturer_4" 14 "Ford" 15 "Porsche";
VAL_ 817 MFL_Tip_Down 0 "Not_Pressed" 1 "Pressed";
VAL_ 817 MFL_Tip_Up 0 "Not_Pressed" 1 "Pressed";
VAL_ 817 MFL_SatModule_Left_Err 0 "No_Error" 1 "Error";
VAL_ 817 MFL_SatModule_Right_Err 0 "No_Error" 1 "Error";
VAL_ 817 MFL_LR_HZG_Status 0 "Inactive" 1 "Active";
VAL_ 817 MFL_LR_HZG_Err 0 "normal" 1 "Error";
VAL_ 817 MFL_Horn 0 "Not_Pressed" 1 "Pressed";
VAL_ 817 MFL_Horn_Err 0 "normal" 1 "Error";
VAL_ 817 MFL_Tip_Left_Err 0 "normal" 1 "Error";
VAL_ 817 MFL_Tip_Right_Err 0 "normal" 1 "Error";
VAL_ 817 MFL_Key_Left_Err 0 "normal" 1 "Error";
VAL_ 817 MFL_Key_Right_Err 0 "normal" 1 "Error";
VAL_ 817 MFL_ECU_Err 0 "normal" 1 "Error";
VAL_ 817 MFL_Response_Err 0 "normal" 1 "Error";
VAL_ 850 Parking_SM_03_MUX 0 "MUX_Group_PointInfo_0" 1 "MUX_Group_PointInfo_1" 2 "MUX_Group_PointInfo_2" 3 "MUX_Group_PointInfo_3" 4 "MUX_Group_PointInfo_4" 5 "MUX_Group_PointInfo_5" 6 "MUX_Group_PointInfo_6";
VAL_ 850 Parking_SM_03_Traj_Trans_ID_00 0 "Transaction_ID_0" 1 "Transaction_ID_1" 2 "Transaction_ID_2" 3 "Transaction_ID_3" 4 "Transaction_ID_4" 5 "Transaction_ID_5" 6 "Transaction_ID_6" 7 "Transaction_ID_7" 8 "Transaction_ID_8" 9 "Transaction_ID_9" 10 "Transaction_ID_10" 11 "Transaction_ID_11" 12 "Transaction_ID_12" 13 "Transaction_ID_13" 14 "Transaction_ID_14" 15 "Transaction_ID_15";
VAL_ 850 Parking_SM_03_Traj_Trans_ID_01 0 "Transaction_ID_0" 1 "Transaction_ID_1" 2 "Transaction_ID_2" 3 "Transaction_ID_3" 4 "Transaction_ID_4" 5 "Transaction_ID_5" 6 "Transaction_ID_6" 7 "Transaction_ID_7" 8 "Transaction_ID_8" 9 "Transaction_ID_9" 10 "Transaction_ID_10" 11 "Transaction_ID_11" 12 "Transaction_ID_12" 13 "Transaction_ID_13" 14 "Transaction_ID_14" 15 "Transaction_ID_15";
VAL_ 850 Parking_SM_03_Traj_Trans_ID_02 0 "Transaction_ID_0" 1 "Transaction_ID_1" 2 "Transaction_ID_2" 3 "Transaction_ID_3" 4 "Transaction_ID_4" 5 "Transaction_ID_5" 6 "Transaction_ID_6" 7 "Transaction_ID_7" 8 "Transaction_ID_8" 9 "Transaction_ID_9" 10 "Transaction_ID_10" 11 "Transaction_ID_11" 12 "Transaction_ID_12" 13 "Transaction_ID_13" 14 "Transaction_ID_14" 15 "Transaction_ID_15";
VAL_ 850 Parking_SM_03_Traj_Trans_ID_03 0 "Transaction_ID_0" 1 "Transaction_ID_1" 2 "Transaction_ID_2" 3 "Transaction_ID_3" 4 "Transaction_ID_4" 5 "Transaction_ID_5" 6 "Transaction_ID_6" 7 "Transaction_ID_7" 8 "Transaction_ID_8" 9 "Transaction_ID_9" 10 "Transaction_ID_10" 11 "Transaction_ID_11" 12 "Transaction_ID_12" 13 "Transaction_ID_13" 14 "Transaction_ID_14" 15 "Transaction_ID_15";
VAL_ 850 Parking_SM_03_Traj_Trans_ID_04 0 "Transaction_ID_0" 1 "Transaction_ID_1" 2 "Transaction_ID_2" 3 "Transaction_ID_3" 4 "Transaction_ID_4" 5 "Transaction_ID_5" 6 "Transaction_ID_6" 7 "Transaction_ID_7" 8 "Transaction_ID_8" 9 "Transaction_ID_9" 10 "Transaction_ID_10" 11 "Transaction_ID_11" 12 "Transaction_ID_12" 13 "Transaction_ID_13" 14 "Transaction_ID_14" 15 "Transaction_ID_15";
VAL_ 850 Parking_SM_03_Traj_Trans_ID_05 0 "Transaction_ID_0" 1 "Transaction_ID_1" 2 "Transaction_ID_2" 3 "Transaction_ID_3" 4 "Transaction_ID_4" 5 "Transaction_ID_5" 6 "Transaction_ID_6" 7 "Transaction_ID_7" 8 "Transaction_ID_8" 9 "Transaction_ID_9" 10 "Transaction_ID_10" 11 "Transaction_ID_11" 12 "Transaction_ID_12" 13 "Transaction_ID_13" 14 "Transaction_ID_14" 15 "Transaction_ID_15";
VAL_ 850 Parking_SM_03_Traj_Trans_ID_06 0 "Transaction_ID_0" 1 "Transaction_ID_1" 2 "Transaction_ID_2" 3 "Transaction_ID_3" 4 "Transaction_ID_4" 5 "Transaction_ID_5" 6 "Transaction_ID_6" 7 "Transaction_ID_7" 8 "Transaction_ID_8" 9 "Transaction_ID_9" 10 "Transaction_ID_10" 11 "Transaction_ID_11" 12 "Transaction_ID_12" 13 "Transaction_ID_13" 14 "Transaction_ID_14" 15 "Transaction_ID_15";
VAL_ 869 NVEM_Pilot_Info 0 "Init" 1 "No_Restriction" 2 "Veto_1" 3 "Veto_2";
VAL_ 869 NVEM_P_Alternator_Status 0 "Filtered" 1 "Unfiltered";
VAL_ 869 BEM_P_Alternator 255 "Error";
VAL_ 869 BEM_n_LLA 0 "No_Increase" 1 "Stage_1" 2 "Stage_2" 3 "Stage_3";
VAL_ 869 BEM_Req_TERM 0 "No Request" 1 "Request RadiatorFan Actuation";
VAL_ 869 BEM_StartStop_Info 0 "EngineRunning_Not_Necessary_(StopEnable)" 1 "EngineStartUp_Not_Mandatory_Necessary_(StopInhibit,No_StartRequest)" 2 "EngineStartUp_Mandatory_Necessary_(StartRequest)" 3 "SystemError";
VAL_ 869 BEM_Batt_From 0 "verbunden" 1 "Not_verbunden";
VAL_ 869 BEM_Hybrid_Info 0 "No_Restriction_By_EnergyManagement" 1 "EngineStart_Over_12V_Starter_Only_At_0kmh_Possible" 2 "No_EngineStart_Over_12V_Starter_After_el_JourneyOperation" 3 "SystemError";
VAL_ 869 NVEM_Red_TERM 0 "Init" 1 "Shutdown_TERM" 2 "Reduzierung_TERM";
VAL_ 869 NVEM_Freewheel_Info 0 "Freewheel_Enabled" 1 "Weiches_Veto_uebertippbar" 2 "Hartes_Veto_Abort" 3 "Freewheel_Request";
VAL_ 869 BEM_HYB_DC_uMinLV 254 "Init" 255 "Error";
VAL_ 870 BM_ZV_Open 0 "Inactive" 1 "Active";
VAL_ 870 BM_ZV_Closed 0 "Inactive" 1 "Active";
VAL_ 870 BM_DWA_On 0 "Inactive" 1 "Active";
VAL_ 870 BM_DWA_Alarm 0 "Inactive" 1 "Active";
VAL_ 870 BM_Crash 0 "Inactive" 1 "Active";
VAL_ 870 BM_Panic 0 "Inactive" 1 "Active";
VAL_ 870 BM_Not_Braking 0 "Inactive" 1 "Active";
VAL_ 870 BM_GDO 0 "Inactive" 1 "Active";
VAL_ 870 BM_HazardFlash 0 "Inactive" 1 "Active";
VAL_ 870 BM_Taxi_Notalarm 0 "Inactive" 1 "Active";
VAL_ 870 BM_Telematics 0 "Inactive" 1 "Active";
VAL_ 870 BM_Left 0 "Inactive" 1 "Active";
VAL_ 870 BM_Right 0 "Inactive" 1 "Active";
VAL_ 870 Flash_Left_Veh_Clock 0 "Indicator_Left_SwitchedOff" 1 "Indicator_Left_SwitchedOn";
VAL_ 870 Flash_Right_Veh_Clock 0 "Indicator_Right_SwitchedOff" 1 "Indicator_Right_SwitchedOn";
VAL_ 870 Flash_Left_Cluster_Clock 0 "IndicatorTellTale_Left_SwitchedOff" 1 "IndicatorTellTale_Left_SwitchedOn";
VAL_ 870 Flash_Right_Cluster_Clock 0 "IndicatorTellTale_Right_SwitchedOff" 1 "IndicatorTellTale_Right_SwitchedOn";
VAL_ 870 BM_NBA_n_Coded_n_Active 0 "Coded_AND_No_Error" 1 "Not_Coded_OR_Error_Detected";
VAL_ 870 BM_NBA_Status 0 "NBA_Not_Active" 1 "BRL_Dunkelphase" 3 "BRL_Hellphase";
VAL_ 870 BM_WBT_Lighting 0 "Inactive" 1 "Active";
VAL_ 870 BM_HD_Opening_angelernt 0 "No_Quittierung" 1 "Quittierung";
VAL_ 870 BM_Motorway 0 "Inactive" 1 "Active";
VAL_ 870 BM_RollerMode_Flash 0 "Inactive" 1 "Active";
VAL_ 870 BM_Recas 0 "Inactive" 1 "Active";
VAL_ 870 BM_Wischblinken 0 "Inactive" 1 "Active";
VAL_ 870 BM_Telematics_Abbruchgrund 0 "Init" 1 "speed_out_of_range" 2 "defect" 3 "clamp_s_on" 4 "clamp_15_on" 5 "door_open" 6 "engine_hood_open" 7 "trunk_open" 8 "convertible_top_not_locked" 9 "horn_activated_by_user" 10 "Higher_Prioritiy_Function_active" 11 "Central_Lock_status_changed" 12 "Request_Dropped_by_Requester" 13 "Service_Duration_Expired" 14 "not_possible_due_to_coding" 15 "no_reason_or_unknown_timeout";
VAL_ 870 BM_PiloPa 0 "PiloPa_Blinkerquittierung_Inactive" 1 "PiloPa_Blinkerquittierung_Active";
VAL_ 870 DWA_Alarmquelle 0 "No_Ausloesegrund" 1 "DoorContact_DriverDoor" 2 "DoorContact_PassengerDoor" 3 "DoorContact_Rear_Left" 4 "DoorContact_Rear_Right" 5 "BonnetContact_Front" 6 "Kofferraum_Rear" 7 "Masseschleife_The_RearWindow" 8 "Innenraumueberwachung" 9 "Alarm_By_Noteinstieg" 10 "Sounder" 11 "Neigungssensor" 12 "DoorECU_FT_At_CAN_Bus" 13 "DoorECU_BT_At_CAN_Bus" 14 "DoorECU_HFS_At_CAN_Bus" 15 "DoorECU_HBFS_At_CAN_Bus" 16 "Terminal_15" 17 "Terminal_15sig" 18 "Free" 19 "TrailerMonitoring" 20 "Scheinwerferueberwachung_Left" 21 "Scheinwerferueberwachung_Right" 22 "Handschuhkasten" 23 "RoofMonitoring" 24 "OBD_Alarm" 25 "Power_on_Reset" 30 "Init" 31 "Error";
VAL_ 888 GNSS_Location_Height 4094 "Init" 4095 "Error";
VAL_ 891 GNSS_UTC_Time 0 "Init";
VAL_ 891 GNSS_Receiver_Status 0 "Backup_Mode" 1 "Live";
VAL_ 891 GNSS_GPS_in_Use 0 "unbenutzt" 1 "benutzt";
VAL_ 891 GNSS_GLONASS_in_Use 0 "unbenutzt" 1 "benutzt";
VAL_ 891 GNSS_Empfangbare_Satellites 0 "Init" 31 "31_Or_More";
VAL_ 891 GNSS_Sichtbare_Satellites 0 "Init" 31 "31_Or_More";
VAL_ 891 GNSS_Genutzte_Satellites 0 "Init" 31 "31_Or_More";
VAL_ 916 WBA_DriveRange_02 0 "BetweenPosition_No_Position" 1 "Position_P" 2 "Position_R" 3 "Position_N" 4 "Position_D" 5 "Position_S" 6 "Position_M_Tippfunktion" 7 "ShortTime_M" 8 "Position_E" 9 "Position_MS" 10 "Position_S_Plus" 11 "Position_MS_Plus" 12 "Position_Offroad" 13 "Position_B";
VAL_ 916 WBA_TargetDriveRange 0 "No_GearRecommendation_No_Gear_Engaged" 1 "Arrow_After_S" 2 "Arrow_After_D" 3 "Arrow_After_M" 4 "Arrow_After_E";
VAL_ 916 WBA_GE_Warning_02 0 "No_Display" 1 "ErrorEscalationLevel_I" 2 "ErrorEscalationLevel_II" 3 "Weiterfahrt_Only_Restricted_Possible__No_R_Gear" 4 "GearboxError_Weiterfahrt_Only_in_D_Possible__P_At_Engine_Off" 5 "Wegrollgefahr__P_Not_Possible" 6 "Paddlenotbetrieb_Schema+Warning" 7 "Paddlenotbetrieb_Schema" 8 "SpeedLimit_LimpHome" 9 "Fehlereskalationsst_o_Restrict" 10 "ErrorEscalationLevel_v_Limit" 11 "ParkLock_InfoLevel" 12 "ParkLock_WarningLevel_I" 13 "ParkLock_WarningLevel_II";
VAL_ 916 WBA_Input_Gear_02 0 "No_GearDisplay" 1 "Gear_1" 2 "Gear_2" 3 "Gear_3" 4 "Gear_4" 5 "Gear_5" 6 "Gear_6" 7 "Gear_7" 8 "Gear_8" 9 "Gear_9" 10 "Function_GearDisplaySuppression" 11 "Gear_10";
VAL_ 916 WBA_GE_Texte 0 "No_Display" 1 "To_Engage_A_DriveRange_Fussbremse_Press__ShiftLock_Information" 2 "To_Engage_From_R_N_D_Fussbremse_Press_And_Engine_Start" 3 "Wegrollgefahr_Please_P_Engage" 4 "Caution_TimeExceedance_P_Is_Engaged" 5 "Wiederanmeldeprozedur_Brake_Press" 6 "P_Only_In_Standstill_Possible" 7 "Rennstart_Active";
VAL_ 916 WBA_Coasting_Active 0 "Inactive" 1 "Active";
VAL_ 916 WBA_ShiftPattern 0 "No_ShiftPattern" 1 "xxxD(S)" 2 "xxxD_S" 3 "xxxS(D)" 4 "xxxS_D" 5 "xxxM(D)" 6 "xxxM_D" 7 "xxxM(S)" 8 "xxxM_S" 9 "xxxE(D)" 10 "xxxE_D" 11 "xxxE(S)" 12 "xxxE_S" 13 "xxxE(M)" 14 "xxxE_M";
VAL_ 916 WBA_GE_AdditionalWarnings 0 "No_Display" 1 "Getriebeueberhitzung_WarningLevel_I" 2 "Getriebeueberhitzung_WarningLevel_II" 3 "GearboxError_Please_Stop_And_P_Engage";
VAL_ 916 GE_TargetGear 0 "No_Recommendation" 1 "Gear_1" 2 "Gear_2" 3 "Gear_3" 4 "Gear_4" 5 "Gear_5" 6 "Gear_6" 7 "Gear_7" 8 "Gear_8" 9 "Gear_9" 11 "Gear_10";
VAL_ 916 GE_TipShiftRecommend_Available 0 "Not_Available" 1 "Available";
VAL_ 916 WBA_GE_Texte_02 0 "No_Display" 1 "Fahrtrichtungswechsel_Only_After_Stillstandt" 2 "ChargePlug_Inserted" 3 "zusaetzlicher_Service_Required" 4 "eLaunch_Active" 5 "eLaunch_Not_Possible" 6 "WH_S_Not_Possible_Offroad" 7 "WH_S_Not_Possible_RangeMode";
VAL_ 916 WBA_GE_Texte_03 0 "init" 1 "LC_not_available" 2 "LCperformance_not_possible" 3 "LCperformance_possible" 4 "LCperformance_armed" 5 "LCperformance_preparation" 6 "LCperformance_launch" 7 "LCperformance_aborted" 8 "LCsmoke_not_possible" 9 "LCsmoke_possible" 10 "LCsmoke_armed" 11 "LCsmoke_launch" 12 "LCsmoke_aborted" 15 "Error";
VAL_ 916 WBA_Flash 0 "No_WBA_Flash" 1 "WBA_Flash";
VAL_ 916 GE_Restart_Disp_Std 0 "No_Display" 1 "Standard_Wiederstartgrund";
VAL_ 916 GE_StopInhibit_Disp_01 0 "No_Display" 1 "Temperaturbedingung";
VAL_ 916 GE_StopInhibit_Disp_02 0 "No_Display" 1 "Drucksensorausfall";
VAL_ 916 GE_StopInhibit_Disp_03 0 "No_Display" 1 "Grundeinstellung";
VAL_ 916 GE_StopInhibit_Disp_04 0 "No_Display" 1 "Demontagestellung";
VAL_ 916 GE_StopInhibit_Disp_05 0 "No_Display" 1 "Eingeschraenkte_DriveFunction_LimpHome_Liegenbleiber";
VAL_ 916 GE_StopInhibit_Disp_06 0 "No_Display" 1 "StopInhibit_Over_Applikation";
VAL_ 916 GE_StopInhibit_Disp_07 0 "No_Display" 1 "Shift_Active";
VAL_ 916 GE_StopInhibit_Disp_Std 0 "No_Display" 1 "Standard_Stoppvetogrund";
VAL_ 919 LDW_Chime 1 "Chime" 2 "Beep" 0 "None";
VAL_ 919 LDW_Texte 8 "laneAssistTakeOver" 4 "laneAssistTakeOverUrgent" 0 "none";
VAL_ 949 TERM_Rpm_Trailer 0 "No_Raise" 1 "RpmIncrease_From_Engine_Requested";
VAL_ 949 TERM_PreWarn_Compressor_On 0 "Init" 1 "PreWarning_Compressor_On";
VAL_ 949 TERM_AC_Switch 0 "Off" 1 "On";
VAL_ 949 TERM_Compressor_Torque_Old 1 "Outdated_bzw_Ermittlung_Of_Moments_Not_Possible__zB_No_Rpm_No_RefrigerantPressure";
VAL_ 949 TERM_PreWarn_AuxHeater_On 0 "No_PreWarning" 1 "PreWarning_AuxHeater_On";
VAL_ 949 TERM_State 0 "Off" 1 "On";
VAL_ 949 TERM_CompressorClutch_linear 253 "Full_Actuation" 254 "Init__Not_bedient";
VAL_ 949 TERM_Charisma_DrivePr 0 "No_Function" 1 "Programm_1" 2 "Programm_2" 3 "Programm_3" 4 "Programm_4" 5 "Programm_5" 6 "Programm_6" 7 "Programm_7" 8 "Programm_8" 9 "Programm_9" 10 "Programm_10" 11 "Programm_11" 12 "Programm_12" 13 "Programm_13" 14 "Programm_14" 15 "Programm_15";
VAL_ 949 TERM_Charisma_Status 0 "Init" 1 "Available" 2 "Not_Available" 3 "Asynchronous_By_DriverDemand";
VAL_ 949 TERM_Retrofit_Stop_Req 0 "Not_Requested" 1 "Requested";
VAL_ 949 TERM_T_Charge 0 "PushButton_Not_Pressed" 1 "PushButton_Pressed";
VAL_ 949 TERM_Load_Compressor 255 "Error";
VAL_ 949 TERM_Voltage_Req 0 "No_Request" 1 "Request_Stage_1" 2 "Request_Stage_2" 3 "Request_Stage_3";
VAL_ 949 TERM_ThermalManagement 0 "No_Enable_TMM__max_HeatDemand" 1 "Small_Enable_TMM" 2 "Average_Enable_TMM" 3 "Full_Enable_TMM__No_HeatDemand";
VAL_ 949 TERM_StartStop_Info 0 "EngineRunning_Not_Necessary_(StopEnable)" 1 "EngineStartUp_Not_Mandatory_Necessary_(StopInhibit,No_StartRequest)" 2 "EngineStartUp_Mandatory_Necessary_(StartRequest)" 3 "SystemError";
VAL_ 949 TERM_Freewheel_Info 0 "Freewheel_Enabled" 1 "OverGear_in_Freewheel_unzulaessig" 2 "Freewheel_Not_Enabled_Abort" 3 "Freewheel_Request";
VAL_ 949 TERM_Req_TERM 255 "Error";
VAL_ 949 TERM_el_AuxHeater_Stage 0 "Off" 1 "Stage_1" 2 "Stage_2" 3 "Stage_3";
VAL_ 949 TERM_Ausstattung_Climate 0 "Heating_elektrisch" 1 "ClimateManual_elektrisch" 2 "Climatic__1_Zone" 3 "Climatronic__1_Zone" 4 "Climatronic__2_Zones" 5 "Climatronic__3_Zones" 6 "Climatronic__4_Zones" 7 "Reserved";
VAL_ 949 TERM_Variant_AuxHeater 0 "WaterAuxHeater_60_min_Runtime" 1 "AirAuxHeater_120_min_Runtime" 2 "WaterAuxHeater_120_min_Runtime" 3 "Water_And_AirAuxHeater_120_min_Runtime";
VAL_ 958 MO_StartStop_Status 0 "System_in_diesem_TERM15_Cycle_Not_Available" 1 "System_Active_No_Enable_By_StartStop_Koordinator" 2 "System_Active_All_Enables_liegen_Before" 3 "System_Active_AtLeast_A_Enable_Missing";
VAL_ 958 MO_StartStop_Restart 0 "Restart_Inactive" 1 "Restart_Active";
VAL_ 958 MO_StartStop_EngineStop 0 "Engine_Stop_Inactive" 1 "Engine_Stop_Active";
VAL_ 958 MO_Enable_Recup 0 "Recuperation-Mode Off" 1 "Recommendation VoltageIncrease" 2 "Recommendation VoltageDecrease" 3 "RecuperationMode Active, VoltageVariation Not Necessary";
VAL_ 958 MO_Term_75 0 "Off" 1 "On";
VAL_ 958 MO_Term_50 0 "Off" 1 "TERM50_On_Startausfuehrung_Driver";
VAL_ 958 MO_GearPosition 0 "Gear_N" 1 "Gear_1" 2 "Gear_2" 3 "Gear_3" 4 "Gear_4" 5 "Gear_5" 6 "Gear_6" 7 "Gear_7" 8 "Gear_8" 9 "Automatic_P" 10 "Automatic_Forward_S" 11 "Automatic_Forward_D/E" 12 "BetweenPosition" 13 "Gear_R" 14 "ActualGear_Not_Defined" 15 "Error";
VAL_ 958 MO_StartStop_DriverDemand 0 "Init" 1 "StopInhibit_By_Driver" 2 "StopEnable_By_Driver" 3 "StopRequest_By_Driver";
VAL_ 958 MO_HYB_ReadyToDrive 0 "No_ReadyToDrive" 1 "ReadyToDrive";
VAL_ 958 MO_Ext_E_Journey_Active 0 "Feedback_E_PushButton_Off" 1 "Feedback_E_PushButton_On";
VAL_ 958 MO_Driver_Brakes 0 "No_Brakes" 1 "Brake_Pressed";
VAL_ 958 MO_QBit_Driver_Brakes 0 "Valid_Value" 1 "Substitute_Init_Or_ErrorValue";
VAL_ 958 MO_BLS 0 "No_Brakes" 1 "Brake_Pressed";
VAL_ 958 MO_Consistency_BrakePedal 0 "BrakePedalInformation_Plausible" 1 "BrakePedalInformation_Implausible";
VAL_ 958 MO_CommError_ESP 0 "No_Error" 1 "Error";
VAL_ 958 MO_Climate_Interv 0 "No Intervention" 1 "AcCompressor SwitchOff" 2 "AcCompressor Leistungsreduzierung" 3 "AcCompressor DueTo The HotWarningPreWarning SwitchOff";
VAL_ 958 MO_Aussp_Crank 0 "Starter_May_Actuated_Become" 1 "Starter_LeaveLane__Actuation_Not_Possible";
VAL_ 958 MO_Enable_Crank 0 "Start_Not_Permitted" 1 "StartEnable";
VAL_ 958 MO_Clutch_Switch 0 "Switch_sagt_Disengaged" 1 "Switch_sagt_eingekuppelt";
VAL_ 958 MO_Interlock 0 "InterlockSwitch_Not_Pressed" 1 "InterlockSwitch_Pressed";
VAL_ 958 MO_Engine_Running 0 "Engine_Running_Not" 1 "Engine_Running_autark_And_Stable_And_May_mechanisch_belastet_Become";
VAL_ 958 MO_Kickdown 0 "No_Kickdown" 1 "Kickdown";
VAL_ 958 MO_QBit_TERM_75 0 "Valid_Value" 1 "Substitute_Init_Or_ErrorValue";
VAL_ 958 MO_ETermCommLeiRed 0 "No_PowerLimit" 1 "PowerLimit_75" 2 "PowerLimit_50" 3 "PowerLimit_25";
VAL_ 958 MO_Handshake_STH 0 "No EKP-Actuation By STH-Request" 1 "EKP-Actuation By STH-Request";
VAL_ 958 MO_BKV_VacuumWarning 0 "VacuumSupply_iO" 1 "VacuumSupply_niO";
VAL_ 958 MO_Enable_Coasting 0 "CoastingMode_Not_Enabled" 1 "CoastingMode_Enabled";
VAL_ 958 MO_PTC_Status 0 "Not_Supported" 1 "Stage_0" 2 "Stage_1" 3 "Stage_2" 4 "Stage_3" 7 "PTC_At_BCM";
VAL_ 958 MO_QBit_GearPosition 0 "Valid_Value" 1 "Substitute_Init_Or_ErrorValue";
VAL_ 958 MO_SignalSource_GearPosition 0 "Sensorsignal" 1 "ModelSignal";
VAL_ 958 MO_Remotestart_Operation 0 "MSG_Not_Ready_For_RS_Operation" 1 "MSG_Ready_For_Or_In_RS_Operation";
VAL_ 958 MO_Remotestart_Possible 0 "Remotestart_Not_Possible" 1 "Remotestart_Possible";
VAL_ 958 MO_FMOff_Active 0 "Inactive" 1 "Coasting_With_Engine_Off_Active";
VAL_ 958 MO_FMOff_Startvariante 0 "No_EngineStart" 1 "EngineStart_elektrischer_Starter" 2 "GearboxAnschleppstart" 3 "GearboxNotAnschleppstart";
VAL_ 958 MO_BMS_NV_Req_stuetzen 0 "Not_Necessary" 1 "Necessary";
VAL_ 958 MO_CylinderDeactivation 0 "FullEngineOperation_VMB" 1 "OverGear_HMB_in_VMB" 2 "OverGear_VMB_in_HMB" 3 "Halbmotorbetrieb_HMB";
VAL_ 958 MO_HYB_VM_Active 0 "VM_Not_Active" 1 "VM_Active";
VAL_ 958 MO_StartVorauss_Met 0 "Signal_Not_bedient" 1 "StartVorauss_Not_ueberpruefbar" 2 "StartVorauss_Not_Met" 3 "StartVorauss_Met";
VAL_ 960 RSt_DriverNotices 0 "Init" 1 "DriverTakeover_Notice_ZAT_Automatic_Without_Chime" 2 "DriverTakeover_Notice_ZAT_Automatic_With_Chime" 3 "DriverTakeover_Notice_ZAT_ManualGearbox_Without_Chime" 4 "DriverTakeover_Notice_ZAT_ManualGearbox_With_Chime" 5 "DriverTakeover_Notice_ZAS_Automatic_Without_Chime" 6 "DriverTakeover_Notice_ZAS_Automatic_With_Chime" 7 "DriverTakeover_Notice_ZAS_ManualGearbox_Without_Chime" 8 "DriverTakeover_Notice_ZAS_ManualGearbox_With_Chime" 9 "RemoteStart_Active_Without_Chime" 10 "RemoteStart_Active_With_Chime" 11 "void" 12 "void" 13 "void" 14 "void" 15 "void";
VAL_ 960 ZAS_Term_S 0 "Off" 1 "S_Contact_On";
VAL_ 960 ZAS_Term_15 0 "Off" 1 "On";
VAL_ 960 ZAS_Term_X 0 "Off" 1 "On";
VAL_ 960 ZAS_Term_50_StartRequest 0 "Off" 1 "TERM50_On_Startwunsch_Driver";
VAL_ 960 BCM_Remotestart_Operation 0 "No_RS_Operation" 1 "RS_Operation";
VAL_ 960 ZAS_Term_Infotainment 0 "Inactive" 1 "Active";
VAL_ 960 BCM_Remotestart_TERM15_Req 0 "Inactive" 1 "Active";
VAL_ 960 BCM_Remotestart_MO_Start 0 "Not_Requested" 1 "Requested";
VAL_ 960 KST_Warn_P1_ZST_def 0 "Not_Defective" 1 "Defective";
VAL_ 960 KST_Warn_P2_ZST_def 0 "Not_Defective" 1 "Defective";
VAL_ 960 KST_DriverNotice_1 0 "Inactive" 1 "Active";
VAL_ 960 KST_DriverNotice_2 0 "Inactive" 1 "Active";
VAL_ 960 BCM_OffParking_Operation 0 "No_Operation" 1 "OffParkBeforeGear_Active";
VAL_ 960 KST_DriverNotice_4 0 "Inactive" 1 "Active";
VAL_ 960 KST_DriverNotice_5 0 "Inactive" 1 "Active";
VAL_ 960 KST_DriverNotice_6 0 "Inactive" 1 "Active";
VAL_ 967 MO_RadiatorFan_MUX 0 "RadiatorFan_1" 1 "RadiatorFan_2";
VAL_ 967 MO_RadiatorFan_1 126 "Init" 127 "Error";
VAL_ 967 MO_RadiatorFan_2 126 "Init" 127 "Error";
VAL_ 967 MO_EFLEX_Lamp 0 "Lamp_Off" 1 "Lamp_On" 2 "Lamp_Flashing" 3 "Lamp_Flashing_With_Acoustic";
VAL_ 967 MO_KJS_Not_Ready 0 "No_Error" 1 "Error";
VAL_ 967 MO_ITM_Warning_Pump 0 "No_Warning" 1 "ITM_Warning";
VAL_ 967 WIV_Display_Active 0 "Display Off" 1 "WIV Display Active";
VAL_ 967 WIV_Oelmin_Warn 0 "in_Order" 1 "Warning";
VAL_ 967 WIV_SensorError 0 "in_Order" 1 "Sensor_Defective";
VAL_ 967 WIV_Tilt 0 "Vehicle_Straight" 1 "Vehicle_in_Tilt";
VAL_ 967 MO_State_HWP 0 "HWP_Not_schaltbar" 1 "HWP_Delivers_Not" 2 "HWP_Delivers" 3 "Reserved";
VAL_ 967 OLEV_SystemMalfunction 0 "֬system i.O." 1 "SystemMalfunction ֬system";
VAL_ 967 MO_OilWarning_max 0 "No_Warning" 1 "Warnfall_Active";
VAL_ 967 WIV_OilSystem_Active 0 "Display_Off" 1 "Display_Active";
VAL_ 967 WIV_Not_AtOperatingTemp 0 "Engine_warm" 1 "Engine_Not_AtOperatingTemp";
VAL_ 967 WIV_Overfill_Warn 0 "in_Order" 1 "OverfillWarning";
VAL_ 967 WIV_Running_Engine 0 "Measurement_Possible" 1 "Measurement_Not_Possible";
VAL_ 967 MO_E_Warnings 0 "No_Display" 1 "Error_ElectricalSystem_Stop" 2 "Error_ElectricalSystem_Workshop" 3 "ElectricalSystem_Overheated_Stop" 4 "Error_Hybridsystem_Stop" 5 "Error_Hybridsystem_Workshop" 6 "Error_Wasserstoffsystem_Anhalte" 7 "Error_Wasserstoffsystem_Werksta" 8 "Reserved_No_Display" 9 "Reserved_No_Display" 10 "Reserved_No_Display" 11 "Reserved_No_Display" 12 "Reserved_No_Display" 13 "Reserved_No_Display" 14 "Reserved_No_Display" 15 "Reserved_No_Display";
VAL_ 967 MO_Text_EngineStart 0 "No_Display" 1 "Engine_In_StopOperation" 2 "StartStop_sicherheitsbedingt_Deactivated" 3 "System_fordert_Restart" 4 "Prompt_EngineStart" 5 "EngineRunning_Needed" 6 "EngineRunningWarning" 9 "Unerwuenschter_EngineStandstill" 10 "EngineStart_Not_Possible" 11 "Error_ClutchSwitch" 12 "Engine_Starting" 13 "Clutch_Press" 14 "SelectorLever_in_PN_Position" 15 "Brake_Press";
VAL_ 967 MO_E_Texte 0 "No_Display" 1 "Battery_fast_Empty" 2 "ChargePlug_Not_DriveReady" 3 "VM_Operation_Required" 4 "Battery_laedt_Not_SwitchOff" 5 "Please_Brake_Press" 6 "Manual_Restart_Required" 7 "Stop_Vehicle_Not_abschleppen" 8 "No_Restart_Haube_Not_Open" 9 "EngineStart_In_naechsten_Cycle" 10 "VM_Required_EVMode_abwaehlen" 11 "laengerer_VMOperation_Bordbuch" 12 "Tank_Empty_VM_Not_Available" 13 "Please_warten_Engine_Starting" 14 "No_Start_BatteryTemperature" 15 "End_elektrische_Range_Reached";
VAL_ 967 WIV_OilDyn_avl 0 "OilDyn_Not_Present" 1 "OilDyn_Present";
VAL_ 967 OLEV_OilLevel_Not_Present 0 "֬Level Present" 1 "֬Level Not Present";
VAL_ 967 MO_SystemLamp 0 "Lamp Off" 1 "Lamp On";
VAL_ 967 MO_OBD2_Lamp 0 "Lamp Off" 1 "Lamp On";
VAL_ 967 MO_HotWarningLamp 0 "Lamp Off" 1 "Lamp On";
VAL_ 967 MO_Particle_Lamp 0 "Lamp Off" 1 "Lamp On";
VAL_ 967 MO_RedDrivePower_Lamp 0 "Lamp_Off" 1 "Lamp_On";
VAL_ 967 WIV_OilLevel_Not_Present 0 "֬Level Present" 1 "֬Level Not Present";
VAL_ 967 WIV_RefillDisplay_On 0 "No_RefillDisplay" 1 "RefillDisplay";
VAL_ 967 WIV_Overfill_Deactivated 0 "OverfillWarning_At_Cluster_Active" 1 "OverfillWarning_At_Cluster_Deactivated";
VAL_ 967 WIV_Underfill_Warn 0 "in_Order" 1 "UnderfillWarning";
VAL_ 967 MO_FuelCap_Lamp 0 "Lamp Off" 1 "Lamp On";
VAL_ 967 MO_Text_FuelCapWarn 0 "No_Text" 1 "Display_Text_FuelCapWarning_In_Cluster";
VAL_ 967 MO_Preheat_Lamp 0 "Lamp_Off" 1 "Lamp_On";
VAL_ 967 WIV_OilPressure_Warn_Engine 0 "No_Warning" 1 "Low_OilPressureStage_Not_Reached";
VAL_ 967 MO_E_Mode 0 "No_Display" 1 "E_Mode_Passive" 2 "E_Mode_Active" 3 "E_Mode_Inactive_Not_Available" 4 "E_Mode_Active_Not_Available" 5 "Reserved_No_Display" 6 "Reserved_No_Display" 7 "Reserved_No_Display";
VAL_ 974 HFS_Door_Opened 0 "Closed" 1 "Open";
VAL_ 974 HFS_Locked 0 "Not_Locked" 1 "Locked";
VAL_ 974 HFS_Safed 0 "Not_Safed" 1 "Safed";
VAL_ 974 HFS_RearBlindButton_Pressed 0 "No_Verfahranweisung_in_Direction_High" 1 "In_Direction_High_Procedure";
VAL_ 974 HFS_DoorLock_Defective 0 "DoorLock_Functional" 1 "DoorLock_Defective";
VAL_ 974 HFS_Unlock_PushButton 0 "Not_Pressed" 1 "Pressed";
VAL_ 974 HFS_Lock_PushButton 0 "Not_Pressed" 1 "Pressed";
VAL_ 974 HFS_ParkPawl 0 "Lock_in_PreDetent_And_MainDetent" 1 "Door_Open_Or_Door_Position_Between_Before_And_MainDetent";
VAL_ 974 HFS_TAG_Pressed 0 "Not_Pressed" 1 "Pressed";
VAL_ 974 HFS_TIG_Pressed 0 "Not_Pressed" 1 "Pressed";
VAL_ 974 HFS_FH_S_HBFS_AutoHigh 0 "No_Operation" 1 "AutoRun_Requested";
VAL_ 974 HFS_FH_S_HBFS_AutoLow 0 "No_Operation" 1 "AutoRun_Requested";
VAL_ 974 HFS_FH_S_HBFS_ManHigh 0 "No_Operation" 1 "Manual_Run_Requested";
VAL_ 974 HFS_FH_S_HBFS_ManLow 0 "No_Operation" 1 "Manual_Run_Requested";
VAL_ 974 HFS_Door_Status 0 "Init" 1 "Door_Closed" 2 "Door_Open" 3 "Error";
VAL_ 974 HFS_SAD_Switch 0 "Not_Pressed" 5 "OPEN_Manual" 6 "OPEN_Automatic" 7 "Closed_Manual" 8 "Closed_Automatic" 13 "Not_Available" 14 "Init" 15 "Error";
VAL_ 974 HFS_FH_S_ManHigh 0 "Not_Pressed" 1 "Pressed";
VAL_ 974 HFS_FH_S_AutoHigh 0 "Not_Pressed" 1 "Pressed";
VAL_ 974 HFS_FH_S_ManLow 0 "Not_Pressed" 1 "Pressed";
VAL_ 974 HFS_FH_S_AutoLow 0 "Not_Pressed" 1 "Pressed";
VAL_ 974 HFS_FH_Bew_High 0 "Inactive" 1 "Active";
VAL_ 974 HFS_FH_Bew_Low 0 "Inactive" 1 "Active";
VAL_ 974 HFS_FH_Fang 0 "Outside_CaptureRange" 1 "Within_CaptureRange";
VAL_ 974 HFS_FH_Block 0 "Inactive" 1 "Active";
VAL_ 974 HFS_FH_Thermo 0 "Inactive" 1 "Active";
VAL_ 974 HFS_UEKB_Activated 0 "Inactive" 1 "Active";
VAL_ 974 HFS_DoorOpen_Warning 0 "DoorWarning_Not_Active" 1 "DoorWarning_Active";
VAL_ 974 HFS_FH_Normalised 0 "Inactive" 1 "Active";
VAL_ 974 ASW_Warning_Active_HFS 0 "Not_Requested" 1 "Requested";
VAL_ 974 HFS_SoftClose_Active 0 "Init" 1 "SoftClose_Active";
VAL_ 974 HFS_SideBlind_High 1 "SideBlind_in_Movement_High";
VAL_ 974 HFS_SideBlind_Low 1 "SideBlind_in_Movement_Low";
VAL_ 974 HFS_Status_ChildSeat 0 "Inactive" 1 "Active";
VAL_ 974 SSR_HFS_Pos_Bottom 0 "SSR_Top" 1 "SSR_Bottom";
VAL_ 974 HFS_Top_Block_Ext 0 "WindowLifter_Not_in_Blockerwar" 1 "WindowLifter_in_BlockageExpected_o";
VAL_ 974 HFS_Bottom_Block_Ext 0 "WindowLifter_Not_in_Blockerwar" 1 "WindowLifter_in_BlockageExpected_u";
VAL_ 974 MTHFS_M_Key 0 "Not_Pressed" 1 "Pressed";
VAL_ 974 MTHFS_Pos1 0 "Not_Pressed" 1 "Pressed";
VAL_ 974 MTHFS_Pos2 0 "Not_Pressed" 1 "Pressed";
VAL_ 974 MTHFS_Pos3 0 "Not_Pressed" 1 "Pressed";
VAL_ 974 HFS_MBlind_Switch 0 "Not_Pressed" 1 "Closed_Manual" 2 "Closed_Automatic" 3 "OPEN_Manual" 4 "OPEN_Automatic" 5 "Not_Available" 6 "Init" 7 "Error";
VAL_ 974 HFS_Lock_PushButton_inv 0 "Lock PushButton bet䴧it" 1 "Lock PushButton Not bet䴩gt";
VAL_ 974 HFS_Status_eTAG 0 "Init" 1 "Handle_Extended" 2 "Handle_Retracted" 3 "Error";
VAL_ 974 HFS_Door_Status_QBit 0 "Status_DoorContact_Safe" 1 "Status_DoorContact_Uncertain";
VAL_ 974 HFS_TCR_Mode_Active 0 "TCR_Mode_Deactivated" 1 "TCR_Mode_Active";
VAL_ 975 HBFS_Door_Opened 0 "Closed" 1 "Open";
VAL_ 975 HBFS_Locked 0 "Not_Locked" 1 "Locked";
VAL_ 975 HBFS_Safed 0 "Not_Safed" 1 "Safed";
VAL_ 975 HBFS_RearBlindButton_Pressed 0 "No_Verfahranweisung_in_Direction_High" 1 "In_Direction_High_Procedure";
VAL_ 975 HBFS_DoorLock_Defective 0 "DoorLock_Functional" 1 "DoorLock_Defective";
VAL_ 975 HBFS_Unlock_PushButton 0 "Not_Pressed" 1 "Pressed";
VAL_ 975 HBFS_Lock_PushButton 0 "Not_Pressed" 1 "Pressed";
VAL_ 975 HBFS_ParkPawl 0 "Lock_in_PreDetent_And_MainDetent" 1 "Door_Open_Or_Door_Position_Between_Before_And_MainDetent";
VAL_ 975 HBFS_TAG_Pressed 0 "Not_Pressed" 1 "Pressed";
VAL_ 975 HBFS_TIG_Pressed 0 "Not_Pressed" 1 "Pressed";
VAL_ 975 HBFS_FH_S_HFS_AutoHigh 0 "No_Operation" 1 "AutoRun_Requested";
VAL_ 975 HBFS_FH_S_HFS_AutoLow 0 "No_Operation" 1 "AutoRun_Requested";
VAL_ 975 HBFS_FH_S_HFS_ManHigh 0 "No_Operation" 1 "Manual_Run_Requested";
VAL_ 975 HBFS_FH_S_HFS_ManLow 0 "No_Operation" 1 "Manual_Run_Requested";
VAL_ 975 HBFS_Door_Status 0 "Init" 1 "Door_Closed" 2 "Door_Open" 3 "Error";
VAL_ 975 HBFS_SAD_Switch 0 "Not_Pressed" 5 "OPEN_Manual" 6 "OPEN_Automatic" 7 "Closed_Manual" 8 "Closed_Automatic" 13 "Not_Available" 14 "Init" 15 "Error";
VAL_ 975 HBFS_FH_S_ManHigh 0 "Not_Pressed" 1 "Pressed";
VAL_ 975 HBFS_FH_S_AutoHigh 0 "Not_Pressed" 1 "Pressed";
VAL_ 975 HBFS_FH_S_ManLow 0 "Not_Pressed" 1 "Pressed";
VAL_ 975 HBFS_FH_S_AutoLow 0 "Not_Pressed" 1 "Pressed";
VAL_ 975 HBFS_FH_Bew_High 0 "Inactive" 1 "Active";
VAL_ 975 HBFS_FH_Bew_Low 0 "Inactive" 1 "Active";
VAL_ 975 HBFS_FH_Fang 0 "Outside_CaptureRange" 1 "Within_CaptureRange";
VAL_ 975 HBFS_FH_Block 0 "Inactive" 1 "Active";
VAL_ 975 HBFS_FH_Thermo 0 "Inactive" 1 "Active";
VAL_ 975 HBFS_UEKB_Activated 0 "Inactive" 1 "Active";
VAL_ 975 HBFS_DoorOpen_Warning 0 "DoorWarning_Not_Active" 1 "DoorWarning_Active";
VAL_ 975 HBFS_FH_Normalised 0 "Inactive" 1 "Active";
VAL_ 975 ASW_Warning_Active_HBFS 0 "Not_Requested" 1 "Requested";
VAL_ 975 HBFS_SoftClose_Active 0 "Init" 1 "SoftClose_Active";
VAL_ 975 HBFS_SideBlind_High 1 "SideBlind_in_Movement_High";
VAL_ 975 HBFS_SideBlind_Low 1 "SideBlind_in_Movement_Low";
VAL_ 975 HBFS_Status_ChildSeat 0 "Inactive" 1 "Active";
VAL_ 975 SSR_HBFS_Pos_Bottom 0 "SSR_Top" 1 "SSR_Bottom";
VAL_ 975 HBFS_Top_Block_Ext 0 "WindowLifter_Not_in_Blockerwar" 1 "WindowLifter_in_BlockageExpected_o";
VAL_ 975 HBFS_Bottom_Block_Ext 0 "WindowLifter_Not_in_Blockerwar" 1 "WindowLifter_in_BlockageExpected_u";
VAL_ 975 MTHBFS_M_Key 0 "Not_Pressed" 1 "Pressed";
VAL_ 975 MTHBFS_Pos1 0 "Not_Pressed" 1 "Pressed";
VAL_ 975 MTHBFS_Pos2 0 "Not_Pressed" 1 "Pressed";
VAL_ 975 MTHBFS_Pos3 0 "Not_Pressed" 1 "Pressed";
VAL_ 975 HBFS_MBlind_Switch 0 "Not_Pressed" 1 "Closed_Manual" 2 "Closed_Automatic" 3 "OPEN_Manual" 4 "OPEN_Automatic" 5 "Not_Available" 6 "Init" 7 "Error";
VAL_ 975 HBFS_Lock_PushButton_inv 0 "Lock PushButton bet䴧it" 1 "Lock PushButton Not bet䴩gt";
VAL_ 975 HBFS_Status_ChildSeat_inv 0 "Active" 1 "Inactive";
VAL_ 975 HBFS_Status_eTAG 0 "Init" 1 "Handle_Extended" 2 "Handle_Retracted" 3 "Error";
VAL_ 975 HBFS_Door_Status_QBit 0 "Status_DoorContact_Safe" 1 "Status_DoorContact_Uncertain";
VAL_ 975 HBFS_TIG_Pressed_Close 0 "Not_Pressed" 1 "Pressed";
VAL_ 976 FT_Door_Opened 0 "Init" 1 "Door Open";
VAL_ 976 FT_Locked 0 "Init" 1 "Locked";
VAL_ 976 FT_Safed 0 "Init" 1 "Safed";
VAL_ 976 FT_KeySwitch_Open 0 "Init" 1 "KeySwitch_Open_Pressed";
VAL_ 976 FT_KeySwitch_Closed 1 "KeySwitch Closed Pressed";
VAL_ 976 FT_Unlock_PushButton 0 "Init" 1 "Unlock_PushButton_Pressed";
VAL_ 976 FT_Lock_PushButton 0 "Init" 1 "Lock_PushButton_Pressed";
VAL_ 976 FT_ParkPawl 0 "Lock_in_PreDetent_And_MainDetent" 1 "Door_Open_Or_Door_Position_Between_Before_And_MainDetent";
VAL_ 976 FT_TAG_Pressed 0 "Not_Pressed" 1 "Pressed";
VAL_ 976 FT_TIG_Pressed 0 "Not_Pressed" 1 "Pressed";
VAL_ 976 FT_IRUE_Key 0 "Init" 1 "IRUE_Key_Pressed";
VAL_ 976 FT_HD_Key 0 "Init" 1 "Tailgate_Open";
VAL_ 976 FT_TD_Key_Error 0 "iO" 1 "Defective";
VAL_ 976 FT_TD_Key 1 "Tankdeckelentriegelungs PushButton Pressed";
VAL_ 976 SSR_Temp_Enable 0 "SSR_Deactivated" 1 "SSR_Enabled";
VAL_ 976 FT_HD_Key_2 0 "Key_Not_Pressed" 1 "Key_Pressed";
VAL_ 976 FT_DoorECU_Rear_Fitted 0 "Not Fitted" 1 "Fitted";
VAL_ 976 FT_Sp_Blk_def 0 "iO" 1 "Defective";
VAL_ 976 FT_FH_S_ManHigh 0 "Init" 1 "FH_Switch_man_High_Pressed";
VAL_ 976 FT_FH_S_AutoHigh 0 "Init" 1 "FH_Switch_auto_High_Pressed";
VAL_ 976 FT_FH_S_ManLow 0 "Init" 1 "FH_Switch_man_Low_Pressed";
VAL_ 976 FT_FH_S_AutoLow 0 "Init" 1 "FH_Switch_auto_Low_Pressed";
VAL_ 976 FT_FH_Bew_High 0 "Init" 1 "FH_in_Movement_High";
VAL_ 976 FT_FH_Bew_Low 0 "Init" 1 "FH_in_Movement_Low";
VAL_ 976 FT_FH_Fang 0 "Outside_CaptureRange" 1 "Within_CaptureRange";
VAL_ 976 FT_FH_Block 0 "Init" 1 "Window_Block";
VAL_ 976 FT_FH_Thermo 0 "Init" 1 "Thermoschutz_Active";
VAL_ 976 FT_UEKB_Activated 0 "Init" 1 "UEKB_Active";
VAL_ 976 ASW_HMI_Defective 0 "iO" 1 "Defective";
VAL_ 976 FT_FH_Normalised 0 "Init" 1 "Window_Normalised";
VAL_ 976 FT_CloseButton 1 "CloseButton_Pressed";
VAL_ 976 FT_SoftClose_Active 0 "Init" 1 "Zuziehilfe_Active";
VAL_ 976 FT_SP_Disengaged 0 "Init" 1 "Mirror_Disengaged";
VAL_ 976 FT_SP_lr_Active 0 "Init" 1 "Mirror_xAchse_Active";
VAL_ 976 FT_SP_ht_Active 0 "Init" 1 "Mirror_yAchse_Active";
VAL_ 976 ASW_wakeup 0 "Sleep" 1 "Wakeup";
VAL_ 976 FT_Top_Block_Ext 0 "WindowLifter_Not_in_Blockerwar" 1 "WindowLifter_in_BlockageExpected_o";
VAL_ 976 FT_Bottom_Block_Ext 0 "WindowLifter_Not_in_Blockerwar" 1 "WindowLifter_in_BlockageExpected_u";
VAL_ 976 FT_ChildSeat_Left_Active 0 "Inactive" 1 "Active";
VAL_ 976 FT_ChildSeat_Right_Active 0 "Inactive" 1 "Active";
VAL_ 976 FT_ChildSeat_PushButton_Left 0 "Not_Pressed" 1 "Pressed";
VAL_ 976 FT_ChildSeat_PushButton_Right 0 "Not_Pressed" 1 "Pressed";
VAL_ 976 FT_BFS_Fond_Enable 0 "Init" 1 "Enable_For_Fondbedienung_BFS";
VAL_ 976 FT_ChildSeat_Error 0 "No_Error" 1 "Error";
VAL_ 976 FT_Daemmglas 0 "Normalglas_Fitted" 1 "Daemmglas_Fitted";
VAL_ 976 FT_SP_Heating_Status 0 "Init" 1 "Status_MirrorHeating_On";
VAL_ 976 ASW_Warning_Active_FS 0 "Not_Requested" 1 "Requested";
VAL_ 976 FT_FH_Pos_Top 1 "Window Top (After Absenken Open Position)";
VAL_ 976 FT_DoorLock_Defective 0 "DoorLock_Functional" 1 "DoorLock_Defective";
VAL_ 976 FT_SWA_PushButton 0 "PushButton_Not_Pressed" 1 "PushButton_Pressed";
VAL_ 976 SWA_HMI_Diagnostics 0 "No_Error_Detected" 1 "Error_PushButton_Detected" 2 "Error_LED_Detected" 3 "Error_LED_And_PushButton_Detected";
VAL_ 976 FS_Status_eTAG 0 "Init" 1 "Handle_Extended" 2 "Handle_Retracted" 3 "Error";
VAL_ 980 BH_Indicator_Left 0 "Not_Pressed" 1 "IndicatorLever_Pos_Left_Pressed";
VAL_ 980 BH_Indicator_Right 0 "Not_Pressed" 1 "IndicatorLever_Pos_Right_Pressed";
VAL_ 980 BH_HeadlightFlash 0 "Not_Pressed" 1 "IndicatorLever in Direction HeadlightFlash Pressed";
VAL_ 980 BH_HighBeam 0 "Not_Pressed" 1 "IndicatorLever_in_Direction_HighBeam_Pressed";
VAL_ 980 WH_TipWipe 0 "Not_Pressed" 1 "Pressed";
VAL_ 980 WH_Intervall 0 "Off" 1 "WiperLever in Position Intervall";
VAL_ 980 WH_WiperStage1 0 "Off" 1 "WiperLever in Stage Wipe 1";
VAL_ 980 WH_WiperStage2 0 "Off" 1 "WiperLever in Stage Wipe 2";
VAL_ 980 WH_FrontWash 0 "Off" 1 "WiperLever in Position Wisch Wasch Front";
VAL_ 980 WH_Heckintervall 0 "Not_Pressed" 1 "WiperLever in Position Heckintervall";
VAL_ 980 WH_RearWash 0 "Not_Pressed" 1 "WiperLever in Position Wisch Wasch Rear";
VAL_ 980 WH_Intervallstufen 0 "Init / Default" 1 "IntervalStage 1" 5 "IntervalStage 2" 9 "IntervalStage 3" 13 "IntervalStage 4" 15 "Error";
VAL_ 980 FAS_PushButton 0 "Not_Pressed" 1 "Pressed";
VAL_ 980 FAS_PushButton_Error 0 "No_Error" 1 "Error";
VAL_ 980 SMLS_Horn 0 "Not_Pressed" 1 "Horn_Pressed";
VAL_ 980 LRH_On_Off 0 "LRH_Off__No Display" 1 "LRH_Off" 2 "LRH_On" 3 "Error";
VAL_ 980 LRH_Active 0 "Inactive" 1 "Active";
VAL_ 980 SMLS_P_Locked_Plausible 0 "Implausible" 1 "Plausible";
VAL_ 980 WH_SRA 0 "SRA_Off" 1 "SRA_On";
VAL_ 980 WH_Wiper_Error 0 "No_Error" 1 "Error";
VAL_ 980 BH_Indicator_Error 0 "No_Error" 1 "Error";
VAL_ 980 SMLS_PTT 0 "Not_Pressed" 1 "PTT_Pressed";
VAL_ 980 WH_TipWipe_Long 0 "Not_Pressed" 1 "Pressed";
VAL_ 981 BCM1_CorneringLight_Left_Req 0 "linkes_CorneringLight/TurnLight_By_BCM1_Not_Actuated" 1 "linkes_Kurven/TurnLight_By_BCM1_Actuated";
VAL_ 981 BCM1_CorneringLight_Right_Req 0 "rechtes_CorneringLight/TurnLight_By_BCM1_Not_Actuated" 1 "rechtes_CorneringLight/TurnLight_By_BCM1_Actuated";
VAL_ 981 BCM1_SideLight_Req 0 "Light_Not_Requested" 1 "Light Actual ToSwitchOn";
VAL_ 981 BCM1_LowBeam_Req 0 "Light_Not_Requested" 1 "Light Actual ToSwitchOn";
VAL_ 981 BCM1_HighBeam_Req 0 "Light_Not_Requested" 1 "Light Actual ToSwitchOn";
VAL_ 981 BCM1_FogLight_Req 0 "Light_Not_Requested" 1 "Light Actual ToSwitchOn";
VAL_ 981 BCM1_ParkingLight_Left_Req 0 "Light_Not_Requested" 1 "Light Actual ToSwitchOn";
VAL_ 981 BCM1_ParkingLight_Right_Req 0 "Light_Not_Requested" 1 "Light Actual ToSwitchOn";
VAL_ 981 BCM1_RearFog_Ahg_Req 0 "Light_Not_Requested" 1 "Light Actual ToSwitchOn";
VAL_ 981 BCM1_RearFog_Veh_Req 0 "Light_Not_Requested" 1 "Light Actual ToSwitchOn";
VAL_ 981 BCM1_TailLight_Req 0 "Light_Not_Requested" 1 "Light Actual ToSwitchOn";
VAL_ 981 BCM_ReversingLight_Req 0 "Light_Not_Requested" 1 "Light_Requested";
VAL_ 981 BCM1_SignatureLight_Req 0 "Light_Not_Requested" 1 "Light_Actual_ToSwitchOn";
VAL_ 981 BCM1_Umfeldleuchten_Req 0 "Light_Not_Requested" 1 "Light_Actual_ToSwitchOn";
VAL_ 981 BCM1_DaytimeRunningLight_Req 0 "Light_Not_Requested" 1 "Light Actual ToSwitchOn";
VAL_ 981 BCM1_RainLight_Req 0 "Light_Not_Requested" 1 "Light Actual ToSwitchOn";
VAL_ 981 BCM1_MotorwayLight_Req 0 "Light_Not_Requested" 1 "Light Actual ToSwitchOn";
VAL_ 981 BCM1_Tourist_Light_Req 0 "Light_Not_Requested" 1 "Request From TouristLight";
VAL_ 981 BCM1_CH_Active 0 "Inactive" 1 "Active";
VAL_ 981 BCM1_LH_Active 0 "Inactive" 1 "Active";
VAL_ 981 BCM1_Sliding_Leuchtw_Req 0 "Off" 1 "On";
VAL_ 981 BCM1_GLW_HighBeam_Req 0 "Off" 1 "On";
VAL_ 981 BCM1_Adaptive_LightDistribution_Req 0 "Off" 1 "On";
VAL_ 981 BCM1_FoD_Blocking_WiBli 0 "Enable_WiBli" 1 "Blocking_WiBli" 2 "Init";
VAL_ 981 BCM1_FOD_Blocking_Animations_HL 0 "Enable_Animations" 1 "Blocking_Animations" 2 "Init";
VAL_ 981 BCM1_Animationssperrung 0 "No_Blocking" 1 "Blocking";
VAL_ 981 BCM1_CH_LH_Active 0 "Comming_Home_Bzw._Leaving_Home_Not_Active" 1 "Comming Home bzw. Leaving Home Active";
VAL_ 981 BCM1_AllWeatherLight_Req 0 "Light_Not_Requested" 1 "Light_Actual_ToSwitchOn";
VAL_ 981 BCM1_TailLight_Signature 0 "No_Signature" 1 "Signature_1" 2 "Signature_2" 3 "Signature_3" 4 "Signature_4" 5 "Signature_5" 6 "Signature_6" 7 "Signature_7" 8 "Signature_8" 9 "Signature_9" 10 "Signature_10" 11 "Signature_11" 12 "Signature_12" 13 "Signature_13" 14 "Signature_14" 15 "Signature_15";
VAL_ 982 BCM2_BrakeLight_By_ECD 0 "BrakeLight_Actual_Off" 1 "BrakeLight_By_ECD_Active";
VAL_ 982 LH_OutsideLight_def 0 "OK" 1 "Defective";
VAL_ 982 LH_SideLight_H_Active 1 "SideLight Rear Active";
VAL_ 982 LH_ParkingLight_HL_Active 0 "Not Active" 1 "ParkingLight Rear Left Active";
VAL_ 982 LH_ParkingLight_HR_Active 0 "Not Active" 1 "ParkingLight Rear Right Active";
VAL_ 982 LH_BrakeLight_H_Active 1 "BrakeLight Rear Active";
VAL_ 982 LH_RearFog_Active 0 "Not Active" 1 "Active";
VAL_ 982 LH_ReversingLight_Active 0 "Not Active" 1 "Active";
VAL_ 982 LH_Indicator_HL_Act 1 "Indicator Rear Left Active";
VAL_ 982 LH_Indicator_HR_Act 1 "Indicator Rear Right Active";
VAL_ 982 LH_Indicator_Left_def 0 "OK" 1 "Indicator Rear Left Defective";
VAL_ 982 LH_BrakeLight_Left_def 0 "OK" 1 "AtLeast On BrakeLight Rear Left Defective";
VAL_ 982 LH_TailLight_Left_def 0 "OK" 1 "AtLeast On TailLight Rear Left Defective";
VAL_ 982 LH_Reverse_Left_def 0 "OK" 1 "ReversingLight Rear Left Defective";
VAL_ 982 LH_Fog_Left_def 0 "OK" 1 "RearFogLight Rear Left Defective";
VAL_ 982 LH_End_Brake_Fog_Left_def 0 "iO" 1 "Defective";
VAL_ 982 LH_End_Brake_Fog_Right_def 0 "iO" 1 "Defective";
VAL_ 982 LH_Zusatzschlussl_def 0 "OK" 1 "AtLeast_On_AdditionalTailLight_Defective";
VAL_ 982 LH_End_Brake_Left_def 0 "OK" 1 "Defective";
VAL_ 982 LH_End_Fog_Left_def 0 "OK" 1 "Defective";
VAL_ 982 LH_SL_BRL_BLK_Left_def 0 "OK" 1 "Defective";
VAL_ 982 LH_Brake_Blk_Left_def 0 "OK" 1 "Defective";
VAL_ 982 LH_Diag_Status_Right_def 0 "OK" 1 "Aussenlict_Diagnostics_SystemMalfunction_Right";
VAL_ 982 LH_Diag_Status_Left_def 0 "OK" 1 "OutsideLight_Diagnostics_SystemMalfunction_Left";
VAL_ 982 LH_Diag_LED_Left_def 0 "OK" 1 "RearLamp_Left_Defective";
VAL_ 982 LH_Diag_LED_Right_def 0 "OK" 1 "RearLamp_Right_Defective";
VAL_ 982 LH_Indicator_Right_def 0 "OK" 1 "Indicator Rear Right Defective";
VAL_ 982 LH_BrakeLight_Right_def 0 "OK" 1 "AtLeast On BrakeLight Rear Right Defective";
VAL_ 982 LH_TailLight_Right_def 0 "OK" 1 "AtLeast On TailLight Rear Right Defective";
VAL_ 982 LH_Reverse_Right_def 0 "OK" 1 "ReversingLight Rear Right Defective";
VAL_ 982 LH_Fog_Right_def 0 "OK" 1 "RearFogLight Rear Right Defective";
VAL_ 982 LH_End_Brake_mi_def 0 "OK" 1 "Defective";
VAL_ 982 LH_End_Brake_Right_def 0 "OK" 1 "Defective";
VAL_ 982 LH_End_Fog_Right_def 0 "OK" 1 "Defective";
VAL_ 982 LH_SL_BRL_BLK_Right_def 0 "OK" 1 "Defective";
VAL_ 982 LH_Brake_Blk_Right_def 0 "OK" 1 "Defective";
VAL_ 982 LH_Kennzl_def 0 "OK" 1 "Kennzeichenbeleuchtung Rear Defective";
VAL_ 982 LH_3_BrakeLight_def 0 "OK" 1 "HighSet  BrakeLight Defective";
VAL_ 982 LH_Fog_mi_def 0 "OK" 1 "RearFogLight Rear Centre Defective";
VAL_ 982 LH_Reverse_mi_def 0 "OK" 1 "Rckfahllicht Centre Defective";
VAL_ 982 LH_TailLight_mi_def 0 "OK" 1 "Defective";
VAL_ 982 LH_BrakeLight_mi_def 0 "OK" 1 "Defective";
VAL_ 982 LH_BrakeLight_Left_Total_def 0 "OK" 1 "All BrakeLights Rear Left Defective";
VAL_ 982 LH_BrakeLight_Right_Total_def 0 "OK" 1 "All BrakeLights Rear Right Defective";
VAL_ 258 Motion_State 1 "Forwards" 2 "Reversing" 3 "Stopped";
VAL_ 258 EPB_Status 0 "Open" 1 "Closed_Parking" 2 "PartlyTensioned_Hold" 3 "In_Run_Open" 4 "In_Run_Close" 5 "tbd" 6 "Init" 7 "Unknown";
VAL_ 219 AWV_Unavailable 0 "Available" 1 "Unavailable";

CM_ "vw_meb_2024.dbc starts here";
CM_ SG_ 64 FROM_RGS_Anst "[DE: AB_RGS_Anst]";
CM_ SG_ 64 FROM_Front_Crash "[DE: AB_Front_Crash]";
CM_ SG_ 64 FROM_Rear_Crash "[DE: AB_Heck_Crash]";
CM_ SG_ 64 FROM_SF_Crash "[DE: AB_SF_Crash]";
CM_ SG_ 64 FROM_SB_Crash "[DE: AB_SB_Crash]";
CM_ SG_ 64 FROM_Rollover_Crash "[DE: AB_Rollover_Crash]";
CM_ SG_ 64 FROM_Crash_Int "[DE: AB_Crash_Int]";
CM_ SG_ 64 FROM_Lamp "[DE: AB_Lampe]";
CM_ SG_ 64 FROM_Deactivated "[DE: AB_Deaktiviert]";
CM_ SG_ 64 FROM_VB_Deactivated "[DE: AB_VB_deaktiviert]";
CM_ SG_ 64 FROM_SystemError "[DE: AB_Systemfehler]";
CM_ SG_ 64 FROM_Diagnostics "[DE: AB_Diagnose]";
CM_ SG_ 64 FROM_ActuatorTest "[DE: AB_Stellgliedtest]";
CM_ SG_ 64 FROM_Erh_Open_VB "[DE: AB_Erh_Auf_VB]";
CM_ SG_ 64 FROM_BeltWarn_VF "[DE: AB_Gurtwarn_VF]";
CM_ SG_ 64 FROM_BeltWarn_VB "[DE: AB_Gurtwarn_VB]";
CM_ SG_ 64 FROM_Display_Pedestrian "[DE: AB_Anzeige_Fussg]";
CM_ SG_ 64 FROM_Texte_AKS "[DE: AB_Texte_AKS]";
CM_ SG_ 64 FROM_MKB_Valid "[DE: AB_MKB_gueltig]";
CM_ SG_ 64 FROM_MKB_Request "[DE: AB_MKB_Anforderung]";
CM_ SG_ 64 FROM_SupplyVoltage "[DE: AB_Versorgungsspannung]";
CM_ SG_ 64 FROM_Deactivation_HV "[DE: AB_Deaktivierung_HV]";
CM_ SG_ 64 FROM_EDR_Trigger "[DE: AB_EDR_Trigger]";
CM_ SG_ 64 FROM_Occupancy_VF "[DE: AB_Belegung_VF]";
CM_ SG_ 64 SC_MasterTime_Offset "[DE: SC_Masterzeit_Offset]";
CM_ SG_ 64 SC_LowSpeedCrashDetected "[DE: SC_LowSpeedCrashErkannt]";
CM_ SG_ 64 SC_MasterTime "[DE: SC_Masterzeit]";
CM_ SG_ 134 LWI_QBit_Sub_Data "[DE: LWI_QBit_Sub_Daten]";
CM_ SG_ 134 LWI_MFL_Shutdown "[DE: LWI_MFL_Abschaltung]";
CM_ SG_ 134 LWI_QBit_SteeringWheelAngle "[DE: LWI_QBit_Lenkradwinkel]";
CM_ SG_ 134 LWI_SteeringWheelAngle "[DE: LWI_Lenkradwinkel]";
CM_ SG_ 134 LWI_VZ_SteeringWheelAngle "[DE: LWI_VZ_Lenkradwinkel]";
CM_ SG_ 134 LWI_VZ_SteeringWheelAngle_Speed "[DE: LWI_VZ_Lenkradw_Geschw]";
CM_ SG_ 134 LWI_SteeringWheelAngle_Speed "[DE: LWI_Lenkradw_Geschw]";
CM_ SG_ 134 LWI_Sub_Data "[DE: LWI_Sub_Daten]";
CM_ SG_ 159 EPS_Calculated_LW "[DE: EPS_Berechneter_LW]";
CM_ SG_ 159 EPS_SteeringTorque "[DE: EPS_Lenkmoment]";
CM_ SG_ 159 EPS_SteeringTorque_QBit "[DE: EPS_Lenkmoment_QBit]";
CM_ SG_ 159 EPS_VZ_SteeringTorque "[DE: EPS_VZ_Lenkmoment]";
CM_ SG_ 159 EPS_SteeringType "[DE: EPS_Lenkungstyp]";
CM_ SG_ 167 Engine_11_CRC "[DE: Motor_11_CRC]";
CM_ SG_ 167 Engine_11_BZ "[DE: Motor_11_BZ]";
CM_ SG_ 167 MO_Torque_Target_Raw "[DE: MO_Mom_Soll_Roh]";
CM_ SG_ 167 MO_Torque_Actual_Sum "[DE: MO_Mom_Ist_Summe]";
CM_ SG_ 167 MO_Torque_Inertia_Sum "[DE: MO_Mom_Traegheit_Summe]";
CM_ SG_ 167 MO_Torque_Target_Filtered "[DE: MO_Mom_Soll_gefiltert]";
CM_ SG_ 167 MO_Torque_Overrun "[DE: MO_Mom_Schub]";
CM_ SG_ 167 MO_Status_NormalOperation_01 "[DE: MO_Status_Normalbetrieb_01]";
CM_ SG_ 167 MO_First_InaccurateThreshold "[DE: MO_erste_Ungenauschwelle]";
CM_ SG_ 167 MO_QBit_EngineTorques "[DE: MO_QBit_Motormomente]";
CM_ SG_ 168 Engine_12_CRC "[DE: Motor_12_CRC]";
CM_ SG_ 168 Engine_12_BZ "[DE: Motor_12_BZ]";
CM_ SG_ 168 MO_Torque_Neg_Available "[DE: MO_Mom_neg_verfuegbar]";
CM_ SG_ 168 MO_Torque_Limit_Status "[DE: MO_Mom_Begr_stat]";
CM_ SG_ 168 MO_Torque_Limit_Dyn "[DE: MO_Mom_Begr_dyn]";
CM_ SG_ 168 MO_TorqueIntegral_02 "[DE: MO_Momentenintegral_02]";
CM_ SG_ 168 MO_QBit_Rpm_01 "[DE: MO_QBit_Drehzahl_01]";
CM_ SG_ 168 MO_Rpm_01 "[DE: MO_Drehzahl_01]";
CM_ SG_ 173 GE_MTorque_Target_02 "[DE: GE_MMom_Soll_02]";
CM_ SG_ 173 GE_MTorque_Lead_02 "[DE: GE_MMom_Vorhalt_02]";
CM_ SG_ 173 GE_DriveRange "[DE: GE_Fahrstufe]";
CM_ SG_ 173 GE_Reserved_DriveRange "[DE: GE_reserv_Fahrstufe]";
CM_ SG_ 173 GE_ShiftSequence "[DE: GE_Schaltablauf]";
CM_ SG_ 173 GE_Uefkt_Implausible "[DE: GE_Uefkt_unplausibel]";
CM_ SG_ 173 GE_MTorque_Status_02 "[DE: GE_MMom_Status_02]";
CM_ SG_ 173 GE_Status_Traction "[DE: GE_Status_Kraftschluss]";
CM_ SG_ 173 GE_MTorque_Status "[DE: GE_MMom_Status]";
CM_ SG_ 173 GE_Enable_MTorque_Lead "[DE: GE_Freig_MMom_Vorhalt]";
CM_ SG_ 173 GE_Inhibit_Suppression "[DE: GE_Verbot_Ausblendung]";
CM_ SG_ 173 GE_TargetGear "[DE: GE_Zielgang]";
CM_ SG_ 184 EM1_Enable_Info_WFS "[DE: EM1_Freigabe_Info_WFS]";
CM_ SG_ 184 EM1_Lock_Info_WFS "[DE: EM1_Sperr_Info_WFS]";
CM_ SG_ 184 EM1_AR_Active "[DE: EM1_AR_aktiv]";
CM_ SG_ 184 EM1_ActualCurrent "[DE: EM1_IstStrom]";
CM_ SG_ 184 EM1_Error_ElDriveFreewheel_Req "[DE: EM1_Fehler_ElAntriebFreilauf_Anf]";
CM_ SG_ 184 EM1_Limiting_Temperature "[DE: EM1_Abregelung_Temperatur]";
CM_ SG_ 184 EM1_AnlernenElEngine_Req "[DE: EM1_AnlernenElMotor_Anf]";
CM_ SG_ 184 EM1_Torque_HVConsumer "[DE: EM1_Moment_HVVerbraucher]";
CM_ SG_ 184 EM1_Enable_ExpiryInfo_WFS "[DE: EM1_Freigabe_Verfallsinfo_WFS]";
CM_ SG_ 184 EM1_Parking_WFS_Status "[DE: EM1_Parken_WFS_Status]";
CM_ SG_ 184 EM1_HV_Operational "[DE: EM1_HV_betriebsbereit]";
CM_ SG_ 192 OverrunOperation "[DE: Schubbetrieb]";
CM_ SG_ 253 BR_InterventionTorque "[DE: BR_Eingriffsmoment]";
CM_ SG_ 253 ESP_Diagnostics "[DE: ESP_Diagnose]";
CM_ SG_ 253 ESP_BeforeControl "[DE: ESP_Vorsteuerung]";
CM_ SG_ 253 OBD_RoughRoad "[DE: OBD_Schlechtweg]";
CM_ SG_ 253 OBD_QBit_RoughRoad "[DE: OBD_QBit_Schlechtweg]";
CM_ SG_ 253 ASR_Keying_Passive "[DE: ASR_Tastung_passiv]";
CM_ SG_ 253 ESP_Keying_Passive "[DE: ESP_Tastung_passiv]";
CM_ SG_ 253 ESP_SystemStatus "[DE: ESP_Systemstatus]";
CM_ SG_ 253 ASR_ShiftIntervention "[DE: ASR_Schalteingriff]";
CM_ SG_ 253 ABS_Braking "[DE: ABS_Bremsung]";
CM_ SG_ 253 ASR_Req "[DE: ASR_Anf]";
CM_ SG_ 253 MSR_Req "[DE: MSR_Anf]";
CM_ SG_ 253 EBV_Intervention "[DE: EBV_Eingriff]";
CM_ SG_ 253 EDS_Intervention "[DE: EDS_Eingriff]";
CM_ SG_ 253 ESP_Intervention "[DE: ESP_Eingriff]";
CM_ SG_ 253 ESC_NeutralShift "[DE: ESC_Neutralschaltung]";
CM_ SG_ 258 Rain_Braking "[DE: Regen_Braking]";
CM_ SG_ 278 ESP_QBit_DistancePulse_VL "[DE: ESP_QBit_Wegimpuls_VL]";
CM_ SG_ 278 ESP_QBit_DistancePulse_VR "[DE: ESP_QBit_Wegimpuls_VR]";
CM_ SG_ 278 ESP_QBit_DistancePulse_HL "[DE: ESP_QBit_Wegimpuls_HL]";
CM_ SG_ 278 ESP_QBit_DistancePulse_HR "[DE: ESP_QBit_Wegimpuls_HR]";
CM_ SG_ 278 ESP_DistancePulse_VL "[DE: ESP_Wegimpuls_VL]";
CM_ SG_ 278 ESP_DistancePulse_VR "[DE: ESP_Wegimpuls_VR]";
CM_ SG_ 278 ESP_DistancePulse_HL "[DE: ESP_Wegimpuls_HL]";
CM_ SG_ 278 ESP_DistancePulse_HR "[DE: ESP_Wegimpuls_HR]";
CM_ SG_ 278 ESP_VL_Direction "[DE: ESP_VL_Fahrtrichtung]";
CM_ SG_ 278 ESP_VR_Direction "[DE: ESP_VR_Fahrtrichtung]";
CM_ SG_ 278 ESP_HL_Direction "[DE: ESP_HL_Fahrtrichtung]";
CM_ SG_ 278 ESP_HR_Direction "[DE: ESP_HR_Fahrtrichtung]";
CM_ SG_ 285 EPS_LimpHome "[DE: EPS_Notlauf]";
CM_ SG_ 285 EPS_LoadInfo "[DE: EPS_Lastinfo]";
CM_ SG_ 285 EPS_RpmReserve "[DE: EPS_Drehzahlreserve]";
CM_ SG_ 285 EPS_VZ_RpmReserve "[DE: EPS_VZ_Drehzahlreserve]";
CM_ SG_ 285 EPS_PowerRequest "[DE: EPS_Leistungsanforderung]";
CM_ SG_ 294 EA_ACC_TargetStatus "[DE: EA_ACC_Sollstatus]";
CM_ SG_ 294 EA_JerkProfile "[DE: EA_Ruckprofil]";
CM_ SG_ 294 EA_JerkEnable "[DE: EA_Ruckfreigabe]";
CM_ SG_ 294 EA_ACC_SetSpeed "[DE: EA_ACC_Wunschgeschwindigkeit]";
CM_ SG_ 299 GRA_MainSwitch "[DE: GRA_Hauptschalter]";
CM_ SG_ 299 GRA_Cancel "[DE: GRA_Abbrechen]";
CM_ SG_ 299 GRA_Type_MainSwitch "[DE: GRA_Typ_Hauptschalter]";
CM_ SG_ 299 GRA_Tip_Set "[DE: GRA_Tip_Setzen]";
CM_ SG_ 299 GRA_Tip_High "[DE: GRA_Tip_Hoch]";
CM_ SG_ 299 GRA_Tip_Down "[DE: GRA_Tip_Runter]";
CM_ SG_ 299 GRA_Tip_Resume "[DE: GRA_Tip_Wiederaufnahme]";
CM_ SG_ 299 GRA_Adjustment_TimeGap "[DE: GRA_Verstellung_Zeitluecke]";
CM_ SG_ 299 GRA_Coding "[DE: GRA_Codierung]";
CM_ SG_ 299 GRA_Error "[DE: GRA_Fehler]";
CM_ SG_ 299 GRA_LIM_Key_Available "[DE: GRA_LIM_Taste_verfuegbar]";
CM_ SG_ 299 GRA_Tip_Stage_2 "[DE: GRA_Tip_Stufe_2]";
CM_ SG_ 299 GRA_ReserveByte4 "[DE: GRA_reserveByte4]";
CM_ SG_ 299 GRA_ReserveByte5 "[DE: GRA_reserveByte5]";
CM_ SG_ 299 GRA_ReserveByte6 "[DE: GRA_reserveByte6]";
CM_ SG_ 299 GRA_ReserveByte7 "[DE: GRA_reserveByte7]";
CM_ SG_ 299 GRA_ReserveByte8 "[DE: GRA_reserveByte8]";
CM_ SG_ 319 PreCrash_Charisma_DrivePr "[DE: PreCrash_Charisma_FahrPr]";
CM_ SG_ 319 PreCrash_Sunroof_Close "[DE: PreCrash_Schiebedach_schliessen]";
CM_ SG_ 319 PreCrash_Window_Close "[DE: PreCrash_Fenster_schliessen]";
CM_ SG_ 319 PreCrash_Flash "[DE: PreCrash_Blinken]";
CM_ SG_ 319 PreCrash_Doors_Lock "[DE: PreCrash_Tueren_Verriegeln]";
CM_ SG_ 319 PreCrash_Request_AFR "[DE: PreCrash_Anforderung_AFR]";
CM_ SG_ 319 PreCrash_FS_Pneumatic_Actuate "[DE: PreCrash_FS_Pneumatik_ansteuern]";
CM_ SG_ 319 PreCrash_BFS_Pneumatic_Actuate "[DE: PreCrash_BFS_Pneumatik_ansteuern]";
CM_ SG_ 319 PreCrash_Fo_Pneumatic_Actuate "[DE: PreCrash_Fo_Pneumatik_ansteuern]";
CM_ SG_ 319 PreCrash_FS_Backrest_Procedure "[DE: PreCrash_FS_Sitzlehne_verfahren]";
CM_ SG_ 319 PreCrash_BFS_Backrest_Procedure "[DE: PreCrash_BFS_Sitzlehne_verfahren]";
CM_ SG_ 319 PreCrash_Fo_Backrest_Procedure "[DE: PreCrash_Fo_Sitzlehne_verfahren]";
CM_ SG_ 319 PreCrash_FS_KSV_Procedure "[DE: PreCrash_FS_KSV_verfahren]";
CM_ SG_ 319 PreCrash_BFS_KSV_Procedure "[DE: PreCrash_BFS_KSV_verfahren]";
CM_ SG_ 319 PreCrash_Fo_KSV_Procedure "[DE: PreCrash_Fo_KSV_verfahren]";
CM_ SG_ 319 SC_PreCrash_Warning "[DE: SC_PreCrash_Warnung]";
CM_ SG_ 333 ACC_Limited_PullAwayDyn "[DE: ACC_limitierte_Anfahrdyn]";
CM_ SG_ 333 ACC_Retrofit_Stop_Req "[DE: ACC_nachtr_Stopp_Anf]";
CM_ SG_ 333 ACC_DynIncrease "[DE: ACC_DynErhoehung]";
CM_ SG_ 333 ACC_FreewheelStrategy_TSK "[DE: ACC_Freilaufstrategie_TSK]";
CM_ SG_ 333 ACC_Allowed_ControlDeviation_Bottom "[DE: ACC_zul_Regelabw_unten]";
CM_ SG_ 333 ACC_StartStop_Info "[DE: ACC_StartStopp_Info]";
CM_ SG_ 333 ACC_TargetAcceleration_02 "[DE: ACC_Sollbeschleunigung_02]";
CM_ SG_ 333 ACC_Allowed_ControlDeviation_Top "[DE: ACC_zul_Regelabw_oben]";
CM_ SG_ 333 ACC_Neg_TargetAccel_Degree_02 "[DE: ACC_neg_Sollbeschl_Grad_02]";
CM_ SG_ 333 ACC_pos_TargetAccel_Degree_02 "[DE: ACC_pos_Sollbeschl_Grad_02]";
CM_ SG_ 333 ACC_PullAway "[DE: ACC_Anfahren]";
CM_ SG_ 333 ACC_Stop "[DE: ACC_Anhalten]";
CM_ SG_ 333 ACC_Type "[DE: ACC_Typ]";
CM_ SG_ 333 ACC_Minimum_Braking "[DE: ACC_Minimale_Bremsung]";
CM_ SG_ 333 ACC_StoppingDistance "[DE: ACC_Anhalteweg]";
CM_ SG_ 333 ACC_Request_HMS "[DE: ACC_Anforderung_HMS]";
CM_ SG_ 333 ACC_Active_Controls "[DE: ACC_AKTIV_regelt]";
CM_ SG_ 339 MO_HVEM_Escalation "[DE: MO_HVEM_Eskalation]";
CM_ SG_ 339 MO_ExtGrenzen_Req "[DE: MO_ErwGrenzen_Anf]";
CM_ SG_ 339 MO_Error_Notentladung_Req "[DE: MO_Fehler_Notentladung_Anf]";
CM_ SG_ 339 MO_HVEM_MaxPower "[DE: MO_HVEM_MaxLeistung]";
CM_ SG_ 339 MO_HVK_EmActualState "[DE: MO_HVK_EmIstzustand]";
CM_ SG_ 339 MO_HVK_DriveErrorStatus "[DE: MO_HVK_AntriebFehlerstatus]";
CM_ SG_ 339 MO_MVK_VehicleElectrics_Req "[DE: MO_MVK_Bordnetz_Anf]";
CM_ SG_ 339 MO_HVK_DriveState "[DE: MO_HVK_AntriebZustand]";
CM_ SG_ 339 MO_HVK_EmErrorStatus "[DE: MO_HVK_EmFehlerstatus]";
CM_ SG_ 339 MO_MVK_DriveErrorStatus "[DE: MO_MVK_AntriebFehlerstatus]";
CM_ SG_ 339 MO_MVK_DriveState "[DE: MO_MVK_AntriebZustand]";
CM_ SG_ 339 MO_MVK_EmErrorStatus "[DE: MO_MVK_EmFehlerstatus]";
CM_ SG_ 339 MO_MVK_EmActualState "[DE: MO_MVK_EmIstzustand]";
CM_ SG_ 420 EA_Parking_Retain_HMS "[DE: EA_Parken_beibehalten_HMS]";
CM_ SG_ 420 EA_WarnJerkProfile "[DE: EA_Warnruckprofil]";
CM_ SG_ 420 EA_eCall_Req "[DE: EA_eCall_Anf]";
CM_ SG_ 420 EA_BeltTensioner_Req "[DE: EA_Gurtstraffer_Anf]";
CM_ SG_ 420 EA_Request_HMS "[DE: EA_Anforderung_HMS]";
CM_ SG_ 420 EA_TargetAcceleration "[DE: EA_Sollbeschleunigung]";
CM_ SG_ 517 Left_Indicator "[DE: Left_Blinker]";
CM_ SG_ 517 Right_Indicator "[DE: Right_Blinker]";
CM_ SG_ 605 KLR_Error "[DE: KLR_Fehler]";
CM_ SG_ 605 KLR_LocalActive "[DE: KLR_Lokalaktiv]";
CM_ SG_ 605 KLR_Error_Coding "[DE: KLR_Fehler_Codierung]";
CM_ SG_ 605 KLR_TouchIntensity_1 "[DE: KLR_Touchintensitaet_1]";
CM_ SG_ 605 KLR_TouchIntensity_2 "[DE: KLR_Touchintensitaet_2]";
CM_ SG_ 605 KLR_TouchIntensity_3 "[DE: KLR_Touchintensitaet_3]";
CM_ SG_ 706 MO_Display_StSt_Text "[DE: MO_Anzeige_StSt_Text]";
CM_ SG_ 706 MO_Display_StSt_Symbol "[DE: MO_Anzeige_StSt_Symbol]";
CM_ SG_ 706 MO_ADDR_Status "[DE: MO_ADR_Status]";
CM_ SG_ 706 MO_Display_FMOff_Text "[DE: MO_Anzeige_FMAus_Text]";
CM_ SG_ 706 MO_Error_MSpG "[DE: MO_Fehler_MSpG]";
CM_ SG_ 706 TSK_Overruled_vMax_DriverInfo "[DE: TSK_Ueberstimmt_vMax_FahrerInfo]";
CM_ SG_ 706 MO_Avus_EngineProtection "[DE: MO_Avus_Motorschutz]";
CM_ SG_ 706 MO_RecuperationStage "[DE: MO_Rekuperationsstufe]";
CM_ SG_ 706 TSK_Unit_vMax_DriverInfo "[DE: TSK_Einheit_vMax_FahrerInfo]";
CM_ SG_ 706 TSK_Status_vMax_DriverInfo "[DE: TSK_Status_vMax_FahrerInfo]";
CM_ SG_ 706 MO_Red_DrivePower "[DE: MO_Red_Fahrleistung]";
CM_ SG_ 706 MO_Disp_RadiatorFan "[DE: MO_Anz_Kuehlerluefter]";
CM_ SG_ 706 MO_In_Idle "[DE: MO_im_Leerlauf]";
CM_ SG_ 706 WIV_Enable_OilPressure_Engine "[DE: WIV_Enable_Oeldr_Motor]";
CM_ SG_ 706 MO_OilMeasurement_Duration "[DE: MO_OelMessung_Dauer]";
CM_ SG_ 706 TSK_vMax_DriverInfo "[DE: TSK_vMax_FahrerInfo]";
CM_ SG_ 795 ESP_Lamp "[DE: ESP_Lampe]";
CM_ SG_ 795 ABS_Lamp "[DE: ABS_Lampe]";
CM_ SG_ 795 BK_Lamp_02 "[DE: BK_Lampe_02]";
CM_ SG_ 795 TC_Lamp "[DE: TC_Lampe]";
CM_ SG_ 795 ESP_m_WheelSpeed "[DE: ESP_m_Raddrehz]";
CM_ SG_ 795 ESP_DistPulse_VA "[DE: ESP_Wegimp_VA]";
CM_ SG_ 795 ESP_ErrorStatus_DistPulse "[DE: ESP_Fehlerstatus_Wegimp]";
CM_ SG_ 795 ESP_DistPulse_Overflow "[DE: ESP_Wegimp_Ueberlauf]";
CM_ SG_ 795 ESP_QBit_DistPulse_VA "[DE: ESP_QBit_Wegimp_VA]";
CM_ SG_ 795 ESP_HDC_Speed_Colour "[DE: ESP_HDC_Geschw_Farbe]";
CM_ SG_ 795 ESP_Off_Lamp "[DE: ESP_Off_Lampe]";
CM_ SG_ 795 ESP_HDC_ControlSpeed "[DE: ESP_HDC_Regelgeschw]";
CM_ SG_ 795 ESP_BKV_Warning "[DE: ESP_BKV_Warnung]";
CM_ SG_ 817 MFL_Counter "[DE: MFL_Zaehler]";
CM_ SG_ 817 MFL_LocalActive "[DE: MFL_Lokalaktiv]";
CM_ SG_ 817 MFL_M_Key "[DE: MFL_M_Taste]";
CM_ SG_ 817 MFL_Paddle_Fitment "[DE: MFL_Paddle_Verbau]";
CM_ SG_ 817 MFL_KeyCode_1 "[DE: MFL_Tastencode_1]";
CM_ SG_ 817 MFL_KeyCode_2 "[DE: MFL_Tastencode_2]";
CM_ SG_ 817 MFL_Brand "[DE: MFL_Marke]";
CM_ SG_ 817 MFL_Variant "[DE: MFL_Variante]";
CM_ SG_ 817 MFL_SatModule_Left_Err "[DE: MFL_SatModul_links_Err]";
CM_ SG_ 817 MFL_SatModule_Right_Err "[DE: MFL_SatModul_rechts_Err]";
CM_ SG_ 817 MFL_Horn "[DE: MFL_Signalhorn]";
CM_ SG_ 817 MFL_Horn_Err "[DE: MFL_Signalhorn_Err]";
CM_ SG_ 817 MFL_Tip_Left_Err "[DE: MFL_Tip_links_Err]";
CM_ SG_ 817 MFL_Tip_Right_Err "[DE: MFL_Tip_rechts_Err]";
CM_ SG_ 817 MFL_Key_Left_Err "[DE: MFL_Taste_links_Err]";
CM_ SG_ 817 MFL_Key_Right_Err "[DE: MFL_Taste_rechts_Err]";
CM_ SG_ 850 Parking_SM_03_MUX "[DE: Parken_SM_03_MUX]";
CM_ SG_ 850 Parking_SM_03_Traj_Trans_ID_00 "[DE: Parken_SM_03_Traj_Trans_ID_00]";
CM_ SG_ 850 Parking_Traj_P1_Pos_X "[DE: Parken_Traj_P1_Pos_X]";
CM_ SG_ 850 Parking_Traj_P1_Pos_Y "[DE: Parken_Traj_P1_Pos_Y]";
CM_ SG_ 850 Parking_Traj_P1_Tangent "[DE: Parken_Traj_P1_Tangent]";
CM_ SG_ 850 Parking_Traj_P2_Pos_X "[DE: Parken_Traj_P2_Pos_X]";
CM_ SG_ 850 Parking_SM_03_Traj_Trans_ID_01 "[DE: Parken_SM_03_Traj_Trans_ID_01]";
CM_ SG_ 850 Parking_Traj_P2_Pos_Y "[DE: Parken_Traj_P2_Pos_Y]";
CM_ SG_ 850 Parking_Traj_P2_Tangent "[DE: Parken_Traj_P2_Tangent]";
CM_ SG_ 850 Parking_Traj_P3_Pos_X "[DE: Parken_Traj_P3_Pos_X]";
CM_ SG_ 850 Parking_Traj_P3_Pos_Y "[DE: Parken_Traj_P3_Pos_Y]";
CM_ SG_ 850 Parking_SM_03_Traj_Trans_ID_02 "[DE: Parken_SM_03_Traj_Trans_ID_02]";
CM_ SG_ 850 Parking_Traj_P3_Tangent "[DE: Parken_Traj_P3_Tangent]";
CM_ SG_ 850 Parking_Traj_P4_Pos_X "[DE: Parken_Traj_P4_Pos_X]";
CM_ SG_ 850 Parking_Traj_P4_Pos_Y "[DE: Parken_Traj_P4_Pos_Y]";
CM_ SG_ 850 Parking_Traj_P4_Tangent "[DE: Parken_Traj_P4_Tangent]";
CM_ SG_ 850 Parking_SM_03_Traj_Trans_ID_03 "[DE: Parken_SM_03_Traj_Trans_ID_03]";
CM_ SG_ 850 Parking_Traj_P5_Pos_X "[DE: Parken_Traj_P5_Pos_X]";
CM_ SG_ 850 Parking_Traj_P5_Pos_Y "[DE: Parken_Traj_P5_Pos_Y]";
CM_ SG_ 850 Parking_Traj_P5_Tangent "[DE: Parken_Traj_P5_Tangent]";
CM_ SG_ 850 Parking_Traj_P6_Pos_X "[DE: Parken_Traj_P6_Pos_X]";
CM_ SG_ 850 Parking_SM_03_Traj_Trans_ID_04 "[DE: Parken_SM_03_Traj_Trans_ID_04]";
CM_ SG_ 850 Parking_Traj_P6_Pos_Y "[DE: Parken_Traj_P6_Pos_Y]";
CM_ SG_ 850 Parking_Traj_P6_Tangent "[DE: Parken_Traj_P6_Tangent]";
CM_ SG_ 850 Parking_Traj_P7_Pos_X "[DE: Parken_Traj_P7_Pos_X]";
CM_ SG_ 850 Parking_Traj_P7_Pos_Y "[DE: Parken_Traj_P7_Pos_Y]";
CM_ SG_ 850 Parking_SM_03_Traj_Trans_ID_05 "[DE: Parken_SM_03_Traj_Trans_ID_05]";
CM_ SG_ 850 Parking_Traj_P7_Tangent "[DE: Parken_Traj_P7_Tangent]";
CM_ SG_ 850 Parking_Traj_P8_Pos_X "[DE: Parken_Traj_P8_Pos_X]";
CM_ SG_ 850 Parking_Traj_P8_Pos_Y "[DE: Parken_Traj_P8_Pos_Y]";
CM_ SG_ 850 Parking_Traj_P8_Tangent "[DE: Parken_Traj_P8_Tangent]";
CM_ SG_ 850 Parking_SM_03_Traj_Trans_ID_06 "[DE: Parken_SM_03_Traj_Trans_ID_06]";
CM_ SG_ 850 Parking_Traj_P9_Pos_X "[DE: Parken_Traj_P9_Pos_X]";
CM_ SG_ 850 Parking_Traj_P9_Pos_Y "[DE: Parken_Traj_P9_Pos_Y]";
CM_ SG_ 850 Parking_Traj_P9_Tangent "[DE: Parken_Traj_P9_Tangent]";
CM_ SG_ 869 NVEM_P_Alternator_Status "[DE: NVEM_P_Generator_Status]";
CM_ SG_ 869 BEM_P_Alternator "[DE: BEM_P_Generator]";
CM_ SG_ 869 BEM_Req_TERM "[DE: BEM_Anf_KL]";
CM_ SG_ 869 BEM_StartStop_Info "[DE: BEM_StartStopp_Info]";
CM_ SG_ 869 BEM_Batt_From "[DE: BEM_Batt_Ab]";
CM_ SG_ 869 NVEM_Red_TERM "[DE: NVEM_Red_KL]";
CM_ SG_ 869 NVEM_Freewheel_Info "[DE: NVEM_Freilauf_Info]";
CM_ SG_ 869 BEM_HYB_DC_uTargetLV "[DE: BEM_HYB_DC_uSollLV]";
CM_ SG_ 870 BM_ZV_Open "[DE: BM_ZV_auf]";
CM_ SG_ 870 BM_ZV_Closed "[DE: BM_ZV_zu]";
CM_ SG_ 870 BM_DWA_On "[DE: BM_DWA_ein]";
CM_ SG_ 870 BM_Panic "[DE: BM_Panik]";
CM_ SG_ 870 BM_Not_Braking "[DE: BM_Not_Bremsung]";
CM_ SG_ 870 BM_HazardFlash "[DE: BM_Warnblinken]";
CM_ SG_ 870 BM_Telematics "[DE: BM_Telematik]";
CM_ SG_ 870 BM_Left "[DE: BM_links]";
CM_ SG_ 870 BM_Right "[DE: BM_rechts]";
CM_ SG_ 870 Flash_Left_Veh_Clock "[DE: Blinken_li_Fzg_Takt]";
CM_ SG_ 870 Flash_Right_Veh_Clock "[DE: Blinken_re_Fzg_Takt]";
CM_ SG_ 870 Flash_Left_Cluster_Clock "[DE: Blinken_li_Kombi_Takt]";
CM_ SG_ 870 Flash_Right_Cluster_Clock "[DE: Blinken_re_Kombi_Takt]";
CM_ SG_ 870 BM_NBA_n_Coded_n_Active "[DE: BM_NBA_n_codiert_n_aktiv]";
CM_ SG_ 870 BM_WBT_Lighting "[DE: BM_WBT_Beleuchtung]";
CM_ SG_ 870 BM_HD_Opening_angelernt "[DE: BM_HD_Oeffnung_angelernt]";
CM_ SG_ 870 BM_Motorway "[DE: BM_Autobahn]";
CM_ SG_ 870 BM_RollerMode_Flash "[DE: BM_Rollenmodus_Blinken]";
CM_ SG_ 870 BM_Telematics_Abbruchgrund "[DE: BM_Telematik_Abbruchgrund]";
CM_ SG_ 888 GNSS_MessagePacket_ID4 "[DE: GNSS_Nachrichtenpaket_ID4]";
CM_ SG_ 888 GNSS_Location_Time_in_GPSWoche "[DE: GNSS_Ortung_Zeit_in_GPSWoche]";
CM_ SG_ 888 GNSS_Location_Height "[DE: GNSS_Ortung_Hoehe]";
CM_ SG_ 891 GNSS_UTC_Time "[DE: GNSS_UTC_Zeit]";
CM_ SG_ 891 GNSS_Receiver_Status "[DE: GNSS_Empfaenger_Status]";
CM_ SG_ 891 GNSS_GPS_in_Use "[DE: GNSS_GPS_in_Nutzung]";
CM_ SG_ 891 GNSS_GLONASS_in_Use "[DE: GNSS_GLONASS_in_Nutzung]";
CM_ SG_ 891 GNSS_Empfangbare_Satellites "[DE: GNSS_Empfangbare_Satelliten]";
CM_ SG_ 891 GNSS_Sichtbare_Satellites "[DE: GNSS_Sichtbare_Satelliten]";
CM_ SG_ 891 GNSS_Genutzte_Satellites "[DE: GNSS_Genutzte_Satelliten]";
CM_ SG_ 891 GNSS_MessagePacket_ID5 "[DE: GNSS_Nachrichtenpaket_ID5]";
CM_ SG_ 916 WBA_DriveRange_02 "[DE: WBA_Fahrstufe_02]";
CM_ SG_ 916 WBA_TargetDriveRange "[DE: WBA_ZielFahrstufe]";
CM_ SG_ 916 WBA_GE_Warning_02 "[DE: WBA_GE_Warnung_02]";
CM_ SG_ 916 WBA_Input_Gear_02 "[DE: WBA_eing_Gang_02]";
CM_ SG_ 916 WBA_Coasting_Active "[DE: WBA_Segeln_aktiv]";
CM_ SG_ 916 WBA_ShiftPattern "[DE: WBA_Schaltschema]";
CM_ SG_ 916 WBA_GE_AdditionalWarnings "[DE: WBA_GE_Zusatzwarnungen]";
CM_ SG_ 916 GE_TargetGear "[DE: GE_Sollgang]";
CM_ SG_ 916 GE_TipShiftRecommend_Available "[DE: GE_Tipschaltempf_verfuegbar]";
CM_ SG_ 916 WBA_Flash "[DE: WBA_Blinken]";
CM_ SG_ 916 GE_Restart_Disp_Std "[DE: GE_Wiederstart_Anz_Std]";
CM_ SG_ 916 GE_StopInhibit_Disp_01 "[DE: GE_Stoppverbot_Anz_01]";
CM_ SG_ 916 GE_StopInhibit_Disp_02 "[DE: GE_Stoppverbot_Anz_02]";
CM_ SG_ 916 GE_StopInhibit_Disp_03 "[DE: GE_Stoppverbot_Anz_03]";
CM_ SG_ 916 GE_StopInhibit_Disp_04 "[DE: GE_Stoppverbot_Anz_04]";
CM_ SG_ 916 GE_StopInhibit_Disp_05 "[DE: GE_Stoppverbot_Anz_05]";
CM_ SG_ 916 GE_StopInhibit_Disp_06 "[DE: GE_Stoppverbot_Anz_06]";
CM_ SG_ 916 GE_StopInhibit_Disp_07 "[DE: GE_Stoppverbot_Anz_07]";
CM_ SG_ 916 GE_StopInhibit_Disp_Std "[DE: GE_Stoppverbot_Anz_Std]";
CM_ SG_ 919 LDW_Chime "[DE: LDW_Gong]";
CM_ SG_ 919 LDW_SW_Warning_Left "[DE: LDW_SW_Warnung_links]";
CM_ SG_ 919 LDW_SW_Warning_Right "[DE: LDW_SW_Warnung_rechts]";
CM_ SG_ 919 LDW_Side_DLCTLC "[DE: LDW_Seite_DLCTLC]";
CM_ SG_ 919 LDW_LearnMode "[DE: LDW_Lernmodus]";
CM_ SG_ 919 LDW_StartUpTime_VLR "[DE: LDW_Anlaufzeit_VLR]";
CM_ SG_ 919 LDW_LearnMode_Right "[DE: LDW_Lernmodus_rechts]";
CM_ SG_ 919 LDW_LearnMode_Left "[DE: LDW_Lernmodus_links]";
CM_ SG_ 919 LDW_Warning_Left "[DE: LDW_Warnung_links]";
CM_ SG_ 919 LDW_Warning_Right "[DE: LDW_Warnung_rechts]";
CM_ SG_ 919 LDW_CodingInfo_For_VLR "[DE: LDW_Codierinfo_fuer_VLR]";
CM_ SG_ 919 LDW_WindscreenHeating_Active "[DE: LDW_Frontscheibenheizung_aktiv]";
CM_ SG_ 919 LDW_Status_LED_Yellow "[DE: LDW_Status_LED_gelb]";
CM_ SG_ 919 LDW_Status_LED_Green "[DE: LDW_Status_LED_gruen]";
CM_ SG_ 919 LDW_KD_Error "[DE: LDW_KD_Fehler]";
CM_ SG_ 949 TERM_Rpm_Trailer "[DE: KL_Drehz_Anh]";
CM_ SG_ 949 TERM_PreWarn_Compressor_On "[DE: KL_Vorwarn_Komp_ein]";
CM_ SG_ 949 TERM_AC_Switch "[DE: KL_AC_Schalter]";
CM_ SG_ 949 TERM_Compressor_Torque_Old "[DE: KL_Komp_Moment_alt]";
CM_ SG_ 949 TERM_PreWarn_AuxHeater_On "[DE: KL_Vorwarn_Zuheizer_ein]";
CM_ SG_ 949 TERM_State "[DE: KL_Zustand]";
CM_ SG_ 949 TERM_CompressorClutch_linear "[DE: KL_Kompressorkupplung_linear]";
CM_ SG_ 949 TERM_Charisma_DrivePr "[DE: KL_Charisma_FahrPr]";
CM_ SG_ 949 TERM_Charisma_Status "[DE: KL_Charisma_Status]";
CM_ SG_ 949 TERM_Retrofit_Stop_Req "[DE: KL_nachtr_Stopp_Anf]";
CM_ SG_ 949 TERM_T_Charge "[DE: KL_T_Charge]";
CM_ SG_ 949 TERM_Load_Compressor "[DE: KL_Last_Kompr]";
CM_ SG_ 949 TERM_Voltage_Req "[DE: KL_Spannungs_Anf]";
CM_ SG_ 949 TERM_ThermalManagement "[DE: KL_Thermomanagement]";
CM_ SG_ 949 TERM_StartStop_Info "[DE: KL_StartStopp_Info]";
CM_ SG_ 949 TERM_Freewheel_Info "[DE: KL_Freilauf_Info]";
CM_ SG_ 949 TERM_Req_TERM "[DE: KL_Anf_KL]";
CM_ SG_ 949 TERM_el_AuxHeater_Stage "[DE: KL_el_Zuheizer_Stufe]";
CM_ SG_ 949 TERM_Ausstattung_Climate "[DE: KL_Ausstattung_Klima]";
CM_ SG_ 949 TERM_Variant_AuxHeater "[DE: KL_Variante_Standheizung]";
CM_ SG_ 958 MO_StartStop_Status "[DE: MO_StartStopp_Status]";
CM_ SG_ 958 MO_StartStop_Restart "[DE: MO_StartStopp_Wiederstart]";
CM_ SG_ 958 MO_StartStop_EngineStop "[DE: MO_StartStopp_Motorstopp]";
CM_ SG_ 958 MO_Enable_Recup "[DE: MO_Freig_Reku]";
CM_ SG_ 958 MO_Term_75 "[DE: MO_Kl_75]";
CM_ SG_ 958 MO_Term_50 "[DE: MO_Kl_50]";
CM_ SG_ 958 MO_GearPosition "[DE: MO_Gangposition]";
CM_ SG_ 958 MO_StartStop_DriverDemand "[DE: MO_StartStopp_Fahrerwunsch]";
CM_ SG_ 958 MO_HYB_ReadyToDrive "[DE: MO_HYB_Fahrbereitschaft]";
CM_ SG_ 958 MO_Ext_E_Journey_Active "[DE: MO_Ext_E_Fahrt_aktiv]";
CM_ SG_ 958 MO_Driver_Brakes "[DE: MO_Fahrer_bremst]";
CM_ SG_ 958 MO_QBit_Driver_Brakes "[DE: MO_QBit_Fahrer_bremst]";
CM_ SG_ 958 MO_Consistency_BrakePedal "[DE: MO_Konsistenz_Bremsped]";
CM_ SG_ 958 MO_CommError_ESP "[DE: MO_KomFehler_ESP]";
CM_ SG_ 958 MO_Climate_Interv "[DE: MO_Klima_Eingr]";
CM_ SG_ 958 MO_Aussp_Crank "[DE: MO_Aussp_Anlass]";
CM_ SG_ 958 MO_Enable_Crank "[DE: MO_Freig_Anlass]";
CM_ SG_ 958 MO_Clutch_Switch "[DE: MO_Kuppl_schalter]";
CM_ SG_ 958 MO_Engine_Running "[DE: MO_Motor_laeuft]";
CM_ SG_ 958 MO_QBit_TERM_75 "[DE: MO_QBit_KL_75]";
CM_ SG_ 958 MO_ETermCommLeiRed "[DE: MO_EKlKomLeiRed]";
CM_ SG_ 958 MO_BKV_VacuumWarning "[DE: MO_BKV_Unterdruckwarnung]";
CM_ SG_ 958 MO_Enable_Coasting "[DE: MO_Freigabe_Segeln]";
CM_ SG_ 958 MO_QBit_GearPosition "[DE: MO_QBit_Gangposition]";
CM_ SG_ 958 MO_SignalSource_GearPosition "[DE: MO_Signalquelle_Gangposition]";
CM_ SG_ 958 MO_Remotestart_Operation "[DE: MO_Remotestart_Betrieb]";
CM_ SG_ 958 MO_Remotestart_Possible "[DE: MO_Remotestart_moeglich]";
CM_ SG_ 958 MO_FMOff_Active "[DE: MO_FMAus_aktiv]";
CM_ SG_ 958 MO_FMOff_Startvariante "[DE: MO_FMAus_Startvariante]";
CM_ SG_ 958 MO_BMS_NV_Req_stuetzen "[DE: MO_BMS_NV_Anf_stuetzen]";
CM_ SG_ 958 MO_CylinderDeactivation "[DE: MO_Zylinderabschaltung]";
CM_ SG_ 958 MO_HYB_VM_Active "[DE: MO_HYB_VM_aktiv]";
CM_ SG_ 958 MO_StartVorauss_Met "[DE: MO_StartVorauss_erfuellt]";
CM_ SG_ 960 Terminals_Status_01_CRC "[DE: Klemmen_Status_01_CRC]";
CM_ SG_ 960 Terminals_Status_01_BZ "[DE: Klemmen_Status_01_BZ]";
CM_ SG_ 960 RSt_DriverNotices "[DE: RSt_Fahrerhinweise]";
CM_ SG_ 960 ZAS_Term_S "[DE: ZAS_Kl_S]";
CM_ SG_ 960 ZAS_Term_15 "[DE: ZAS_Kl_15]";
CM_ SG_ 960 ZAS_Term_X "[DE: ZAS_Kl_X]";
CM_ SG_ 960 ZAS_Term_50_StartRequest "[DE: ZAS_Kl_50_Startanforderung]";
CM_ SG_ 960 BCM_Remotestart_Operation "[DE: BCM_Remotestart_Betrieb]";
CM_ SG_ 960 ZAS_Term_Infotainment "[DE: ZAS_Kl_Infotainment]";
CM_ SG_ 960 BCM_Remotestart_TERM15_Req "[DE: BCM_Remotestart_KL15_Anf]";
CM_ SG_ 960 KST_DriverNotice_1 "[DE: KST_Fahrerhinweis_1]";
CM_ SG_ 960 KST_DriverNotice_2 "[DE: KST_Fahrerhinweis_2]";
CM_ SG_ 960 BCM_OffParking_Operation "[DE: BCM_Ausparken_Betrieb]";
CM_ SG_ 960 KST_DriverNotice_4 "[DE: KST_Fahrerhinweis_4]";
CM_ SG_ 960 KST_DriverNotice_5 "[DE: KST_Fahrerhinweis_5]";
CM_ SG_ 960 KST_DriverNotice_6 "[DE: KST_Fahrerhinweis_6]";
CM_ SG_ 967 MO_RadiatorFan_MUX "[DE: MO_Kuehlerluefter_MUX]";
CM_ SG_ 967 MO_RadiatorFan_1 "[DE: MO_Kuehlerluefter_1]";
CM_ SG_ 967 MO_RadiatorFan_2 "[DE: MO_Kuehlerluefter_2]";
CM_ SG_ 967 MO_EFLEX_Lamp "[DE: MO_EFLEX_Lampe]";
CM_ SG_ 967 MO_KJS_Not_Ready "[DE: MO_KJS_nicht_bereit]";
CM_ SG_ 967 MO_ITM_Warning_Pump "[DE: MO_ITM_Warnung_Pumpe]";
CM_ SG_ 967 WIV_Display_Active "[DE: WIV_Anzeige_aktiv]";
CM_ SG_ 967 WIV_SensorError "[DE: WIV_Sensorfehler]";
CM_ SG_ 967 WIV_Tilt "[DE: WIV_Schieflage]";
CM_ SG_ 967 WIV_OilLevel "[DE: WIV_Oelstand]";
CM_ SG_ 967 MO_State_HWP "[DE: MO_Zustand_HWP]";
CM_ SG_ 967 OLEV_SystemMalfunction "[DE: OLEV_Systemstoerung]";
CM_ SG_ 967 MO_OilWarning_max "[DE: MO_Oelwarnung_max]";
CM_ SG_ 967 WIV_OilSystem_Active "[DE: WIV_Oelsystem_aktiv]";
CM_ SG_ 967 WIV_Not_AtOperatingTemp "[DE: WIV_nicht_betriebswarm]";
CM_ SG_ 967 WIV_Overfill_Warn "[DE: WIV_Ueberfuell_Warn]";
CM_ SG_ 967 WIV_Running_Engine "[DE: WIV_laufender_Motor]";
CM_ SG_ 967 MO_E_Warnings "[DE: MO_E_Warnungen]";
CM_ SG_ 967 MO_Text_EngineStart "[DE: MO_Text_Motorstart]";
CM_ SG_ 967 WIV_OilDyn_avl "[DE: WIV_Oeldyn_avl]";
CM_ SG_ 967 MO_Text_ParticleFilter_Reg "[DE: MO_Text_Partikelfil_Reg]";
CM_ SG_ 967 OLEV_OilLevel_Not_Present "[DE: OLEV_Oelstand_nicht_vorhanden]";
CM_ SG_ 967 WIV_OilQuantity "[DE: WIV_Oelmenge]";
CM_ SG_ 967 MO_SystemLamp "[DE: MO_Systemlampe]";
CM_ SG_ 967 MO_OBD2_Lamp "[DE: MO_OBD2_Lampe]";
CM_ SG_ 967 MO_HotWarningLamp "[DE: MO_Heissleuchte]";
CM_ SG_ 967 MO_Particle_Lamp "[DE: MO_Partikel_Lampe]";
CM_ SG_ 967 MO_RedDrivePower_Lamp "[DE: MO_RedFahrleistung_Lampe]";
CM_ SG_ 967 WIV_OilLevel_Not_Present "[DE: WIV_Oelstand_nicht_vorhanden]";
CM_ SG_ 967 WIV_RefillDisplay_On "[DE: WIV_nachfuellanzeige_ein]";
CM_ SG_ 967 WIV_Overfill_Deactivated "[DE: WIV_Ueberfuell_deaktiv]";
CM_ SG_ 967 WIV_Underfill_Warn "[DE: WIV_Unterfuell_Warn]";
CM_ SG_ 967 MO_FuelCap_Lamp "[DE: MO_Tankdeckel_Lampe]";
CM_ SG_ 967 MO_Text_FuelCapWarn "[DE: MO_Text_Tankdeckelwarn]";
CM_ SG_ 967 MO_Preheat_Lamp "[DE: MO_Vorglueh_Lampe]";
CM_ SG_ 967 WIV_OilPressure_Warn_Engine "[DE: WIV_Oeldr_Warn_Motor]";
CM_ SG_ 974 HFS_Door_Opened "[DE: HFS_Tuer_geoeffnet]";
CM_ SG_ 974 HFS_Locked "[DE: HFS_verriegelt]";
CM_ SG_ 974 HFS_Safed "[DE: HFS_gesafet]";
CM_ SG_ 974 HFS_RearBlindButton_Pressed "[DE: HFS_Heckrollotaster_betaetigt]";
CM_ SG_ 974 HFS_DoorLock_Defective "[DE: HFS_Tuerschloss_defekt]";
CM_ SG_ 974 HFS_Unlock_PushButton "[DE: HFS_Unlock_Taster]";
CM_ SG_ 974 HFS_Lock_PushButton "[DE: HFS_Lock_Taster]";
CM_ SG_ 974 HFS_ParkPawl "[DE: HFS_Sperrklinke]";
CM_ SG_ 974 HFS_TAG_Pressed "[DE: HFS_TAG_betaetigt]";
CM_ SG_ 974 HFS_TIG_Pressed "[DE: HFS_TIG_betaetigt]";
CM_ SG_ 974 HFS_FH_S_HBFS_AutoHigh "[DE: HFS_FH_S_HBFS_AutoHoch]";
CM_ SG_ 974 HFS_FH_S_HBFS_AutoLow "[DE: HFS_FH_S_HBFS_AutoTief]";
CM_ SG_ 974 HFS_FH_S_HBFS_ManHigh "[DE: HFS_FH_S_HBFS_ManHoch]";
CM_ SG_ 974 HFS_FH_S_HBFS_ManLow "[DE: HFS_FH_S_HBFS_ManTief]";
CM_ SG_ 974 HFS_Door_Status "[DE: HFS_Tuer_Status]";
CM_ SG_ 974 HFS_SAD_Switch "[DE: HFS_SAD_Schalter]";
CM_ SG_ 974 HFS_FH_S_ManHigh "[DE: HFS_FH_S_ManHoch]";
CM_ SG_ 974 HFS_FH_S_AutoHigh "[DE: HFS_FH_S_AutoHoch]";
CM_ SG_ 974 HFS_FH_S_ManLow "[DE: HFS_FH_S_ManTief]";
CM_ SG_ 974 HFS_FH_S_AutoLow "[DE: HFS_FH_S_AutoTief]";
CM_ SG_ 974 HFS_FH_Opening "[DE: HFS_FH_Oeffnung]";
CM_ SG_ 974 HFS_FH_Bew_High "[DE: HFS_FH_Bew_hoch]";
CM_ SG_ 974 HFS_FH_Bew_Low "[DE: HFS_FH_Bew_tief]";
CM_ SG_ 974 HFS_UEKB_Activated "[DE: HFS_UEKB_aktiviert]";
CM_ SG_ 974 HFS_DoorOpen_Warning "[DE: HFS_Tueroeffnen_Warnung]";
CM_ SG_ 974 HFS_FH_Normalised "[DE: HFS_FH_normiert]";
CM_ SG_ 974 ASW_Warning_Active_HFS "[DE: ASW_Warnung_aktiv_HFS]";
CM_ SG_ 974 HFS_SoftClose_Active "[DE: HFS_Zuziehhilfe_aktiv]";
CM_ SG_ 974 HFS_SideBlind_High "[DE: HFS_Seitenrollo_hoch]";
CM_ SG_ 974 HFS_SideBlind_Low "[DE: HFS_Seitenrollo_tief]";
CM_ SG_ 974 HFS_Status_ChildSeat "[DE: HFS_Status_KiSi]";
CM_ SG_ 974 SSR_HFS_Pos_Bottom "[DE: SSR_HFS_Pos_Unten]";
CM_ SG_ 974 HFS_Top_Block_Ext "[DE: HFS_Oben_Block_erw]";
CM_ SG_ 974 HFS_Bottom_Block_Ext "[DE: HFS_Unten_Block_erw]";
CM_ SG_ 974 MTHFS_M_Key "[DE: MTHFS_M_Taste]";
CM_ SG_ 974 HFS_MBlind_Switch "[DE: HFS_MRollo_Schalter]";
CM_ SG_ 974 HFS_Lock_PushButton_inv "[DE: HFS_Lock_Taster_inv]";
CM_ SG_ 974 HFS_Door_Status_QBit "[DE: HFS_Tuer_Status_QBit]";
CM_ SG_ 974 HFS_TCR_Mode_Active "[DE: HFS_TCR_Mode_aktiv]";
CM_ SG_ 975 HBFS_Door_Opened "[DE: HBFS_Tuer_geoeffnet]";
CM_ SG_ 975 HBFS_Locked "[DE: HBFS_verriegelt]";
CM_ SG_ 975 HBFS_Safed "[DE: HBFS_gesafet]";
CM_ SG_ 975 HBFS_RearBlindButton_Pressed "[DE: HBFS_Heckrollotaster_betaetigt]";
CM_ SG_ 975 HBFS_DoorLock_Defective "[DE: HBFS_Tuerschloss_defekt]";
CM_ SG_ 975 HBFS_Unlock_PushButton "[DE: HBFS_Unlock_Taster]";
CM_ SG_ 975 HBFS_Lock_PushButton "[DE: HBFS_Lock_Taster]";
CM_ SG_ 975 HBFS_ParkPawl "[DE: HBFS_Sperrklinke]";
CM_ SG_ 975 HBFS_TAG_Pressed "[DE: HBFS_TAG_betaetigt]";
CM_ SG_ 975 HBFS_TIG_Pressed "[DE: HBFS_TIG_betaetigt]";
CM_ SG_ 975 HBFS_FH_S_HFS_AutoHigh "[DE: HBFS_FH_S_HFS_AutoHoch]";
CM_ SG_ 975 HBFS_FH_S_HFS_AutoLow "[DE: HBFS_FH_S_HFS_AutoTief]";
CM_ SG_ 975 HBFS_FH_S_HFS_ManHigh "[DE: HBFS_FH_S_HFS_ManHoch]";
CM_ SG_ 975 HBFS_FH_S_HFS_ManLow "[DE: HBFS_FH_S_HFS_ManTief]";
CM_ SG_ 975 HBFS_Door_Status "[DE: HBFS_Tuer_Status]";
CM_ SG_ 975 HBFS_SAD_Switch "[DE: HBFS_SAD_Schalter]";
CM_ SG_ 975 HBFS_FH_S_ManHigh "[DE: HBFS_FH_S_ManHoch]";
CM_ SG_ 975 HBFS_FH_S_AutoHigh "[DE: HBFS_FH_S_AutoHoch]";
CM_ SG_ 975 HBFS_FH_S_ManLow "[DE: HBFS_FH_S_ManTief]";
CM_ SG_ 975 HBFS_FH_S_AutoLow "[DE: HBFS_FH_S_AutoTief]";
CM_ SG_ 975 HBFS_FH_Opening "[DE: HBFS_FH_Oeffnung]";
CM_ SG_ 975 HBFS_FH_Bew_High "[DE: HBFS_FH_Bew_hoch]";
CM_ SG_ 975 HBFS_FH_Bew_Low "[DE: HBFS_FH_Bew_tief]";
CM_ SG_ 975 HBFS_UEKB_Activated "[DE: HBFS_UEKB_aktiviert]";
CM_ SG_ 975 HBFS_DoorOpen_Warning "[DE: HBFS_Tueroeffnen_Warnung]";
CM_ SG_ 975 HBFS_FH_Normalised "[DE: HBFS_FH_normiert]";
CM_ SG_ 975 ASW_Warning_Active_HBFS "[DE: ASW_Warnung_aktiv_HBFS]";
CM_ SG_ 975 HBFS_SoftClose_Active "[DE: HBFS_Zuziehhilfe_aktiv]";
CM_ SG_ 975 HBFS_SideBlind_High "[DE: HBFS_Seitenrollo_hoch]";
CM_ SG_ 975 HBFS_SideBlind_Low "[DE: HBFS_Seitenrollo_tief]";
CM_ SG_ 975 HBFS_Status_ChildSeat "[DE: HBFS_Status_KiSi]";
CM_ SG_ 975 SSR_HBFS_Pos_Bottom "[DE: SSR_HBFS_Pos_Unten]";
CM_ SG_ 975 HBFS_Top_Block_Ext "[DE: HBFS_Oben_Block_erw]";
CM_ SG_ 975 HBFS_Bottom_Block_Ext "[DE: HBFS_Unten_Block_erw]";
CM_ SG_ 975 MTHBFS_M_Key "[DE: MTHBFS_M_Taste]";
CM_ SG_ 975 HBFS_MBlind_Switch "[DE: HBFS_MRollo_Schalter]";
CM_ SG_ 975 HBFS_Lock_PushButton_inv "[DE: HBFS_Lock_Taster_inv]";
CM_ SG_ 975 HBFS_Status_ChildSeat_inv "[DE: HBFS_Status_KiSi_inv]";
CM_ SG_ 975 HBFS_Door_Status_QBit "[DE: HBFS_Tuer_Status_QBit]";
CM_ SG_ 975 HBFS_TIG_Pressed_Close "[DE: HBFS_TIG_betaetigt_schliessen]";
CM_ SG_ 976 FT_Door_Opened "[DE: FT_Tuer_geoeffnet]";
CM_ SG_ 976 FT_Locked "[DE: FT_verriegelt]";
CM_ SG_ 976 FT_Safed "[DE: FT_gesafet]";
CM_ SG_ 976 FT_KeySwitch_Open "[DE: FT_Schluesselschalter_auf]";
CM_ SG_ 976 FT_KeySwitch_Closed "[DE: FT_Schluesselschalter_zu]";
CM_ SG_ 976 FT_Unlock_PushButton "[DE: FT_Unlock_Taster]";
CM_ SG_ 976 FT_Lock_PushButton "[DE: FT_Lock_Taster]";
CM_ SG_ 976 FT_ParkPawl "[DE: FT_Sperrklinke]";
CM_ SG_ 976 FT_TAG_Pressed "[DE: FT_TAG_betaetigt]";
CM_ SG_ 976 FT_TIG_Pressed "[DE: FT_TIG_betaetigt]";
CM_ SG_ 976 FT_IRUE_Key "[DE: FT_IRUE_Taste]";
CM_ SG_ 976 FT_HD_Key "[DE: FT_HD_Taste]";
CM_ SG_ 976 FT_TD_Key_Error "[DE: FT_TD_Taste_Fehler]";
CM_ SG_ 976 FT_TD_Key "[DE: FT_TD_Taste]";
CM_ SG_ 976 SSR_Temp_Enable "[DE: SSR_Temp_Freigabe]";
CM_ SG_ 976 FT_Sp_Heating_Req "[DE: FT_Sp_Heizung_Anf]";
CM_ SG_ 976 FT_HD_Key_2 "[DE: FT_HD_Taste_2]";
CM_ SG_ 976 FT_DoorECU_Rear_Fitted "[DE: FT_TSG_hinten_verbaut]";
CM_ SG_ 976 FT_FH_S_ManHigh "[DE: FT_FH_S_ManHoch]";
CM_ SG_ 976 FT_FH_S_AutoHigh "[DE: FT_FH_S_AutoHoch]";
CM_ SG_ 976 FT_FH_S_ManLow "[DE: FT_FH_S_ManTief]";
CM_ SG_ 976 FT_FH_S_AutoLow "[DE: FT_FH_S_AutoTief]";
CM_ SG_ 976 FT_FH_Opening "[DE: FT_FH_Oeffnung]";
CM_ SG_ 976 FT_FH_Bew_High "[DE: FT_FH_Bew_hoch]";
CM_ SG_ 976 FT_FH_Bew_Low "[DE: FT_FH_Bew_tief]";
CM_ SG_ 976 FT_UEKB_Activated "[DE: FT_UEKB_aktiviert]";
CM_ SG_ 976 ASW_HMI_Defective "[DE: ASW_HMI_defekt]";
CM_ SG_ 976 FT_FH_Normalised "[DE: FT_FH_normiert]";
CM_ SG_ 976 FT_CloseButton "[DE: FT_Schliesstaster]";
CM_ SG_ 976 FT_SoftClose_Active "[DE: FT_Zuziehhilfe_aktiv]";
CM_ SG_ 976 FT_SP_Disengaged "[DE: FT_SP_ausgerastet]";
CM_ SG_ 976 FT_SP_lr_Active "[DE: FT_SP_lr_aktiv]";
CM_ SG_ 976 FT_SP_ht_Active "[DE: FT_SP_ht_aktiv]";
CM_ SG_ 976 FT_Top_Block_Ext "[DE: FT_Oben_Block_erw]";
CM_ SG_ 976 FT_Bottom_Block_Ext "[DE: FT_Unten_Block_erw]";
CM_ SG_ 976 FT_ChildSeat_Left_Active "[DE: FT_Kisi_li_aktiv]";
CM_ SG_ 976 FT_ChildSeat_Right_Active "[DE: FT_Kisi_re_aktiv]";
CM_ SG_ 976 FT_ChildSeat_PushButton_Left "[DE: FT_Kisi_Taster_li]";
CM_ SG_ 976 FT_ChildSeat_PushButton_Right "[DE: FT_Kisi_Taster_re]";
CM_ SG_ 976 FT_BFS_Fond_Enable "[DE: FT_BFS_Fond_Freigabe]";
CM_ SG_ 976 FT_ChildSeat_Error "[DE: FT_Kisi_Fehler]";
CM_ SG_ 976 FT_SP_Heating_Status "[DE: FT_SP_Heizung_Status]";
CM_ SG_ 976 ASW_Warning_Active_FS "[DE: ASW_Warnung_aktiv_FS]";
CM_ SG_ 976 FT_FH_Pos_Top "[DE: FT_FH_Pos_oben]";
CM_ SG_ 976 FT_DoorLock_Defective "[DE: FT_Tuerschloss_defekt]";
CM_ SG_ 976 FT_SWA_PushButton "[DE: FT_SWA_Taster]";
CM_ SG_ 976 SWA_HMI_Diagnostics "[DE: SWA_HMI_Diagnose]";
CM_ SG_ 980 BH_Indicator_Left "[DE: BH_Blinker_li]";
CM_ SG_ 980 BH_Indicator_Right "[DE: BH_Blinker_re]";
CM_ SG_ 980 BH_HeadlightFlash "[DE: BH_Lichthupe]";
CM_ SG_ 980 BH_HighBeam "[DE: BH_Fernlicht]";
CM_ SG_ 980 WH_TipWipe "[DE: WH_Tipwischen]";
CM_ SG_ 980 WH_WiperStage1 "[DE: WH_WischerStufe1]";
CM_ SG_ 980 WH_WiperStage2 "[DE: WH_WischerStufe2]";
CM_ SG_ 980 WH_FrontWash "[DE: WH_Frontwaschen]";
CM_ SG_ 980 WH_RearWash "[DE: WH_Heckwaschen]";
CM_ SG_ 980 FAS_PushButton "[DE: FAS_Taster]";
CM_ SG_ 980 FAS_PushButton_Error "[DE: FAS_Taster_Fehler]";
CM_ SG_ 980 SMLS_Horn "[DE: SMLS_Hupe]";
CM_ SG_ 980 LRH_Active "[DE: LRH_aktiv]";
CM_ SG_ 980 SMLS_P_Locked_Plausible "[DE: SMLS_P_verriegelt_plausibel]";
CM_ SG_ 980 WH_Wiper_Error "[DE: WH_Wischer_Fehler]";
CM_ SG_ 980 BH_Indicator_Error "[DE: BH_Blinker_Fehler]";
CM_ SG_ 980 WH_TipWipe_Long "[DE: WH_Tipwischen_lang]";
CM_ SG_ 981 Light_Req_01_CRC "[DE: Licht_Anf_01_CRC]";
CM_ SG_ 981 Light_Req_01_BZ "[DE: Licht_Anf_01_BZ]";
CM_ SG_ 981 BCM1_CorneringLight_Left_Req "[DE: BCM1_Kurvenlicht_links_Anf]";
CM_ SG_ 981 BCM1_CorneringLight_Right_Req "[DE: BCM1_Kurvenlicht_rechts_Anf]";
CM_ SG_ 981 BCM1_SideLight_Req "[DE: BCM1_Standlicht_Anf]";
CM_ SG_ 981 BCM1_LowBeam_Req "[DE: BCM1_Abblendlicht_Anf]";
CM_ SG_ 981 BCM1_HighBeam_Req "[DE: BCM1_Fernlicht_Anf]";
CM_ SG_ 981 BCM1_FogLight_Req "[DE: BCM1_Nebellicht_Anf]";
CM_ SG_ 981 BCM1_ParkingLight_Left_Req "[DE: BCM1_Parklicht_li_Anf]";
CM_ SG_ 981 BCM1_ParkingLight_Right_Req "[DE: BCM1_Parklicht_re_Anf]";
CM_ SG_ 981 BCM1_RearFog_Ahg_Req "[DE: BCM1_Nebelschluss_Ahg_Anf]";
CM_ SG_ 981 BCM1_RearFog_Veh_Req "[DE: BCM1_Nebelschluss_Fzg_Anf]";
CM_ SG_ 981 BCM1_TailLight_Req "[DE: BCM1_Schlusslicht_Anf]";
CM_ SG_ 981 BCM_ReversingLight_Req "[DE: BCM_Rueckfahrlicht_Anf]";
CM_ SG_ 981 BCM1_SignatureLight_Req "[DE: BCM1_Signaturlicht_Anf]";
CM_ SG_ 981 BCM1_Umfeldleuchten_Req "[DE: BCM1_Umfeldleuchten_Anf]";
CM_ SG_ 981 BCM1_DaytimeRunningLight_Req "[DE: BCM1_Tagfahrlicht_Anf]";
CM_ SG_ 981 BCM1_RainLight_Req "[DE: BCM1_Regenlicht_Anf]";
CM_ SG_ 981 BCM1_MotorwayLight_Req "[DE: BCM1_Autobahnlicht_Anf]";
CM_ SG_ 981 BCM1_Tourist_Light_Req "[DE: BCM1_Touristen_Licht_Anf]";
CM_ SG_ 981 BCM1_CH_Active "[DE: BCM1_CH_aktiv]";
CM_ SG_ 981 BCM1_LH_Active "[DE: BCM1_LH_aktiv]";
CM_ SG_ 981 BCM1_Sliding_Leuchtw_Req "[DE: BCM1_Gleitende_Leuchtw_Anf]";
CM_ SG_ 981 BCM1_GLW_HighBeam_Req "[DE: BCM1_GLW_Fernlicht_Anf]";
CM_ SG_ 981 BCM1_Adaptive_LightDistribution_Req "[DE: BCM1_Adaptive_Lichtvert_Anf]";
CM_ SG_ 981 BCM1_FoD_Blocking_WiBli "[DE: BCM1_FoD_Sperrung_WiBli]";
CM_ SG_ 981 BCM1_FOD_Blocking_Animations_HL "[DE: BCM1_FOD_Sperrung_Animationen_HL]";
CM_ SG_ 981 BCM1_CH_LH_Active "[DE: BCM1_CH_LH_aktiv]";
CM_ SG_ 981 BCM1_AllWeatherLight_Req "[DE: BCM1_Allwetterlicht_Anf]";
CM_ SG_ 981 BCM1_TailLight_Signature "[DE: BCM1_Schlusslicht_Signatur]";
CM_ SG_ 982 BCM2_BrakeLight_By_ECD "[DE: BCM2_Bremsl_durch_ECD]";
CM_ SG_ 982 LH_OutsideLight_def "[DE: LH_Aussenlicht_def]";
CM_ SG_ 982 LH_SideLight_H_Active "[DE: LH_Standlicht_H_aktiv]";
CM_ SG_ 982 LH_ParkingLight_HL_Active "[DE: LH_Parklicht_HL_aktiv]";
CM_ SG_ 982 LH_ParkingLight_HR_Active "[DE: LH_Parklicht_HR_aktiv]";
CM_ SG_ 982 LH_BrakeLight_H_Active "[DE: LH_Bremslicht_H_aktiv]";
CM_ SG_ 982 LH_RearFog_Active "[DE: LH_Nebelschluss_aktiv]";
CM_ SG_ 982 LH_ReversingLight_Active "[DE: LH_Rueckfahrlicht_aktiv]";
CM_ SG_ 982 LH_Indicator_HL_Act "[DE: LH_Blinker_HL_akt]";
CM_ SG_ 982 LH_Indicator_HR_Act "[DE: LH_Blinker_HR_akt]";
CM_ SG_ 982 LH_Indicator_Left_def "[DE: LH_Blinker_li_def]";
CM_ SG_ 982 LH_BrakeLight_Left_def "[DE: LH_Bremsl_li_def]";
CM_ SG_ 982 LH_TailLight_Left_def "[DE: LH_Schlusslicht_li_def]";
CM_ SG_ 982 LH_Reverse_Left_def "[DE: LH_Rueckf_li_def]";
CM_ SG_ 982 LH_Fog_Left_def "[DE: LH_Nebel_li_def]";
CM_ SG_ 982 LH_End_Brake_Fog_Left_def "[DE: LH_Schluss_Brems_Nebel_li_def]";
CM_ SG_ 982 LH_End_Brake_Fog_Right_def "[DE: LH_Schluss_Brems_Nebel_re_def]";
CM_ SG_ 982 LH_End_Brake_Left_def "[DE: LH_Schluss_Brems_li_def]";
CM_ SG_ 982 LH_End_Fog_Left_def "[DE: LH_Schluss_Nebel_li_def]";
CM_ SG_ 982 LH_SL_BRL_BLK_Left_def "[DE: LH_SL_BRL_BLK_li_def]";
CM_ SG_ 982 LH_Brake_Blk_Left_def "[DE: LH_Brems_Blk_li_def]";
CM_ SG_ 982 LH_Diag_Status_Right_def "[DE: LH_Diag_Status_re_def]";
CM_ SG_ 982 LH_Diag_Status_Left_def "[DE: LH_Diag_Status_li_def]";
CM_ SG_ 982 LH_Diag_LED_Left_def "[DE: LH_Diag_LED_li_def]";
CM_ SG_ 982 LH_Diag_LED_Right_def "[DE: LH_Diag_LED_re_def]";
CM_ SG_ 982 LH_Indicator_Right_def "[DE: LH_Blinker_re_def]";
CM_ SG_ 982 LH_BrakeLight_Right_def "[DE: LH_Bremsl_re_def]";
CM_ SG_ 982 LH_TailLight_Right_def "[DE: LH_Schlusslicht_re_def]";
CM_ SG_ 982 LH_Reverse_Right_def "[DE: LH_Rueckf_re_def]";
CM_ SG_ 982 LH_Fog_Right_def "[DE: LH_Nebel_re_def]";
CM_ SG_ 982 LH_End_Brake_mi_def "[DE: LH_Schluss_Brems_mi_def]";
CM_ SG_ 982 LH_End_Brake_Right_def "[DE: LH_Schluss_Brems_re_def]";
CM_ SG_ 982 LH_End_Fog_Right_def "[DE: LH_Schluss_Nebel_re_def]";
CM_ SG_ 982 LH_SL_BRL_BLK_Right_def "[DE: LH_SL_BRL_BLK_re_def]";
CM_ SG_ 982 LH_Brake_Blk_Right_def "[DE: LH_Brems_Blk_re_def]";
CM_ SG_ 982 LH_3_BrakeLight_def "[DE: LH_3_Bremsl_def]";
CM_ SG_ 982 LH_Fog_mi_def "[DE: LH_Nebel_mi_def]";
CM_ SG_ 982 LH_Reverse_mi_def "[DE: LH_Rueckf_mi_def]";
CM_ SG_ 982 LH_TailLight_mi_def "[DE: LH_Schlusslicht_mi_def]";
CM_ SG_ 982 LH_BrakeLight_mi_def "[DE: LH_Bremsl_mi_def]";
CM_ SG_ 982 LH_BrakeLight_Left_Total_def "[DE: LH_Bremsl_li_ges_def]";
CM_ SG_ 982 LH_BrakeLight_Right_Total_def "[DE: LH_Bremsl_re_ges_def]";
CM_ BO_ 167 "[DE: Motor_11]";
CM_ BO_ 168 "[DE: Motor_12]";
CM_ BO_ 173 "[DE: Getriebe_11]";
CM_ BO_ 332 "[DE: Motor_54]";
CM_ BO_ 518 "[DE: Parken_01]";
CM_ BO_ 706 "[DE: Motor_41]";
CM_ BO_ 850 "[DE: Parken_SM_03]";
CM_ BO_ 870 "[DE: Blinkmodi_02]";
CM_ BO_ 949 "[DE: Klima_11]";
CM_ BO_ 958 "[DE: Motor_14]";
CM_ BO_ 960 "[DE: Klemmen_Status_01]";
CM_ BO_ 967 "[DE: Motor_26]";
CM_ BO_ 974 "[DE: TSG_HFS_01]";
CM_ BO_ 975 "[DE: TSG_HBFS_01]";
CM_ BO_ 976 "[DE: TSG_FT_01]";
CM_ BO_ 981 "[DE: Licht_Anf_01]";
CM_ BO_ 982 "[DE: Licht_hinten_01]";
CM_ "English names by can2gauge tools/dbc/dbc_tool.py from opendbc vw_meb_2024_generated.dbc (MIT); the original German names are in the comments as [DE: ...]";
